VERSION ""

NS_ :

BS_:

BU_: BMS_Controller NF_Controller NF_Controllers

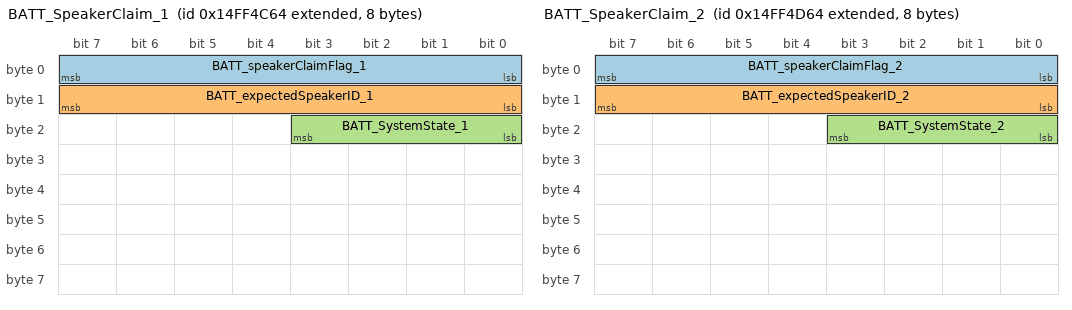
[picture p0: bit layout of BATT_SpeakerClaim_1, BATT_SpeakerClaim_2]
BO_ 2499759204 BATT_SpeakerClaim_1: 8 BMS_Controller
 SG_ BATT_speakerClaimFlag_1 : 0|8@1+ (1,0) [0|255] ""  BMS_Controller
 SG_ BATT_expectedSpeakerID_1 : 8|8@1+ (1,0) [0|255] ""  BMS_Controller
 SG_ BATT_SystemState_1 : 16|4@1+ (1,0) [0|15] ""  BMS_Controller

BO_ 2499759460 BATT_SpeakerClaim_2: 8 BMS_Controller
 SG_ BATT_speakerClaimFlag_2 : 0|8@1+ (1,0) [0|255] ""  BMS_Controller
 SG_ BATT_expectedSpeakerID_2 : 8|8@1+ (1,0) [0|255] ""  BMS_Controller
 SG_ BATT_SystemState_2 : 16|4@1+ (1,0) [0|15] ""  BMS_Controller

BO_ 2499756361 APP_PackId_Arbitration: 8 NF_Controller
 SG_ APP_PackId_Arbitration_Req : 0|8@1+ (1,0) [0|255] ""  BMS_Controller

BO_ 2499758692 BATT_Version: 8 BMS_Controller
 SG_ BATT_SwVerSubMinorApp m0 : 24|8@1+ (1,0) [0|255] ""  NF_Controller
 SG_ BATT_SwVerMinorApp m0 : 16|8@1+ (1,0) [0|255] ""  NF_Controller
 SG_ BATT_SwVerMajorApp m0 : 8|8@1+ (1,0) [0|255] ""  NF_Controller
 SG_ BATT_HwVerApp m0 : 32|8@1+ (1,0) [0|255] ""  NF_Controller
 SG_ BATT_SwVerAbsCusApp m0 : 40|8@1+ (1,0) [0|255] ""  NF_Controller
 SG_ BATT_SwVerAbsIntApp m0 : 48|8@1+ (1,0) [0|255] ""  NF_Controller
 SG_ BATT_SwVerSubMinorBl m1 : 24|8@1+ (1,0) [0|255] ""  NF_Controller
 SG_ BATT_SwVerMinorBl m1 : 16|8@1+ (1,0) [0|255] ""  NF_Controller
 SG_ BATT_SwVerMajorBl m1 : 8|8@1+ (1,0) [0|255] ""  NF_Controller
 SG_ BATT_HwVerBl m1 : 32|8@1+ (1,0) [0|255] ""  NF_Controller
 SG_ BATT_SwVerAbsCusBl m1 : 40|8@1+ (1,0) [0|255] ""  NF_Controller
 SG_ BATT_SwVerAbsIntBl m1 : 48|8@1+ (1,0) [0|255] ""  NF_Controller
 SG_ BATT_SwVerSubMinorCal m2 : 24|8@1+ (1,0) [0|255] ""  NF_Controller
 SG_ BATT_SwVerMinorCal m2 : 16|8@1+ (1,0) [0|255] ""  NF_Controller
 SG_ BATT_SwVerMajorCal m2 : 8|8@1+ (1,0) [0|255] ""  NF_Controller
 SG_ BATT_HwVerCal m2 : 32|8@1+ (1,0) [0|255] ""  NF_Controller
 SG_ BATT_SwVerAbsCusCal m2 : 40|8@1+ (1,0) [0|255] ""  NF_Controller
 SG_ BATT_SwVerAbsIntCal m2 : 48|8@1+ (1,0) [0|255] ""  NF_Controller
 SG_ multiplexorvr M : 0|2@1+ (1,0) [0|2] ""  NF_Controllers

BO_ 2499763812 BATT_Pack_Inhibition: 8 BMS_Controller
 SG_ BATT_01_inhibitionPyroFuse m0 : 11|1@1+ (1,0) [0|1] ""  NF_Controller
 SG_ BATT_01_inhibitionRegen m0 : 10|1@1+ (1,0) [0|1] ""  NF_Controller
 SG_ BATT_01_inhibitionFullPower m0 : 9|1@1+ (1,0) [0|1] ""  NF_Controller
 SG_ BATT_01_inhibitionRampDown m0 : 8|1@1+ (1,0) [0|1] ""  NF_Controller
 SG_ BATT_01_inhibitionDriveEntry m0 : 3|1@1+ (1,0) [0|1] ""  NF_Controller
 SG_ BATT_01_inhibitionDrive m0 : 2|1@1+ (1,0) [0|1] ""  NF_Controller
 SG_ BATT_01_inhibitionCharge m0 : 1|1@1+ (1,0) [0|1] ""  NF_Controller
 SG_ BATT_01_inhibitionChargeEntry m0 : 0|1@1+ (1,0) [0|1] ""  NF_Controller
 SG_ BATT_02_inhibitionPyroFuse m1 : 11|1@1+ (1,0) [0|1] ""  NF_Controller
 SG_ BATT_02_inhibitionRegen m1 : 10|1@1+ (1,0) [0|1] ""  NF_Controller
 SG_ BATT_02_inhibitionFullPower m1 : 9|1@1+ (1,0) [0|1] ""  NF_Controller
 SG_ BATT_02_inhibitionRampDown m1 : 8|1@1+ (1,0) [0|1] ""  NF_Controller
 SG_ BATT_02_inhibitionDriveEntry m1 : 3|1@1+ (1,0) [0|1] ""  NF_Controller
 SG_ BATT_02_inhibitionDrive m1 : 2|1@1+ (1,0) [0|1] ""  NF_Controller
 SG_ BATT_02_inhibitionCharge m1 : 1|1@1+ (1,0) [0|1] ""  NF_Controller
 SG_ BATT_02_inhibitionChargeEntry m1 : 0|1@1+ (1,0) [0|1] ""  NF_Controller
 SG_ BATT_03_inhibitionPyroFuse m2 : 11|1@1+ (1,0) [0|1] ""  NF_Controller
 SG_ BATT_03_inhibitionRegen m2 : 10|1@1+ (1,0) [0|1] ""  NF_Controller
 SG_ BATT_03_inhibitionFullPower m2 : 9|1@1+ (1,0) [0|1] ""  NF_Controller
 SG_ BATT_03_inhibitionRampDown m2 : 8|1@1+ (1,0) [0|1] ""  NF_Controller
 SG_ BATT_03_inhibitionDriveEntry m2 : 3|1@1+ (1,0) [0|1] ""  NF_Controller
 SG_ BATT_03_inhibitionDrive m2 : 2|1@1+ (1,0) [0|1] ""  NF_Controller
 SG_ BATT_03_inhibitionCharge m2 : 1|1@1+ (1,0) [0|1] ""  NF_Controller
 SG_ BATT_03_inhibitionChargeEntry m2 : 0|1@1+ (1,0) [0|1] ""  NF_Controller
 SG_ BATT_04_inhibitionPyroFuse m3 : 11|1@1+ (1,0) [0|1] ""  NF_Controller
 SG_ BATT_04_inhibitionRegen m3 : 10|1@1+ (1,0) [0|1] ""  NF_Controller
 SG_ BATT_04_inhibitionFullPower m3 : 9|1@1+ (1,0) [0|1] ""  NF_Controller
 SG_ BATT_04_inhibitionRampDown m3 : 8|1@1+ (1,0) [0|1] ""  NF_Controller
 SG_ BATT_04_inhibitionDriveEntry m3 : 3|1@1+ (1,0) [0|1] ""  NF_Controller
 SG_ BATT_04_inhibitionDrive m3 : 2|1@1+ (1,0) [0|1] ""  NF_Controller
 SG_ BATT_04_inhibitionCharge m3 : 1|1@1+ (1,0) [0|1] ""  NF_Controller
 SG_ BATT_04_inhibitionChargeEntry m3 : 0|1@1+ (1,0) [0|1] ""  NF_Controller
 SG_ BATT_05_inhibitionPyroFuse m4 : 11|1@1+ (1,0) [0|1] ""  NF_Controller
 SG_ BATT_05_inhibitionRegen m4 : 10|1@1+ (1,0) [0|1] ""  NF_Controller
 SG_ BATT_05_inhibitionFullPower m4 : 9|1@1+ (1,0) [0|1] ""  NF_Controller
 SG_ BATT_05_inhibitionRampDown m4 : 8|1@1+ (1,0) [0|1] ""  NF_Controller
 SG_ BATT_05_inhibitionDriveEntry m4 : 3|1@1+ (1,0) [0|1] ""  NF_Controller
 SG_ BATT_05_inhibitionDrive m4 : 2|1@1+ (1,0) [0|1] ""  NF_Controller
 SG_ BATT_05_inhibitionCharge m4 : 1|1@1+ (1,0) [0|1] ""  NF_Controller
 SG_ BATT_05_inhibitionChargeEntry m4 : 0|1@1+ (1,0) [0|1] ""  NF_Controller
 SG_ BATT_06_inhibitionPyroFuse m5 : 11|1@1+ (1,0) [0|1] ""  NF_Controller
 SG_ BATT_06_inhibitionRegen m5 : 10|1@1+ (1,0) [0|1] ""  NF_Controller
 SG_ BATT_06_inhibitionFullPower m5 : 9|1@1+ (1,0) [0|1] ""  NF_Controller
 SG_ BATT_06_inhibitionRampDown m5 : 8|1@1+ (1,0) [0|1] ""  NF_Controller
 SG_ BATT_06_inhibitionDriveEntry m5 : 3|1@1+ (1,0) [0|1] ""  NF_Controller
 SG_ BATT_06_inhibitionDrive m5 : 2|1@1+ (1,0) [0|1] ""  NF_Controller
 SG_ BATT_06_inhibitionCharge m5 : 1|1@1+ (1,0) [0|1] ""  NF_Controller
 SG_ BATT_06_inhibitionChargeEntry m5 : 0|1@1+ (1,0) [0|1] ""  NF_Controller
 SG_ BATT_07_inhibitionPyroFuse m6 : 11|1@1+ (1,0) [0|1] ""  NF_Controller
 SG_ BATT_07_inhibitionRegen m6 : 10|1@1+ (1,0) [0|1] ""  NF_Controller
 SG_ BATT_07_inhibitionFullPower m6 : 9|1@1+ (1,0) [0|1] ""  NF_Controller
 SG_ BATT_07_inhibitionRampDown m6 : 8|1@1+ (1,0) [0|1] ""  NF_Controller
 SG_ BATT_07_inhibitionDriveEntry m6 : 3|1@1+ (1,0) [0|1] ""  NF_Controller
 SG_ BATT_07_inhibitionDrive m6 : 2|1@1+ (1,0) [0|1] ""  NF_Controller
 SG_ BATT_07_inhibitionCharge m6 : 1|1@1+ (1,0) [0|1] ""  NF_Controller
 SG_ BATT_07_inhibitionChargeEntry m6 : 0|1@1+ (1,0) [0|1] ""  NF_Controller
 SG_ BATT_08_inhibitionPyroFuse m7 : 11|1@1+ (1,0) [0|1] ""  NF_Controller
 SG_ BATT_08_inhibitionRegen m7 : 10|1@1+ (1,0) [0|1] ""  NF_Controller
 SG_ BATT_08_inhibitionFullPower m7 : 9|1@1+ (1,0) [0|1] ""  NF_Controller
 SG_ BATT_08_inhibitionRampDown m7 : 8|1@1+ (1,0) [0|1] ""  NF_Controller
 SG_ BATT_08_inhibitionDriveEntry m7 : 3|1@1+ (1,0) [0|1] ""  NF_Controller
 SG_ BATT_08_inhibitionDrive m7 : 2|1@1+ (1,0) [0|1] ""  NF_Controller
 SG_ BATT_08_inhibitionCharge m7 : 1|1@1+ (1,0) [0|1] ""  NF_Controller
 SG_ BATT_08_inhibitionChargeEntry m7 : 0|1@1+ (1,0) [0|1] ""  NF_Controller
 SG_ BATT_09_inhibitionPyroFuse m8 : 11|1@1+ (1,0) [0|1] ""  NF_Controller
 SG_ BATT_09_inhibitionRegen m8 : 10|1@1+ (1,0) [0|1] ""  NF_Controller
 SG_ BATT_09_inhibitionFullPower m8 : 9|1@1+ (1,0) [0|1] ""  NF_Controller
 SG_ BATT_09_inhibitionRampDown m8 : 8|1@1+ (1,0) [0|1] ""  NF_Controller
 SG_ BATT_09_inhibitionDriveEntry m8 : 3|1@1+ (1,0) [0|1] ""  NF_Controller
 SG_ BATT_09_inhibitionDrive m8 : 2|1@1+ (1,0) [0|1] ""  NF_Controller
 SG_ BATT_09_inhibitionCharge m8 : 1|1@1+ (1,0) [0|1] ""  NF_Controller
 SG_ BATT_09_inhibitionChargeEntry m8 : 0|1@1+ (1,0) [0|1] ""  NF_Controller
 SG_ BATT_10_inhibitionPyroFuse m9 : 11|1@1+ (1,0) [0|1] ""  NF_Controller
 SG_ BATT_10_inhibitionRegen m9 : 10|1@1+ (1,0) [0|1] ""  NF_Controller
 SG_ BATT_10_inhibitionFullPower m9 : 9|1@1+ (1,0) [0|1] ""  NF_Controller
 SG_ BATT_10_inhibitionRampDown m9 : 8|1@1+ (1,0) [0|1] ""  NF_Controller
 SG_ BATT_10_inhibitionDriveEntry m9 : 3|1@1+ (1,0) [0|1] ""  NF_Controller
 SG_ BATT_10_inhibitionDrive m9 : 2|1@1+ (1,0) [0|1] ""  NF_Controller
 SG_ BATT_10_inhibitionCharge m9 : 1|1@1+ (1,0) [0|1] ""  NF_Controller
 SG_ BATT_10_inhibitionChargeEntry m9 : 0|1@1+ (1,0) [0|1] ""  NF_Controller
 SG_ BATT_packInhMux M : 4|4@1+ (1,0) [0|15] ""  NF_Controller

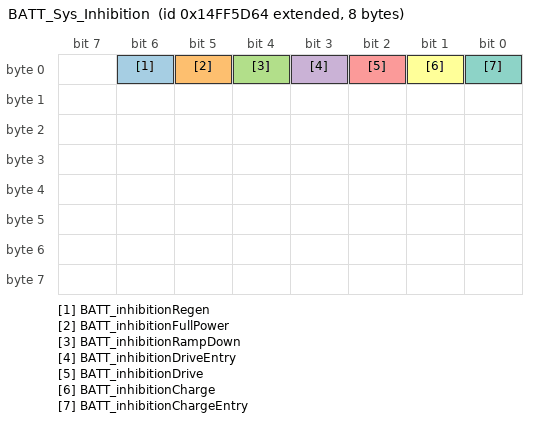
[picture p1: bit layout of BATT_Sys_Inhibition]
BO_ 2499763556 BATT_Sys_Inhibition: 8 BMS_Controller
 SG_ BATT_inhibitionRegen : 6|1@1+ (1,0) [0|1] ""  NF_Controller
 SG_ BATT_inhibitionFullPower : 5|1@1+ (1,0) [0|1] ""  NF_Controller
 SG_ BATT_inhibitionRampDown : 4|1@1+ (1,0) [0|1] ""  NF_Controller
 SG_ BATT_inhibitionDriveEntry : 3|1@1+ (1,0) [0|1] ""  NF_Controller
 SG_ BATT_inhibitionDrive : 2|1@1+ (1,0) [0|1] ""  NF_Controller
 SG_ BATT_inhibitionCharge : 1|1@1+ (1,0) [0|1] ""  NF_Controller
 SG_ BATT_inhibitionChargeEntry : 0|1@1+ (1,0) [0|1] ""  NF_Controller

BO_ 2499763300 BATT_Diagnostic_Pack_D: 8 BMS_Controller
 SG_ BATT_01_BusJoinFailed m0 : 10|2@1+ (1,0) [0|3] ""  NF_Controller
 SG_ BATT_01_ModuleThermFaultSevere m0 : 8|2@1+ (1,0) [0|3] ""  NF_Controller
 SG_ BATT_01_Placeholder11 m0 : 22|2@1+ (1,0) [0|3] ""  NF_Controller
 SG_ BATT_01_HardwareUvloError m0 : 20|2@1+ (1,0) [0|3] ""  NF_Controller
 SG_ BATT_01_iOverchargemod m0 : 46|2@1+ (1,0) [0|3] ""  NF_Controller
 SG_ BATT_01_afe_pwr_wire_open m0 : 44|2@1+ (1,0) [0|3] ""  NF_Controller
 SG_ BATT_01_HardwareOVError m0 : 18|2@1+ (1,0) [0|3] ""  NF_Controller
 SG_ BATT_01_DoubleDcContWeld m0 : 16|2@1+ (1,0) [0|3] ""  NF_Controller
 SG_ BATT_01_CurrentMismatch m0 : 30|2@1+ (1,0) [0|3] ""  NF_Controller
 SG_ BATT_01_vBrickImbalanceWar m0 : 28|2@1+ (1,0) [0|3] ""  NF_Controller
 SG_ BATT_01_vBrickImbalanceMod m0 : 26|2@1+ (1,0) [0|3] ""  NF_Controller
 SG_ BATT_01_vBrickImbalanceSev m0 : 24|2@1+ (1,0) [0|3] ""  NF_Controller
 SG_ BATT_01_Placeholder06 m0 : 38|2@1+ (1,0) [0|3] ""  NF_Controller
 SG_ BATT_01_iOverdischargewar m0 : 36|2@1+ (1,0) [0|3] ""  NF_Controller
 SG_ BATT_01_SpeakerMia m0 : 2|2@1+ (1,0) [0|3] ""  NF_Controller
 SG_ BATT_01_IsoSpiBreak m0 : 0|2@1+ (1,0) [0|3] ""  NF_Controller
 SG_ BATT_01_VersionMismatch m0 : 14|2@1+ (1,0) [0|3] ""  NF_Controller
 SG_ BATT_01_SystemPrechargeFail m0 : 12|2@1+ (1,0) [0|3] ""  NF_Controller
 SG_ BATT_01_iOverdischargemod m0 : 34|2@1+ (1,0) [0|3] ""  NF_Controller
 SG_ BATT_01_iOverchargeswar m0 : 32|2@1+ (1,0) [0|3] ""  NF_Controller
 SG_ BATT_02_BusJoinFailed m1 : 10|2@1+ (1,0) [0|3] ""  NF_Controller
 SG_ BATT_02_ModuleThermFaultSevere m1 : 8|2@1+ (1,0) [0|3] ""  NF_Controller
 SG_ BATT_02_Placeholder11 m1 : 22|2@1+ (1,0) [0|3] ""  NF_Controller
 SG_ BATT_02_HardwareUvloError m1 : 20|2@1+ (1,0) [0|3] ""  NF_Controller
 SG_ BATT_02_iOverchargemod m1 : 46|2@1+ (1,0) [0|3] ""  NF_Controller
 SG_ BATT_02_afe_pwr_wire_open m1 : 44|2@1+ (1,0) [0|3] ""  NF_Controller
 SG_ BATT_02_HardwareOVError m1 : 18|2@1+ (1,0) [0|3] ""  NF_Controller
 SG_ BATT_02_DoubleDcContWeld m1 : 16|2@1+ (1,0) [0|3] ""  NF_Controller
 SG_ BATT_02_CurrentMismatch m1 : 30|2@1+ (1,0) [0|3] ""  NF_Controller
 SG_ BATT_02_vBrickImbalanceWar m1 : 28|2@1+ (1,0) [0|3] ""  NF_Controller
 SG_ BATT_02_vBrickImbalanceMod m1 : 26|2@1+ (1,0) [0|3] ""  NF_Controller
 SG_ BATT_02_vBrickImbalanceSev m1 : 24|2@1+ (1,0) [0|3] ""  NF_Controller
 SG_ BATT_02_Placeholder06 m1 : 38|2@1+ (1,0) [0|3] ""  NF_Controller
 SG_ BATT_02_iOverdischargewar m1 : 36|2@1+ (1,0) [0|3] ""  NF_Controller
 SG_ BATT_02_SpeakerMia m1 : 2|2@1+ (1,0) [0|3] ""  NF_Controller
 SG_ BATT_02_IsoSpiBreak m1 : 0|2@1+ (1,0) [0|3] ""  NF_Controller
 SG_ BATT_02_VersionMismatch m1 : 14|2@1+ (1,0) [0|3] ""  NF_Controller
 SG_ BATT_02_SystemPrechargeFail m1 : 12|2@1+ (1,0) [0|3] ""  NF_Controller
 SG_ BATT_02_iOverdischargemod m1 : 34|2@1+ (1,0) [0|3] ""  NF_Controller
 SG_ BATT_02_iOverchargeswar m1 : 32|2@1+ (1,0) [0|3] ""  NF_Controller
 SG_ BATT_03_BusJoinFailed m2 : 10|2@1+ (1,0) [0|3] ""  NF_Controller
 SG_ BATT_03_ModuleThermFaultSevere m2 : 8|2@1+ (1,0) [0|3] ""  NF_Controller
 SG_ BATT_03_Placeholder11 m2 : 22|2@1+ (1,0) [0|3] ""  NF_Controller
 SG_ BATT_03_HardwareUvloError m2 : 20|2@1+ (1,0) [0|3] ""  NF_Controller
 SG_ BATT_03_iOverchargemod m2 : 46|2@1+ (1,0) [0|3] ""  NF_Controller
 SG_ BATT_03_afe_pwr_wire_open m2 : 44|2@1+ (1,0) [0|3] ""  NF_Controller
 SG_ BATT_03_HardwareOVError m2 : 18|2@1+ (1,0) [0|3] ""  NF_Controller
 SG_ BATT_03_DoubleDcContWeld m2 : 16|2@1+ (1,0) [0|3] ""  NF_Controller
 SG_ BATT_03_CurrentMismatch m2 : 30|2@1+ (1,0) [0|3] ""  NF_Controller
 SG_ BATT_03_vBrickImbalanceWar m2 : 28|2@1+ (1,0) [0|3] ""  NF_Controller
 SG_ BATT_03_vBrickImbalanceMod m2 : 26|2@1+ (1,0) [0|3] ""  NF_Controller
 SG_ BATT_03_vBrickImbalanceSev m2 : 24|2@1+ (1,0) [0|3] ""  NF_Controller
 SG_ BATT_03_Placeholder06 m2 : 38|2@1+ (1,0) [0|3] ""  NF_Controller
 SG_ BATT_03_iOverdischargewar m2 : 36|2@1+ (1,0) [0|3] ""  NF_Controller
 SG_ BATT_03_SpeakerMia m2 : 2|2@1+ (1,0) [0|3] ""  NF_Controller
 SG_ BATT_03_IsoSpiBreak m2 : 0|2@1+ (1,0) [0|3] ""  NF_Controller
 SG_ BATT_03_VersionMismatch m2 : 14|2@1+ (1,0) [0|3] ""  NF_Controller
 SG_ BATT_03_SystemPrechargeFail m2 : 12|2@1+ (1,0) [0|3] ""  NF_Controller
 SG_ BATT_03_iOverdischargemod m2 : 34|2@1+ (1,0) [0|3] ""  NF_Controller
 SG_ BATT_03_iOverchargeswar m2 : 32|2@1+ (1,0) [0|3] ""  NF_Controller
 SG_ BATT_04_BusJoinFailed m3 : 10|2@1+ (1,0) [0|3] ""  NF_Controller
 SG_ BATT_04_ModuleThermFaultSevere m3 : 8|2@1+ (1,0) [0|3] ""  NF_Controller
 SG_ BATT_04_Placeholder11 m3 : 22|2@1+ (1,0) [0|3] ""  NF_Controller
 SG_ BATT_04_HardwareUvloError m3 : 20|2@1+ (1,0) [0|3] ""  NF_Controller
 SG_ BATT_04_iOverchargemod m3 : 46|2@1+ (1,0) [0|3] ""  NF_Controller
 SG_ BATT_04_afe_pwr_wire_open m3 : 44|2@1+ (1,0) [0|3] ""  NF_Controller
 SG_ BATT_04_HardwareOVError m3 : 18|2@1+ (1,0) [0|3] ""  NF_Controller
 SG_ BATT_04_DoubleDcContWeld m3 : 16|2@1+ (1,0) [0|3] ""  NF_Controller
 SG_ BATT_04_CurrentMismatch m3 : 30|2@1+ (1,0) [0|3] ""  NF_Controller
 SG_ BATT_04_vBrickImbalanceWar m3 : 28|2@1+ (1,0) [0|3] ""  NF_Controller
 SG_ BATT_04_vBrickImbalanceMod m3 : 26|2@1+ (1,0) [0|3] ""  NF_Controller
 SG_ BATT_04_vBrickImbalanceSev m3 : 24|2@1+ (1,0) [0|3] ""  NF_Controller
 SG_ BATT_04_Placeholder06 m3 : 38|2@1+ (1,0) [0|3] ""  NF_Controller
 SG_ BATT_04_iOverdischargewar m3 : 36|2@1+ (1,0) [0|3] ""  NF_Controller
 SG_ BATT_04_SpeakerMia m3 : 2|2@1+ (1,0) [0|3] ""  NF_Controller
 SG_ BATT_04_IsoSpiBreak m3 : 0|2@1+ (1,0) [0|3] ""  NF_Controller
 SG_ BATT_04_VersionMismatch m3 : 14|2@1+ (1,0) [0|3] ""  NF_Controller
 SG_ BATT_04_SystemPrechargeFail m3 : 12|2@1+ (1,0) [0|3] ""  NF_Controller
 SG_ BATT_04_iOverdischargemod m3 : 34|2@1+ (1,0) [0|3] ""  NF_Controller
 SG_ BATT_04_iOverchargeswar m3 : 32|2@1+ (1,0) [0|3] ""  NF_Controller
 SG_ BATT_05_BusJoinFailed m4 : 10|2@1+ (1,0) [0|3] ""  NF_Controller
 SG_ BATT_05_ModuleThermFaultSevere m4 : 8|2@1+ (1,0) [0|3] ""  NF_Controller
 SG_ BATT_05_Placeholder11 m4 : 22|2@1+ (1,0) [0|3] ""  NF_Controller
 SG_ BATT_05_HardwareUvloError m4 : 20|2@1+ (1,0) [0|3] ""  NF_Controller
 SG_ BATT_05_iOverchargemod m4 : 46|2@1+ (1,0) [0|3] ""  NF_Controller
 SG_ BATT_05_afe_pwr_wire_open m4 : 44|2@1+ (1,0) [0|3] ""  NF_Controller
 SG_ BATT_05_HardwareOVError m4 : 18|2@1+ (1,0) [0|3] ""  NF_Controller
 SG_ BATT_05_DoubleDcContWeld m4 : 16|2@1+ (1,0) [0|3] ""  NF_Controller
 SG_ BATT_05_CurrentMismatch m4 : 30|2@1+ (1,0) [0|3] ""  NF_Controller
 SG_ BATT_05_vBrickImbalanceWar m4 : 28|2@1+ (1,0) [0|3] ""  NF_Controller
 SG_ BATT_05_vBrickImbalanceMod m4 : 26|2@1+ (1,0) [0|3] ""  NF_Controller
 SG_ BATT_05_vBrickImbalanceSev m4 : 24|2@1+ (1,0) [0|3] ""  NF_Controller
 SG_ BATT_05_Placeholder06 m4 : 38|2@1+ (1,0) [0|3] ""  NF_Controller
 SG_ BATT_05_iOverdischargewar m4 : 36|2@1+ (1,0) [0|3] ""  NF_Controller
 SG_ BATT_05_SpeakerMia m4 : 2|2@1+ (1,0) [0|3] ""  NF_Controller
 SG_ BATT_05_IsoSpiBreak m4 : 0|2@1+ (1,0) [0|3] ""  NF_Controller
 SG_ BATT_05_VersionMismatch m4 : 14|2@1+ (1,0) [0|3] ""  NF_Controller
 SG_ BATT_05_SystemPrechargeFail m4 : 12|2@1+ (1,0) [0|3] ""  NF_Controller
 SG_ BATT_05_iOverdischargemod m4 : 34|2@1+ (1,0) [0|3] ""  NF_Controller
 SG_ BATT_05_iOverchargeswar m4 : 32|2@1+ (1,0) [0|3] ""  NF_Controller
 SG_ BATT_06_BusJoinFailed m5 : 10|2@1+ (1,0) [0|3] ""  NF_Controller
 SG_ BATT_06_ModuleThermFaultSevere m5 : 8|2@1+ (1,0) [0|3] ""  NF_Controller
 SG_ BATT_06_Placeholder11 m5 : 22|2@1+ (1,0) [0|3] ""  NF_Controller
 SG_ BATT_06_HardwareUvloError m5 : 20|2@1+ (1,0) [0|3] ""  NF_Controller
 SG_ BATT_06_iOverchargemod m5 : 46|2@1+ (1,0) [0|3] ""  NF_Controller
 SG_ BATT_06_afe_pwr_wire_open m5 : 44|2@1+ (1,0) [0|3] ""  NF_Controller
 SG_ BATT_06_HardwareOVError m5 : 18|2@1+ (1,0) [0|3] ""  NF_Controller
 SG_ BATT_06_DoubleDcContWeld m5 : 16|2@1+ (1,0) [0|3] ""  NF_Controller
 SG_ BATT_06_CurrentMismatch m5 : 30|2@1+ (1,0) [0|3] ""  NF_Controller
 SG_ BATT_06_vBrickImbalanceWar m5 : 28|2@1+ (1,0) [0|3] ""  NF_Controller
 SG_ BATT_06_vBrickImbalanceMod m5 : 26|2@1+ (1,0) [0|3] ""  NF_Controller
 SG_ BATT_06_vBrickImbalanceSev m5 : 24|2@1+ (1,0) [0|3] ""  NF_Controller
 SG_ BATT_06_Placeholder06 m5 : 38|2@1+ (1,0) [0|3] ""  NF_Controller
 SG_ BATT_06_iOverdischargewar m5 : 36|2@1+ (1,0) [0|3] ""  NF_Controller
 SG_ BATT_06_SpeakerMia m5 : 2|2@1+ (1,0) [0|3] ""  NF_Controller
 SG_ BATT_06_IsoSpiBreak m5 : 0|2@1+ (1,0) [0|3] ""  NF_Controller
 SG_ BATT_06_VersionMismatch m5 : 14|2@1+ (1,0) [0|3] ""  NF_Controller
 SG_ BATT_06_SystemPrechargeFail m5 : 12|2@1+ (1,0) [0|3] ""  NF_Controller
 SG_ BATT_06_iOverdischargemod m5 : 34|2@1+ (1,0) [0|3] ""  NF_Controller
 SG_ BATT_06_iOverchargeswar m5 : 32|2@1+ (1,0) [0|3] ""  NF_Controller
 SG_ BATT_07_BusJoinFailed m6 : 10|2@1+ (1,0) [0|3] ""  NF_Controller
 SG_ BATT_07_ModuleThermFaultSevere m6 : 8|2@1+ (1,0) [0|3] ""  NF_Controller
 SG_ BATT_07_Placeholder11 m6 : 22|2@1+ (1,0) [0|3] ""  NF_Controller
 SG_ BATT_07_HardwareUvloError m6 : 20|2@1+ (1,0) [0|3] ""  NF_Controller
 SG_ BATT_07_iOverchargemod m6 : 46|2@1+ (1,0) [0|3] ""  NF_Controller
 SG_ BATT_07_afe_pwr_wire_open m6 : 44|2@1+ (1,0) [0|3] ""  NF_Controller
 SG_ BATT_07_HardwareOVError m6 : 18|2@1+ (1,0) [0|3] ""  NF_Controller
 SG_ BATT_07_DoubleDcContWeld m6 : 16|2@1+ (1,0) [0|3] ""  NF_Controller
 SG_ BATT_07_CurrentMismatch m6 : 30|2@1+ (1,0) [0|3] ""  NF_Controller
 SG_ BATT_07_vBrickImbalanceWar m6 : 28|2@1+ (1,0) [0|3] ""  NF_Controller
 SG_ BATT_07_vBrickImbalanceMod m6 : 26|2@1+ (1,0) [0|3] ""  NF_Controller
 SG_ BATT_07_vBrickImbalanceSev m6 : 24|2@1+ (1,0) [0|3] ""  NF_Controller
 SG_ BATT_07_Placeholder06 m6 : 38|2@1+ (1,0) [0|3] ""  NF_Controller
 SG_ BATT_07_iOverdischargewar m6 : 36|2@1+ (1,0) [0|3] ""  NF_Controller
 SG_ BATT_07_SpeakerMia m6 : 2|2@1+ (1,0) [0|3] ""  NF_Controller
 SG_ BATT_07_IsoSpiBreak m6 : 0|2@1+ (1,0) [0|3] ""  NF_Controller
 SG_ BATT_07_VersionMismatch m6 : 14|2@1+ (1,0) [0|3] ""  NF_Controller
 SG_ BATT_07_SystemPrechargeFail m6 : 12|2@1+ (1,0) [0|3] ""  NF_Controller
 SG_ BATT_07_iOverdischargemod m6 : 34|2@1+ (1,0) [0|3] ""  NF_Controller
 SG_ BATT_07_iOverchargeswar m6 : 32|2@1+ (1,0) [0|3] ""  NF_Controller
 SG_ BATT_08_BusJoinFailed m7 : 10|2@1+ (1,0) [0|3] ""  NF_Controller
 SG_ BATT_08_ModuleThermFaultSevere m7 : 8|2@1+ (1,0) [0|3] ""  NF_Controller
 SG_ BATT_08_Placeholder11 m7 : 22|2@1+ (1,0) [0|3] ""  NF_Controller
 SG_ BATT_08_HardwareUvloError m7 : 20|2@1+ (1,0) [0|3] ""  NF_Controller
 SG_ BATT_08_iOverchargemod m7 : 46|2@1+ (1,0) [0|3] ""  NF_Controller
 SG_ BATT_08_afe_pwr_wire_open m7 : 44|2@1+ (1,0) [0|3] ""  NF_Controller
 SG_ BATT_08_HardwareOVError m7 : 18|2@1+ (1,0) [0|3] ""  NF_Controller
 SG_ BATT_08_DoubleDcContWeld m7 : 16|2@1+ (1,0) [0|3] ""  NF_Controller
 SG_ BATT_08_CurrentMismatch m7 : 30|2@1+ (1,0) [0|3] ""  NF_Controller
 SG_ BATT_08_vBrickImbalanceWar m7 : 28|2@1+ (1,0) [0|3] ""  NF_Controller
 SG_ BATT_08_vBrickImbalanceMod m7 : 26|2@1+ (1,0) [0|3] ""  NF_Controller
 SG_ BATT_08_vBrickImbalanceSev m7 : 24|2@1+ (1,0) [0|3] ""  NF_Controller
 SG_ BATT_08_Placeholder06 m7 : 38|2@1+ (1,0) [0|3] ""  NF_Controller
 SG_ BATT_08_iOverdischargewar m7 : 36|2@1+ (1,0) [0|3] ""  NF_Controller
 SG_ BATT_08_SpeakerMia m7 : 2|2@1+ (1,0) [0|3] ""  NF_Controller
 SG_ BATT_08_IsoSpiBreak m7 : 0|2@1+ (1,0) [0|3] ""  NF_Controller
 SG_ BATT_08_VersionMismatch m7 : 14|2@1+ (1,0) [0|3] ""  NF_Controller
 SG_ BATT_08_SystemPrechargeFail m7 : 12|2@1+ (1,0) [0|3] ""  NF_Controller
 SG_ BATT_08_iOverdischargemod m7 : 34|2@1+ (1,0) [0|3] ""  NF_Controller
 SG_ BATT_08_iOverchargeswar m7 : 32|2@1+ (1,0) [0|3] ""  NF_Controller
 SG_ BATT_09_BusJoinFailed m8 : 10|2@1+ (1,0) [0|3] ""  NF_Controller
 SG_ BATT_09_ModuleThermFaultSevere m8 : 8|2@1+ (1,0) [0|3] ""  NF_Controller
 SG_ BATT_09_Placeholder11 m8 : 22|2@1+ (1,0) [0|3] ""  NF_Controller
 SG_ BATT_09_HardwareUvloError m8 : 20|2@1+ (1,0) [0|3] ""  NF_Controller
 SG_ BATT_09_iOverchargemod m8 : 46|2@1+ (1,0) [0|3] ""  NF_Controller
 SG_ BATT_09_afe_pwr_wire_open m8 : 44|2@1+ (1,0) [0|3] ""  NF_Controller
 SG_ BATT_09_HardwareOVError m8 : 18|2@1+ (1,0) [0|3] ""  NF_Controller
 SG_ BATT_09_DoubleDcContWeld m8 : 16|2@1+ (1,0) [0|3] ""  NF_Controller
 SG_ BATT_09_CurrentMismatch m8 : 30|2@1+ (1,0) [0|3] ""  NF_Controller
 SG_ BATT_09_vBrickImbalanceWar m8 : 28|2@1+ (1,0) [0|3] ""  NF_Controller
 SG_ BATT_09_vBrickImbalanceMod m8 : 26|2@1+ (1,0) [0|3] ""  NF_Controller
 SG_ BATT_09_vBrickImbalanceSev m8 : 24|2@1+ (1,0) [0|3] ""  NF_Controller
 SG_ BATT_09_Placeholder06 m8 : 38|2@1+ (1,0) [0|3] ""  NF_Controller
 SG_ BATT_09_iOverdischargewar m8 : 36|2@1+ (1,0) [0|3] ""  NF_Controller
 SG_ BATT_09_SpeakerMia m8 : 2|2@1+ (1,0) [0|3] ""  NF_Controller
 SG_ BATT_09_IsoSpiBreak m8 : 0|2@1+ (1,0) [0|3] ""  NF_Controller
 SG_ BATT_09_VersionMismatch m8 : 14|2@1+ (1,0) [0|3] ""  NF_Controller
 SG_ BATT_09_SystemPrechargeFail m8 : 12|2@1+ (1,0) [0|3] ""  NF_Controller
 SG_ BATT_09_iOverdischargemod m8 : 34|2@1+ (1,0) [0|3] ""  NF_Controller
 SG_ BATT_09_iOverchargeswar m8 : 32|2@1+ (1,0) [0|3] ""  NF_Controller
 SG_ BATT_10_BusJoinFailed m9 : 10|2@1+ (1,0) [0|3] ""  NF_Controller
 SG_ BATT_10_ModuleThermFaultSevere m9 : 8|2@1+ (1,0) [0|3] ""  NF_Controller
 SG_ BATT_10_Placeholder11 m9 : 22|2@1+ (1,0) [0|3] ""  NF_Controller
 SG_ BATT_10_HardwareUvloError m9 : 20|2@1+ (1,0) [0|3] ""  NF_Controller
 SG_ BATT_10_iOverchargemod m9 : 46|2@1+ (1,0) [0|3] ""  NF_Controller
 SG_ BATT_10_afe_pwr_wire_open m9 : 44|2@1+ (1,0) [0|3] ""  NF_Controller
 SG_ BATT_10_HardwareOVError m9 : 18|2@1+ (1,0) [0|3] ""  NF_Controller
 SG_ BATT_10_DoubleDcContWeld m9 : 16|2@1+ (1,0) [0|3] ""  NF_Controller
 SG_ BATT_10_CurrentMismatch m9 : 30|2@1+ (1,0) [0|3] ""  NF_Controller
 SG_ BATT_10_vBrickImbalanceWar m9 : 28|2@1+ (1,0) [0|3] ""  NF_Controller
 SG_ BATT_10_vBrickImbalanceMod m9 : 26|2@1+ (1,0) [0|3] ""  NF_Controller
 SG_ BATT_10_vBrickImbalanceSev m9 : 24|2@1+ (1,0) [0|3] ""  NF_Controller
 SG_ BATT_10_Placeholder06 m9 : 38|2@1+ (1,0) [0|3] ""  NF_Controller
 SG_ BATT_10_iOverdischargewar m9 : 36|2@1+ (1,0) [0|3] ""  NF_Controller
 SG_ BATT_10_SpeakerMia m9 : 2|2@1+ (1,0) [0|3] ""  NF_Controller
 SG_ BATT_10_IsoSpiBreak m9 : 0|2@1+ (1,0) [0|3] ""  NF_Controller
 SG_ BATT_10_VersionMismatch m9 : 14|2@1+ (1,0) [0|3] ""  NF_Controller
 SG_ BATT_10_SystemPrechargeFail m9 : 12|2@1+ (1,0) [0|3] ""  NF_Controller
 SG_ BATT_10_iOverdischargemod m9 : 34|2@1+ (1,0) [0|3] ""  NF_Controller
 SG_ BATT_10_iOverchargeswar m9 : 32|2@1+ (1,0) [0|3] ""  NF_Controller
 SG_ BATT_11_BusJoinFailed m10 : 10|2@1+ (1,0) [0|3] ""  NF_Controller
 SG_ BATT_11_ModuleThermFaultSevere m10 : 8|2@1+ (1,0) [0|3] ""  NF_Controller
 SG_ BATT_11_Placeholder11 m10 : 22|2@1+ (1,0) [0|3] ""  NF_Controller
 SG_ BATT_11_HardwareUvloError m10 : 20|2@1+ (1,0) [0|3] ""  NF_Controller
 SG_ BATT_11_iOverchargemod m10 : 46|2@1+ (1,0) [0|3] ""  NF_Controller
 SG_ BATT_11_afe_pwr_wire_open m10 : 44|2@1+ (1,0) [0|3] ""  NF_Controller
 SG_ BATT_11_HardwareOVError m10 : 18|2@1+ (1,0) [0|3] ""  NF_Controller
 SG_ BATT_11_DoubleDcContWeld m10 : 16|2@1+ (1,0) [0|3] ""  NF_Controller
 SG_ BATT_11_CurrentMismatch m10 : 30|2@1+ (1,0) [0|3] ""  NF_Controller
 SG_ BATT_11_vBrickImbalanceWar m10 : 28|2@1+ (1,0) [0|3] ""  NF_Controller
 SG_ BATT_11_vBrickImbalanceMod m10 : 26|2@1+ (1,0) [0|3] ""  NF_Controller
 SG_ BATT_11_vBrickImbalanceSev m10 : 24|2@1+ (1,0) [0|3] ""  NF_Controller
 SG_ BATT_11_Placeholder06 m10 : 38|2@1+ (1,0) [0|3] ""  NF_Controller
 SG_ BATT_11_iOverdischargewar m10 : 36|2@1+ (1,0) [0|3] ""  NF_Controller
 SG_ BATT_11_SpeakerMia m10 : 2|2@1+ (1,0) [0|3] ""  NF_Controller
 SG_ BATT_11_IsoSpiBreak m10 : 0|2@1+ (1,0) [0|3] ""  NF_Controller
 SG_ BATT_11_VersionMismatch m10 : 14|2@1+ (1,0) [0|3] ""  NF_Controller
 SG_ BATT_11_SystemPrechargeFail m10 : 12|2@1+ (1,0) [0|3] ""  NF_Controller
 SG_ BATT_11_iOverdischargemod m10 : 34|2@1+ (1,0) [0|3] ""  NF_Controller
 SG_ BATT_11_iOverchargeswar m10 : 32|2@1+ (1,0) [0|3] ""  NF_Controller
 SG_ BATT_12_BusJoinFailed m11 : 10|2@1+ (1,0) [0|3] ""  NF_Controller
 SG_ BATT_12_ModuleThermFaultSevere m11 : 8|2@1+ (1,0) [0|3] ""  NF_Controller
 SG_ BATT_12_Placeholder11 m11 : 22|2@1+ (1,0) [0|3] ""  NF_Controller
 SG_ BATT_12_HardwareUvloError m11 : 20|2@1+ (1,0) [0|3] ""  NF_Controller
 SG_ BATT_12_iOverchargemod m11 : 46|2@1+ (1,0) [0|3] ""  NF_Controller
 SG_ BATT_12_afe_pwr_wire_open m11 : 44|2@1+ (1,0) [0|3] ""  NF_Controller
 SG_ BATT_12_HardwareOVError m11 : 18|2@1+ (1,0) [0|3] ""  NF_Controller
 SG_ BATT_12_DoubleDcContWeld m11 : 16|2@1+ (1,0) [0|3] ""  NF_Controller
 SG_ BATT_12_CurrentMismatch m11 : 30|2@1+ (1,0) [0|3] ""  NF_Controller
 SG_ BATT_12_vBrickImbalanceWar m11 : 28|2@1+ (1,0) [0|3] ""  NF_Controller
 SG_ BATT_12_vBrickImbalanceMod m11 : 26|2@1+ (1,0) [0|3] ""  NF_Controller
 SG_ BATT_12_vBrickImbalanceSev m11 : 24|2@1+ (1,0) [0|3] ""  NF_Controller
 SG_ BATT_12_Placeholder06 m11 : 38|2@1+ (1,0) [0|3] ""  NF_Controller
 SG_ BATT_12_iOverdischargewar m11 : 36|2@1+ (1,0) [0|3] ""  NF_Controller
 SG_ BATT_12_SpeakerMia m11 : 2|2@1+ (1,0) [0|3] ""  NF_Controller
 SG_ BATT_12_IsoSpiBreak m11 : 0|2@1+ (1,0) [0|3] ""  NF_Controller
 SG_ BATT_12_VersionMismatch m11 : 14|2@1+ (1,0) [0|3] ""  NF_Controller
 SG_ BATT_12_SystemPrechargeFail m11 : 12|2@1+ (1,0) [0|3] ""  NF_Controller
 SG_ BATT_12_iOverdischargemod m11 : 34|2@1+ (1,0) [0|3] ""  NF_Controller
 SG_ BATT_12_iOverchargeswar m11 : 32|2@1+ (1,0) [0|3] ""  NF_Controller
 SG_ BATT_13_BusJoinFailed m12 : 10|2@1+ (1,0) [0|3] ""  NF_Controller
 SG_ BATT_13_ModuleThermFaultSevere m12 : 8|2@1+ (1,0) [0|3] ""  NF_Controller
 SG_ BATT_13_Placeholder11 m12 : 22|2@1+ (1,0) [0|3] ""  NF_Controller
 SG_ BATT_13_HardwareUvloError m12 : 20|2@1+ (1,0) [0|3] ""  NF_Controller
 SG_ BATT_13_iOverchargemod m12 : 46|2@1+ (1,0) [0|3] ""  NF_Controller
 SG_ BATT_13_afe_pwr_wire_open m12 : 44|2@1+ (1,0) [0|3] ""  NF_Controller
 SG_ BATT_13_HardwareOVError m12 : 18|2@1+ (1,0) [0|3] ""  NF_Controller
 SG_ BATT_13_DoubleDcContWeld m12 : 16|2@1+ (1,0) [0|3] ""  NF_Controller
 SG_ BATT_13_CurrentMismatch m12 : 30|2@1+ (1,0) [0|3] ""  NF_Controller
 SG_ BATT_13_vBrickImbalanceWar m12 : 28|2@1+ (1,0) [0|3] ""  NF_Controller
 SG_ BATT_13_vBrickImbalanceMod m12 : 26|2@1+ (1,0) [0|3] ""  NF_Controller
 SG_ BATT_13_vBrickImbalanceSev m12 : 24|2@1+ (1,0) [0|3] ""  NF_Controller
 SG_ BATT_13_Placeholder06 m12 : 38|2@1+ (1,0) [0|3] ""  NF_Controller
 SG_ BATT_13_iOverdischargewar m12 : 36|2@1+ (1,0) [0|3] ""  NF_Controller
 SG_ BATT_13_SpeakerMia m12 : 2|2@1+ (1,0) [0|3] ""  NF_Controller
 SG_ BATT_13_IsoSpiBreak m12 : 0|2@1+ (1,0) [0|3] ""  NF_Controller
 SG_ BATT_13_VersionMismatch m12 : 14|2@1+ (1,0) [0|3] ""  NF_Controller
 SG_ BATT_13_SystemPrechargeFail m12 : 12|2@1+ (1,0) [0|3] ""  NF_Controller
 SG_ BATT_13_iOverdischargemod m12 : 34|2@1+ (1,0) [0|3] ""  NF_Controller
 SG_ BATT_13_iOverchargeswar m12 : 32|2@1+ (1,0) [0|3] ""  NF_Controller
 SG_ BATT_14_BusJoinFailed m13 : 10|2@1+ (1,0) [0|3] ""  NF_Controller
 SG_ BATT_14_ModuleThermFaultSevere m13 : 8|2@1+ (1,0) [0|3] ""  NF_Controller
 SG_ BATT_14_Placeholder11 m13 : 22|2@1+ (1,0) [0|3] ""  NF_Controller
 SG_ BATT_14_HardwareUvloError m13 : 20|2@1+ (1,0) [0|3] ""  NF_Controller
 SG_ BATT_14_iOverchargemod m13 : 46|2@1+ (1,0) [0|3] ""  NF_Controller
 SG_ BATT_14_afe_pwr_wire_open m13 : 44|2@1+ (1,0) [0|3] ""  NF_Controller
 SG_ BATT_14_HardwareOVError m13 : 18|2@1+ (1,0) [0|3] ""  NF_Controller
 SG_ BATT_14_DoubleDcContWeld m13 : 16|2@1+ (1,0) [0|3] ""  NF_Controller
 SG_ BATT_14_CurrentMismatch m13 : 30|2@1+ (1,0) [0|3] ""  NF_Controller
 SG_ BATT_14_vBrickImbalanceWar m13 : 28|2@1+ (1,0) [0|3] ""  NF_Controller
 SG_ BATT_14_vBrickImbalanceMod m13 : 26|2@1+ (1,0) [0|3] ""  NF_Controller
 SG_ BATT_14_vBrickImbalanceSev m13 : 24|2@1+ (1,0) [0|3] ""  NF_Controller
 SG_ BATT_14_Placeholder06 m13 : 38|2@1+ (1,0) [0|3] ""  NF_Controller
 SG_ BATT_14_iOverdischargewar m13 : 36|2@1+ (1,0) [0|3] ""  NF_Controller
 SG_ BATT_14_SpeakerMia m13 : 2|2@1+ (1,0) [0|3] ""  NF_Controller
 SG_ BATT_14_IsoSpiBreak m13 : 0|2@1+ (1,0) [0|3] ""  NF_Controller
 SG_ BATT_14_VersionMismatch m13 : 14|2@1+ (1,0) [0|3] ""  NF_Controller
 SG_ BATT_14_SystemPrechargeFail m13 : 12|2@1+ (1,0) [0|3] ""  NF_Controller
 SG_ BATT_14_iOverdischargemod m13 : 34|2@1+ (1,0) [0|3] ""  NF_Controller
 SG_ BATT_14_iOverchargeswar m13 : 32|2@1+ (1,0) [0|3] ""  NF_Controller
 SG_ BATT_15_BusJoinFailed m14 : 10|2@1+ (1,0) [0|3] ""  NF_Controller
 SG_ BATT_15_ModuleThermFaultSevere m14 : 8|2@1+ (1,0) [0|3] ""  NF_Controller
 SG_ BATT_15_Placeholder11 m14 : 22|2@1+ (1,0) [0|3] ""  NF_Controller
 SG_ BATT_15_HardwareUvloError m14 : 20|2@1+ (1,0) [0|3] ""  NF_Controller
 SG_ BATT_15_iOverchargemod m14 : 46|2@1+ (1,0) [0|3] ""  NF_Controller
 SG_ BATT_15_afe_pwr_wire_open m14 : 44|2@1+ (1,0) [0|3] ""  NF_Controller
 SG_ BATT_15_HardwareOVError m14 : 18|2@1+ (1,0) [0|3] ""  NF_Controller
 SG_ BATT_15_DoubleDcContWeld m14 : 16|2@1+ (1,0) [0|3] ""  NF_Controller
 SG_ BATT_15_CurrentMismatch m14 : 30|2@1+ (1,0) [0|3] ""  NF_Controller
 SG_ BATT_15_vBrickImbalanceWar m14 : 28|2@1+ (1,0) [0|3] ""  NF_Controller
 SG_ BATT_15_vBrickImbalanceMod m14 : 26|2@1+ (1,0) [0|3] ""  NF_Controller
 SG_ BATT_15_vBrickImbalanceSev m14 : 24|2@1+ (1,0) [0|3] ""  NF_Controller
 SG_ BATT_15_Placeholder06 m14 : 38|2@1+ (1,0) [0|3] ""  NF_Controller
 SG_ BATT_15_iOverdischargewar m14 : 36|2@1+ (1,0) [0|3] ""  NF_Controller
 SG_ BATT_15_SpeakerMia m14 : 2|2@1+ (1,0) [0|3] ""  NF_Controller
 SG_ BATT_15_IsoSpiBreak m14 : 0|2@1+ (1,0) [0|3] ""  NF_Controller
 SG_ BATT_15_VersionMismatch m14 : 14|2@1+ (1,0) [0|3] ""  NF_Controller
 SG_ BATT_15_SystemPrechargeFail m14 : 12|2@1+ (1,0) [0|3] ""  NF_Controller
 SG_ BATT_15_iOverdischargemod m14 : 34|2@1+ (1,0) [0|3] ""  NF_Controller
 SG_ BATT_15_iOverchargeswar m14 : 32|2@1+ (1,0) [0|3] ""  NF_Controller
 SG_ multiplexor_batt_diag_D M : 4|4@1+ (1,0) [0|15] ""  NF_Controller

BO_ 2499763044 BATT_Diagnostic_Pack_C: 8 BMS_Controller
 SG_ BATT_01_PackVoltageImbalance m0 : 58|2@1+ (1,0) [0|3] ""  NF_Controller
 SG_ BATT_01_PrechargeOvercurrentPri m0 : 56|2@1+ (1,0) [0|3] ""  NF_Controller
 SG_ BATT_01_HVILvoltageError m0 : 2|2@1+ (1,0) [0|3] ""  NF_Controller
 SG_ BATT_01_HVILcurrentReturnError m0 : 0|2@1+ (1,0) [0|3] ""  NF_Controller
 SG_ BATT_01_PosDcContWeldedSec m0 : 14|2@1+ (1,0) [0|3] ""  NF_Controller
 SG_ BATT_01_PosDcContStuckOpenSec m0 : 12|2@1+ (1,0) [0|3] ""  NF_Controller
 SG_ BATT_01_NegDcContWeldedSec m0 : 10|2@1+ (1,0) [0|3] ""  NF_Controller
 SG_ BATT_01_NegDcContStuckOpenSec m0 : 8|2@1+ (1,0) [0|3] ""  NF_Controller
 SG_ BATT_01_IsolationIntFault m0 : 20|2@1+ (1,0) [0|3] ""  NF_Controller
 SG_ BATT_01_IsolationExtFault m0 : 18|2@1+ (1,0) [0|3] ""  NF_Controller
 SG_ BATT_01_event_12v_filter_error m0 : 16|2@1+ (1,0) [0|3] ""  NF_Controller
 SG_ BATT_01_event_hall_eff_hi_rang_e m0 : 30|2@1+ (1,0) [0|3] ""  NF_Controller
 SG_ BATT_01_event_brick_volt_sns_ope m0 : 28|2@1+ (1,0) [0|3] ""  NF_Controller
 SG_ BATT_01_event_5v_error m0 : 26|2@1+ (1,0) [0|3] ""  NF_Controller
 SG_ BATT_01_event_3_3_hot_error m0 : 24|2@1+ (1,0) [0|3] ""  NF_Controller
 SG_ BATT_01_event_12v_input_error m0 : 38|2@1+ (1,0) [0|3] ""  NF_Controller
 SG_ BATT_01_event_1_25v_error m0 : 36|2@1+ (1,0) [0|3] ""  NF_Controller
 SG_ BATT_01_event_shunt_MIA m0 : 34|2@1+ (1,0) [0|3] ""  NF_Controller
 SG_ BATT_01_event_SBC_int_reg_error m0 : 32|2@1+ (1,0) [0|3] ""  NF_Controller
 SG_ BATT_01_event_pos_3_3v_analog_er m0 : 46|2@1+ (1,0) [0|3] ""  NF_Controller
 SG_ BATT_01_event_outlt_clnt_thrm_op m0 : 44|2@1+ (1,0) [0|3] ""  NF_Controller
 SG_ BATT_01_event_neg_3_3_analog_err m0 : 42|2@1+ (1,0) [0|3] ""  NF_Controller
 SG_ BATT_01_event_inlet_clnt_thrm_op m0 : 40|2@1+ (1,0) [0|3] ""  NF_Controller
 SG_ BATT_01_event_hall_eff_lo_rang_e m0 : 54|2@1+ (1,0) [0|3] ""  NF_Controller
 SG_ BATT_01_event_outlt_clnt_thrm_sh m0 : 52|2@1+ (1,0) [0|3] ""  NF_Controller
 SG_ BATT_01_event_inlet_clnt_thrm_sh m0 : 50|2@1+ (1,0) [0|3] ""  NF_Controller
 SG_ BATT_01_event_3_3v_error m0 : 48|2@1+ (1,0) [0|3] ""  NF_Controller
 SG_ BATT_02_PackVoltageImbalance m1 : 58|2@1+ (1,0) [0|3] ""  NF_Controller
 SG_ BATT_02_PrechargeOvercurrentPri m1 : 56|2@1+ (1,0) [0|3] ""  NF_Controller
 SG_ BATT_02_HVILvoltageError m1 : 2|2@1+ (1,0) [0|3] ""  NF_Controller
 SG_ BATT_02_HVILcurrentReturnError m1 : 0|2@1+ (1,0) [0|3] ""  NF_Controller
 SG_ BATT_02_PosDcContWeldedSec m1 : 14|2@1+ (1,0) [0|3] ""  NF_Controller
 SG_ BATT_02_PosDcContStuckOpenSec m1 : 12|2@1+ (1,0) [0|3] ""  NF_Controller
 SG_ BATT_02_NegDcContWeldedSec m1 : 10|2@1+ (1,0) [0|3] ""  NF_Controller
 SG_ BATT_02_NegDcContStuckOpenSec m1 : 8|2@1+ (1,0) [0|3] ""  NF_Controller
 SG_ BATT_02_IsolationIntFault m1 : 20|2@1+ (1,0) [0|3] ""  NF_Controller
 SG_ BATT_02_IsolationExtFault m1 : 18|2@1+ (1,0) [0|3] ""  NF_Controller
 SG_ BATT_02_event_12v_filter_error m1 : 16|2@1+ (1,0) [0|3] ""  NF_Controller
 SG_ BATT_02_event_hall_eff_hi_rang_e m1 : 30|2@1+ (1,0) [0|3] ""  NF_Controller
 SG_ BATT_02_event_brick_volt_sns_ope m1 : 28|2@1+ (1,0) [0|3] ""  NF_Controller
 SG_ BATT_02_event_5v_error m1 : 26|2@1+ (1,0) [0|3] ""  NF_Controller
 SG_ BATT_02_event_3_3_hot_error m1 : 24|2@1+ (1,0) [0|3] ""  NF_Controller
 SG_ BATT_02_event_12v_input_error m1 : 38|2@1+ (1,0) [0|3] ""  NF_Controller
 SG_ BATT_02_event_1_25v_error m1 : 36|2@1+ (1,0) [0|3] ""  NF_Controller
 SG_ BATT_02_event_shunt_MIA m1 : 34|2@1+ (1,0) [0|3] ""  NF_Controller
 SG_ BATT_02_event_SBC_int_reg_error m1 : 32|2@1+ (1,0) [0|3] ""  NF_Controller
 SG_ BATT_02_event_pos_3_3v_analog_er m1 : 46|2@1+ (1,0) [0|3] ""  NF_Controller
 SG_ BATT_02_event_outlt_clnt_thrm_op m1 : 44|2@1+ (1,0) [0|3] ""  NF_Controller
 SG_ BATT_02_event_neg_3_3_analog_err m1 : 42|2@1+ (1,0) [0|3] ""  NF_Controller
 SG_ BATT_02_event_inlet_clnt_thrm_op m1 : 40|2@1+ (1,0) [0|3] ""  NF_Controller
 SG_ BATT_02_event_hall_eff_lo_rang_e m1 : 54|2@1+ (1,0) [0|3] ""  NF_Controller
 SG_ BATT_02_event_outlt_clnt_thrm_sh m1 : 52|2@1+ (1,0) [0|3] ""  NF_Controller
 SG_ BATT_02_event_inlet_clnt_thrm_sh m1 : 50|2@1+ (1,0) [0|3] ""  NF_Controller
 SG_ BATT_02_event_3_3v_error m1 : 48|2@1+ (1,0) [0|3] ""  NF_Controller
 SG_ BATT_03_PackVoltageImbalance m2 : 58|2@1+ (1,0) [0|3] ""  NF_Controller
 SG_ BATT_03_PrechargeOvercurrentPri m2 : 56|2@1+ (1,0) [0|3] ""  NF_Controller
 SG_ BATT_03_HVILvoltageError m2 : 2|2@1+ (1,0) [0|3] ""  NF_Controller
 SG_ BATT_03_HVILcurrentReturnError m2 : 0|2@1+ (1,0) [0|3] ""  NF_Controller
 SG_ BATT_03_PosDcContWeldedSec m2 : 14|2@1+ (1,0) [0|3] ""  NF_Controller
 SG_ BATT_03_PosDcContStuckOpenSec m2 : 12|2@1+ (1,0) [0|3] ""  NF_Controller
 SG_ BATT_03_NegDcContWeldedSec m2 : 10|2@1+ (1,0) [0|3] ""  NF_Controller
 SG_ BATT_03_NegDcContStuckOpenSec m2 : 8|2@1+ (1,0) [0|3] ""  NF_Controller
 SG_ BATT_03_IsolationIntFault m2 : 20|2@1+ (1,0) [0|3] ""  NF_Controller
 SG_ BATT_03_IsolationExtFault m2 : 18|2@1+ (1,0) [0|3] ""  NF_Controller
 SG_ BATT_03_event_12v_filter_error m2 : 16|2@1+ (1,0) [0|3] ""  NF_Controller
 SG_ BATT_03_event_hall_eff_hi_rang_e m2 : 30|2@1+ (1,0) [0|3] ""  NF_Controller
 SG_ BATT_03_event_brick_volt_sns_ope m2 : 28|2@1+ (1,0) [0|3] ""  NF_Controller
 SG_ BATT_03_event_5v_error m2 : 26|2@1+ (1,0) [0|3] ""  NF_Controller
 SG_ BATT_03_event_3_3_hot_error m2 : 24|2@1+ (1,0) [0|3] ""  NF_Controller
 SG_ BATT_03_event_12v_input_error m2 : 38|2@1+ (1,0) [0|3] ""  NF_Controller
 SG_ BATT_03_event_1_25v_error m2 : 36|2@1+ (1,0) [0|3] ""  NF_Controller
 SG_ BATT_03_event_shunt_MIA m2 : 34|2@1+ (1,0) [0|3] ""  NF_Controller
 SG_ BATT_03_event_SBC_int_reg_error m2 : 32|2@1+ (1,0) [0|3] ""  NF_Controller
 SG_ BATT_03_event_pos_3_3v_analog_er m2 : 46|2@1+ (1,0) [0|3] ""  NF_Controller
 SG_ BATT_03_event_outlt_clnt_thrm_op m2 : 44|2@1+ (1,0) [0|3] ""  NF_Controller
 SG_ BATT_03_event_neg_3_3_analog_err m2 : 42|2@1+ (1,0) [0|3] ""  NF_Controller
 SG_ BATT_03_event_inlet_clnt_thrm_op m2 : 40|2@1+ (1,0) [0|3] ""  NF_Controller
 SG_ BATT_03_event_hall_eff_lo_rang_e m2 : 54|2@1+ (1,0) [0|3] ""  NF_Controller
 SG_ BATT_03_event_outlt_clnt_thrm_sh m2 : 52|2@1+ (1,0) [0|3] ""  NF_Controller
 SG_ BATT_03_event_inlet_clnt_thrm_sh m2 : 50|2@1+ (1,0) [0|3] ""  NF_Controller
 SG_ BATT_03_event_3_3v_error m2 : 48|2@1+ (1,0) [0|3] ""  NF_Controller
 SG_ BATT_04_PackVoltageImbalance m3 : 58|2@1+ (1,0) [0|3] ""  NF_Controller
 SG_ BATT_04_PrechargeOvercurrentPri m3 : 56|2@1+ (1,0) [0|3] ""  NF_Controller
 SG_ BATT_04_HVILvoltageError m3 : 2|2@1+ (1,0) [0|3] ""  NF_Controller
 SG_ BATT_04_HVILcurrentReturnError m3 : 0|2@1+ (1,0) [0|3] ""  NF_Controller
 SG_ BATT_04_PosDcContWeldedSec m3 : 14|2@1+ (1,0) [0|3] ""  NF_Controller
 SG_ BATT_04_PosDcContStuckOpenSec m3 : 12|2@1+ (1,0) [0|3] ""  NF_Controller
 SG_ BATT_04_NegDcContWeldedSec m3 : 10|2@1+ (1,0) [0|3] ""  NF_Controller
 SG_ BATT_04_NegDcContStuckOpenSec m3 : 8|2@1+ (1,0) [0|3] ""  NF_Controller
 SG_ BATT_04_IsolationIntFault m3 : 20|2@1+ (1,0) [0|3] ""  NF_Controller
 SG_ BATT_04_IsolationExtFault m3 : 18|2@1+ (1,0) [0|3] ""  NF_Controller
 SG_ BATT_04_event_12v_filter_error m3 : 16|2@1+ (1,0) [0|3] ""  NF_Controller
 SG_ BATT_04_event_hall_eff_hi_rang_e m3 : 30|2@1+ (1,0) [0|3] ""  NF_Controller
 SG_ BATT_04_event_brick_volt_sns_ope m3 : 28|2@1+ (1,0) [0|3] ""  NF_Controller
 SG_ BATT_04_event_5v_error m3 : 26|2@1+ (1,0) [0|3] ""  NF_Controller
 SG_ BATT_04_event_3_3_hot_error m3 : 24|2@1+ (1,0) [0|3] ""  NF_Controller
 SG_ BATT_04_event_12v_input_error m3 : 38|2@1+ (1,0) [0|3] ""  NF_Controller
 SG_ BATT_04_event_1_25v_error m3 : 36|2@1+ (1,0) [0|3] ""  NF_Controller
 SG_ BATT_04_event_shunt_MIA m3 : 34|2@1+ (1,0) [0|3] ""  NF_Controller
 SG_ BATT_04_event_SBC_int_reg_error m3 : 32|2@1+ (1,0) [0|3] ""  NF_Controller
 SG_ BATT_04_event_pos_3_3v_analog_er m3 : 46|2@1+ (1,0) [0|3] ""  NF_Controller
 SG_ BATT_04_event_outlt_clnt_thrm_op m3 : 44|2@1+ (1,0) [0|3] ""  NF_Controller
 SG_ BATT_04_event_neg_3_3_analog_err m3 : 42|2@1+ (1,0) [0|3] ""  NF_Controller
 SG_ BATT_04_event_inlet_clnt_thrm_op m3 : 40|2@1+ (1,0) [0|3] ""  NF_Controller
 SG_ BATT_04_event_hall_eff_lo_rang_e m3 : 54|2@1+ (1,0) [0|3] ""  NF_Controller
 SG_ BATT_04_event_outlt_clnt_thrm_sh m3 : 52|2@1+ (1,0) [0|3] ""  NF_Controller
 SG_ BATT_04_event_inlet_clnt_thrm_sh m3 : 50|2@1+ (1,0) [0|3] ""  NF_Controller
 SG_ BATT_04_event_3_3v_error m3 : 48|2@1+ (1,0) [0|3] ""  NF_Controller
 SG_ BATT_05_PackVoltageImbalance m4 : 58|2@1+ (1,0) [0|3] ""  NF_Controller
 SG_ BATT_05_PrechargeOvercurrentPri m4 : 56|2@1+ (1,0) [0|3] ""  NF_Controller
 SG_ BATT_05_HVILvoltageError m4 : 2|2@1+ (1,0) [0|3] ""  NF_Controller
 SG_ BATT_05_HVILcurrentReturnError m4 : 0|2@1+ (1,0) [0|3] ""  NF_Controller
 SG_ BATT_05_PosDcContWeldedSec m4 : 14|2@1+ (1,0) [0|3] ""  NF_Controller
 SG_ BATT_05_PosDcContStuckOpenSec m4 : 12|2@1+ (1,0) [0|3] ""  NF_Controller
 SG_ BATT_05_NegDcContWeldedSec m4 : 10|2@1+ (1,0) [0|3] ""  NF_Controller
 SG_ BATT_05_NegDcContStuckOpenSec m4 : 8|2@1+ (1,0) [0|3] ""  NF_Controller
 SG_ BATT_05_IsolationIntFault m4 : 20|2@1+ (1,0) [0|3] ""  NF_Controller
 SG_ BATT_05_IsolationExtFault m4 : 18|2@1+ (1,0) [0|3] ""  NF_Controller
 SG_ BATT_05_event_12v_filter_error m4 : 16|2@1+ (1,0) [0|3] ""  NF_Controller
 SG_ BATT_05_event_hall_eff_hi_rang_e m4 : 30|2@1+ (1,0) [0|3] ""  NF_Controller
 SG_ BATT_05_event_brick_volt_sns_ope m4 : 28|2@1+ (1,0) [0|3] ""  NF_Controller
 SG_ BATT_05_event_5v_error m4 : 26|2@1+ (1,0) [0|3] ""  NF_Controller
 SG_ BATT_05_event_3_3_hot_error m4 : 24|2@1+ (1,0) [0|3] ""  NF_Controller
 SG_ BATT_05_event_12v_input_error m4 : 38|2@1+ (1,0) [0|3] ""  NF_Controller
 SG_ BATT_05_event_1_25v_error m4 : 36|2@1+ (1,0) [0|3] ""  NF_Controller
 SG_ BATT_05_event_shunt_MIA m4 : 34|2@1+ (1,0) [0|3] ""  NF_Controller
 SG_ BATT_05_event_SBC_int_reg_error m4 : 32|2@1+ (1,0) [0|3] ""  NF_Controller
 SG_ BATT_05_event_pos_3_3v_analog_er m4 : 46|2@1+ (1,0) [0|3] ""  NF_Controller
 SG_ BATT_05_event_outlt_clnt_thrm_op m4 : 44|2@1+ (1,0) [0|3] ""  NF_Controller
 SG_ BATT_05_event_neg_3_3_analog_err m4 : 42|2@1+ (1,0) [0|3] ""  NF_Controller
 SG_ BATT_05_event_inlet_clnt_thrm_op m4 : 40|2@1+ (1,0) [0|3] ""  NF_Controller
 SG_ BATT_05_event_hall_eff_lo_rang_e m4 : 54|2@1+ (1,0) [0|3] ""  NF_Controller
 SG_ BATT_05_event_outlt_clnt_thrm_sh m4 : 52|2@1+ (1,0) [0|3] ""  NF_Controller
 SG_ BATT_05_event_inlet_clnt_thrm_sh m4 : 50|2@1+ (1,0) [0|3] ""  NF_Controller
 SG_ BATT_05_event_3_3v_error m4 : 48|2@1+ (1,0) [0|3] ""  NF_Controller
 SG_ BATT_06_PackVoltageImbalance m5 : 58|2@1+ (1,0) [0|3] ""  NF_Controller
 SG_ BATT_06_PrechargeOvercurrentPri m5 : 56|2@1+ (1,0) [0|3] ""  NF_Controller
 SG_ BATT_06_HVILvoltageError m5 : 2|2@1+ (1,0) [0|3] ""  NF_Controller
 SG_ BATT_06_HVILcurrentReturnError m5 : 0|2@1+ (1,0) [0|3] ""  NF_Controller
 SG_ BATT_06_PosDcContWeldedSec m5 : 14|2@1+ (1,0) [0|3] ""  NF_Controller
 SG_ BATT_06_PosDcContStuckOpenSec m5 : 12|2@1+ (1,0) [0|3] ""  NF_Controller
 SG_ BATT_06_NegDcContWeldedSec m5 : 10|2@1+ (1,0) [0|3] ""  NF_Controller
 SG_ BATT_06_NegDcContStuckOpenSec m5 : 8|2@1+ (1,0) [0|3] ""  NF_Controller
 SG_ BATT_06_IsolationIntFault m5 : 20|2@1+ (1,0) [0|3] ""  NF_Controller
 SG_ BATT_06_IsolationExtFault m5 : 18|2@1+ (1,0) [0|3] ""  NF_Controller
 SG_ BATT_06_event_12v_filter_error m5 : 16|2@1+ (1,0) [0|3] ""  NF_Controller
 SG_ BATT_06_event_hall_eff_hi_rang_e m5 : 30|2@1+ (1,0) [0|3] ""  NF_Controller
 SG_ BATT_06_event_brick_volt_sns_ope m5 : 28|2@1+ (1,0) [0|3] ""  NF_Controller
 SG_ BATT_06_event_5v_error m5 : 26|2@1+ (1,0) [0|3] ""  NF_Controller
 SG_ BATT_06_event_3_3_hot_error m5 : 24|2@1+ (1,0) [0|3] ""  NF_Controller
 SG_ BATT_06_event_12v_input_error m5 : 38|2@1+ (1,0) [0|3] ""  NF_Controller
 SG_ BATT_06_event_1_25v_error m5 : 36|2@1+ (1,0) [0|3] ""  NF_Controller
 SG_ BATT_06_event_shunt_MIA m5 : 34|2@1+ (1,0) [0|3] ""  NF_Controller
 SG_ BATT_06_event_SBC_int_reg_error m5 : 32|2@1+ (1,0) [0|3] ""  NF_Controller
 SG_ BATT_06_event_pos_3_3v_analog_er m5 : 46|2@1+ (1,0) [0|3] ""  NF_Controller
 SG_ BATT_06_event_outlt_clnt_thrm_op m5 : 44|2@1+ (1,0) [0|3] ""  NF_Controller
 SG_ BATT_06_event_neg_3_3_analog_err m5 : 42|2@1+ (1,0) [0|3] ""  NF_Controller
 SG_ BATT_06_event_inlet_clnt_thrm_op m5 : 40|2@1+ (1,0) [0|3] ""  NF_Controller
 SG_ BATT_06_event_hall_eff_lo_rang_e m5 : 54|2@1+ (1,0) [0|3] ""  NF_Controller
 SG_ BATT_06_event_outlt_clnt_thrm_sh m5 : 52|2@1+ (1,0) [0|3] ""  NF_Controller
 SG_ BATT_06_event_inlet_clnt_thrm_sh m5 : 50|2@1+ (1,0) [0|3] ""  NF_Controller
 SG_ BATT_06_event_3_3v_error m5 : 48|2@1+ (1,0) [0|3] ""  NF_Controller
 SG_ BATT_07_PackVoltageImbalance m6 : 58|2@1+ (1,0) [0|3] ""  NF_Controller
 SG_ BATT_07_PrechargeOvercurrentPri m6 : 56|2@1+ (1,0) [0|3] ""  NF_Controller
 SG_ BATT_07_HVILvoltageError m6 : 2|2@1+ (1,0) [0|3] ""  NF_Controller
 SG_ BATT_07_HVILcurrentReturnError m6 : 0|2@1+ (1,0) [0|3] ""  NF_Controller
 SG_ BATT_07_PosDcContWeldedSec m6 : 14|2@1+ (1,0) [0|3] ""  NF_Controller
 SG_ BATT_07_PosDcContStuckOpenSec m6 : 12|2@1+ (1,0) [0|3] ""  NF_Controller
 SG_ BATT_07_NegDcContWeldedSec m6 : 10|2@1+ (1,0) [0|3] ""  NF_Controller
 SG_ BATT_07_NegDcContStuckOpenSec m6 : 8|2@1+ (1,0) [0|3] ""  NF_Controller
 SG_ BATT_07_IsolationIntFault m6 : 20|2@1+ (1,0) [0|3] ""  NF_Controller
 SG_ BATT_07_IsolationExtFault m6 : 18|2@1+ (1,0) [0|3] ""  NF_Controller
 SG_ BATT_07_event_12v_filter_error m6 : 16|2@1+ (1,0) [0|3] ""  NF_Controller
 SG_ BATT_07_event_hall_eff_hi_rang_e m6 : 30|2@1+ (1,0) [0|3] ""  NF_Controller
 SG_ BATT_07_event_brick_volt_sns_ope m6 : 28|2@1+ (1,0) [0|3] ""  NF_Controller
 SG_ BATT_07_event_5v_error m6 : 26|2@1+ (1,0) [0|3] ""  NF_Controller
 SG_ BATT_07_event_3_3_hot_error m6 : 24|2@1+ (1,0) [0|3] ""  NF_Controller
 SG_ BATT_07_event_12v_input_error m6 : 38|2@1+ (1,0) [0|3] ""  NF_Controller
 SG_ BATT_07_event_1_25v_error m6 : 36|2@1+ (1,0) [0|3] ""  NF_Controller
 SG_ BATT_07_event_shunt_MIA m6 : 34|2@1+ (1,0) [0|3] ""  NF_Controller
 SG_ BATT_07_event_SBC_int_reg_error m6 : 32|2@1+ (1,0) [0|3] ""  NF_Controller
 SG_ BATT_07_event_pos_3_3v_analog_er m6 : 46|2@1+ (1,0) [0|3] ""  NF_Controller
 SG_ BATT_07_event_outlt_clnt_thrm_op m6 : 44|2@1+ (1,0) [0|3] ""  NF_Controller
 SG_ BATT_07_event_neg_3_3_analog_err m6 : 42|2@1+ (1,0) [0|3] ""  NF_Controller
 SG_ BATT_07_event_inlet_clnt_thrm_op m6 : 40|2@1+ (1,0) [0|3] ""  NF_Controller
 SG_ BATT_07_event_hall_eff_lo_rang_e m6 : 54|2@1+ (1,0) [0|3] ""  NF_Controller
 SG_ BATT_07_event_outlt_clnt_thrm_sh m6 : 52|2@1+ (1,0) [0|3] ""  NF_Controller
 SG_ BATT_07_event_inlet_clnt_thrm_sh m6 : 50|2@1+ (1,0) [0|3] ""  NF_Controller
 SG_ BATT_07_event_3_3v_error m6 : 48|2@1+ (1,0) [0|3] ""  NF_Controller
 SG_ BATT_08_PackVoltageImbalance m7 : 58|2@1+ (1,0) [0|3] ""  NF_Controller
 SG_ BATT_08_PrechargeOvercurrentPri m7 : 56|2@1+ (1,0) [0|3] ""  NF_Controller
 SG_ BATT_08_HVILvoltageError m7 : 2|2@1+ (1,0) [0|3] ""  NF_Controller
 SG_ BATT_08_HVILcurrentReturnError m7 : 0|2@1+ (1,0) [0|3] ""  NF_Controller
 SG_ BATT_08_PosDcContWeldedSec m7 : 14|2@1+ (1,0) [0|3] ""  NF_Controller
 SG_ BATT_08_PosDcContStuckOpenSec m7 : 12|2@1+ (1,0) [0|3] ""  NF_Controller
 SG_ BATT_08_NegDcContWeldedSec m7 : 10|2@1+ (1,0) [0|3] ""  NF_Controller
 SG_ BATT_08_NegDcContStuckOpenSec m7 : 8|2@1+ (1,0) [0|3] ""  NF_Controller
 SG_ BATT_08_IsolationIntFault m7 : 20|2@1+ (1,0) [0|3] ""  NF_Controller
 SG_ BATT_08_IsolationExtFault m7 : 18|2@1+ (1,0) [0|3] ""  NF_Controller
 SG_ BATT_08_event_12v_filter_error m7 : 16|2@1+ (1,0) [0|3] ""  NF_Controller
 SG_ BATT_08_event_hall_eff_hi_rang_e m7 : 30|2@1+ (1,0) [0|3] ""  NF_Controller
 SG_ BATT_08_event_brick_volt_sns_ope m7 : 28|2@1+ (1,0) [0|3] ""  NF_Controller
 SG_ BATT_08_event_5v_error m7 : 26|2@1+ (1,0) [0|3] ""  NF_Controller
 SG_ BATT_08_event_3_3_hot_error m7 : 24|2@1+ (1,0) [0|3] ""  NF_Controller
 SG_ BATT_08_event_12v_input_error m7 : 38|2@1+ (1,0) [0|3] ""  NF_Controller
 SG_ BATT_08_event_1_25v_error m7 : 36|2@1+ (1,0) [0|3] ""  NF_Controller
 SG_ BATT_08_event_shunt_MIA m7 : 34|2@1+ (1,0) [0|3] ""  NF_Controller
 SG_ BATT_08_event_SBC_int_reg_error m7 : 32|2@1+ (1,0) [0|3] ""  NF_Controller
 SG_ BATT_08_event_pos_3_3v_analog_er m7 : 46|2@1+ (1,0) [0|3] ""  NF_Controller
 SG_ BATT_08_event_outlt_clnt_thrm_op m7 : 44|2@1+ (1,0) [0|3] ""  NF_Controller
 SG_ BATT_08_event_neg_3_3_analog_err m7 : 42|2@1+ (1,0) [0|3] ""  NF_Controller
 SG_ BATT_08_event_inlet_clnt_thrm_op m7 : 40|2@1+ (1,0) [0|3] ""  NF_Controller
 SG_ BATT_08_event_hall_eff_lo_rang_e m7 : 54|2@1+ (1,0) [0|3] ""  NF_Controller
 SG_ BATT_08_event_outlt_clnt_thrm_sh m7 : 52|2@1+ (1,0) [0|3] ""  NF_Controller
 SG_ BATT_08_event_inlet_clnt_thrm_sh m7 : 50|2@1+ (1,0) [0|3] ""  NF_Controller
 SG_ BATT_08_event_3_3v_error m7 : 48|2@1+ (1,0) [0|3] ""  NF_Controller
 SG_ BATT_09_PackVoltageImbalance m8 : 58|2@1+ (1,0) [0|3] ""  NF_Controller
 SG_ BATT_09_PrechargeOvercurrentPri m8 : 56|2@1+ (1,0) [0|3] ""  NF_Controller
 SG_ BATT_09_HVILvoltageError m8 : 2|2@1+ (1,0) [0|3] ""  NF_Controller
 SG_ BATT_09_HVILcurrentReturnError m8 : 0|2@1+ (1,0) [0|3] ""  NF_Controller
 SG_ BATT_09_PosDcContWeldedSec m8 : 14|2@1+ (1,0) [0|3] ""  NF_Controller
 SG_ BATT_09_NegDcContWeldedSec m8 : 10|2@1+ (1,0) [0|3] ""  NF_Controller
 SG_ BATT_09_NegDcContStuckOpenSec m8 : 8|2@1+ (1,0) [0|3] ""  NF_Controller
 SG_ BATT_09_PosDcContStuckOpenSec m8 : 12|2@1+ (1,0) [0|3] ""  NF_Controller
 SG_ BATT_09_IsolationIntFault m8 : 20|2@1+ (1,0) [0|3] ""  NF_Controller
 SG_ BATT_09_IsolationExtFault m8 : 18|2@1+ (1,0) [0|3] ""  NF_Controller
 SG_ BATT_09_event_12v_filter_error m8 : 16|2@1+ (1,0) [0|3] ""  NF_Controller
 SG_ BATT_09_event_hall_eff_hi_rang_e m8 : 30|2@1+ (1,0) [0|3] ""  NF_Controller
 SG_ BATT_09_event_brick_volt_sns_ope m8 : 28|2@1+ (1,0) [0|3] ""  NF_Controller
 SG_ BATT_09_event_5v_error m8 : 26|2@1+ (1,0) [0|3] ""  NF_Controller
 SG_ BATT_09_event_3_3_hot_error m8 : 24|2@1+ (1,0) [0|3] ""  NF_Controller
 SG_ BATT_09_event_12v_input_error m8 : 38|2@1+ (1,0) [0|3] ""  NF_Controller
 SG_ BATT_09_event_1_25v_error m8 : 36|2@1+ (1,0) [0|3] ""  NF_Controller
 SG_ BATT_09_event_shunt_MIA m8 : 34|2@1+ (1,0) [0|3] ""  NF_Controller
 SG_ BATT_09_event_SBC_int_reg_error m8 : 32|2@1+ (1,0) [0|3] ""  NF_Controller
 SG_ BATT_09_event_pos_3_3v_analog_er m8 : 46|2@1+ (1,0) [0|3] ""  NF_Controller
 SG_ BATT_09_event_outlt_clnt_thrm_op m8 : 44|2@1+ (1,0) [0|3] ""  NF_Controller
 SG_ BATT_09_event_neg_3_3_analog_err m8 : 42|2@1+ (1,0) [0|3] ""  NF_Controller
 SG_ BATT_09_event_inlet_clnt_thrm_op m8 : 40|2@1+ (1,0) [0|3] ""  NF_Controller
 SG_ BATT_09_event_hall_eff_lo_rang_e m8 : 54|2@1+ (1,0) [0|3] ""  NF_Controller
 SG_ BATT_09_event_outlt_clnt_thrm_sh m8 : 52|2@1+ (1,0) [0|3] ""  NF_Controller
 SG_ BATT_09_event_inlet_clnt_thrm_sh m8 : 50|2@1+ (1,0) [0|3] ""  NF_Controller
 SG_ BATT_09_event_3_3v_error m8 : 48|2@1+ (1,0) [0|3] ""  NF_Controller
 SG_ BATT_10_PackVoltageImbalance m9 : 58|2@1+ (1,0) [0|3] ""  NF_Controller
 SG_ BATT_10_PrechargeOvercurrentPri m9 : 56|2@1+ (1,0) [0|3] ""  NF_Controller
 SG_ BATT_10_HVILvoltageError m9 : 2|2@1+ (1,0) [0|3] ""  NF_Controller
 SG_ BATT_10_HVILcurrentReturnError m9 : 0|2@1+ (1,0) [0|3] ""  NF_Controller
 SG_ BATT_10_PosDcContWeldedSec m9 : 14|2@1+ (1,0) [0|3] ""  NF_Controller
 SG_ BATT_10_PosDcContStuckOpenSec m9 : 12|2@1+ (1,0) [0|3] ""  NF_Controller
 SG_ BATT_10_NegDcContWeldedSec m9 : 10|2@1+ (1,0) [0|3] ""  NF_Controller
 SG_ BATT_10_NegDcContStuckOpenSec m9 : 8|2@1+ (1,0) [0|3] ""  NF_Controller
 SG_ BATT_10_IsolationIntFault m9 : 20|2@1+ (1,0) [0|3] ""  NF_Controller
 SG_ BATT_10_IsolationExtFault m9 : 18|2@1+ (1,0) [0|3] ""  NF_Controller
 SG_ BATT_10_event_12v_filter_error m9 : 16|2@1+ (1,0) [0|3] ""  NF_Controller
 SG_ BATT_10_event_hall_eff_hi_rang_e m9 : 30|2@1+ (1,0) [0|3] ""  NF_Controller
 SG_ BATT_10_event_brick_volt_sns_ope m9 : 28|2@1+ (1,0) [0|3] ""  NF_Controller
 SG_ BATT_10_event_5v_error m9 : 26|2@1+ (1,0) [0|3] ""  NF_Controller
 SG_ BATT_10_event_3_3_hot_error m9 : 24|2@1+ (1,0) [0|3] ""  NF_Controller
 SG_ BATT_10_event_12v_input_error m9 : 38|2@1+ (1,0) [0|3] ""  NF_Controller
 SG_ BATT_10_event_1_25v_error m9 : 36|2@1+ (1,0) [0|3] ""  NF_Controller
 SG_ BATT_10_event_shunt_MIA m9 : 34|2@1+ (1,0) [0|3] ""  NF_Controller
 SG_ BATT_10_event_SBC_int_reg_error m9 : 32|2@1+ (1,0) [0|3] ""  NF_Controller
 SG_ BATT_10_event_pos_3_3v_analog_er m9 : 46|2@1+ (1,0) [0|3] ""  NF_Controller
 SG_ BATT_10_event_outlt_clnt_thrm_op m9 : 44|2@1+ (1,0) [0|3] ""  NF_Controller
 SG_ BATT_10_event_neg_3_3_analog_err m9 : 42|2@1+ (1,0) [0|3] ""  NF_Controller
 SG_ BATT_10_event_inlet_clnt_thrm_op m9 : 40|2@1+ (1,0) [0|3] ""  NF_Controller
 SG_ BATT_10_event_hall_eff_lo_rang_e m9 : 54|2@1+ (1,0) [0|3] ""  NF_Controller
 SG_ BATT_10_event_outlt_clnt_thrm_sh m9 : 52|2@1+ (1,0) [0|3] ""  NF_Controller
 SG_ BATT_10_event_inlet_clnt_thrm_sh m9 : 50|2@1+ (1,0) [0|3] ""  NF_Controller
 SG_ BATT_10_event_3_3v_error m9 : 48|2@1+ (1,0) [0|3] ""  NF_Controller
 SG_ BATT_11_PackVoltageImbalance m10 : 58|2@1+ (1,0) [0|3] ""  NF_Controller
 SG_ BATT_11_PrechargeOvercurrentPri m10 : 56|2@1+ (1,0) [0|3] ""  NF_Controller
 SG_ BATT_11_HVILvoltageError m10 : 2|2@1+ (1,0) [0|3] ""  NF_Controller
 SG_ BATT_11_HVILcurrentReturnError m10 : 0|2@1+ (1,0) [0|3] ""  NF_Controller
 SG_ BATT_11_PosDcContWeldedSec m10 : 14|2@1+ (1,0) [0|3] ""  NF_Controller
 SG_ BATT_11_PosDcContStuckOpenSec m10 : 12|2@1+ (1,0) [0|3] ""  NF_Controller
 SG_ BATT_11_NegDcContWeldedSec m10 : 10|2@1+ (1,0) [0|3] ""  NF_Controller
 SG_ BATT_11_NegDcContStuckOpenSec m10 : 8|2@1+ (1,0) [0|3] ""  NF_Controller
 SG_ BATT_11_IsolationIntFault m10 : 20|2@1+ (1,0) [0|3] ""  NF_Controller
 SG_ BATT_11_IsolationExtFault m10 : 18|2@1+ (1,0) [0|3] ""  NF_Controller
 SG_ BATT_11_event_12v_filter_error m10 : 16|2@1+ (1,0) [0|3] ""  NF_Controller
 SG_ BATT_11_event_hall_eff_hi_rang_e m10 : 30|2@1+ (1,0) [0|3] ""  NF_Controller
 SG_ BATT_11_event_brick_volt_sns_ope m10 : 28|2@1+ (1,0) [0|3] ""  NF_Controller
 SG_ BATT_11_event_5v_error m10 : 26|2@1+ (1,0) [0|3] ""  NF_Controller
 SG_ BATT_11_event_3_3_hot_error m10 : 24|2@1+ (1,0) [0|3] ""  NF_Controller
 SG_ BATT_11_event_12v_input_error m10 : 38|2@1+ (1,0) [0|3] ""  NF_Controller
 SG_ BATT_11_event_1_25v_error m10 : 36|2@1+ (1,0) [0|3] ""  NF_Controller
 SG_ BATT_11_event_shunt_MIA m10 : 34|2@1+ (1,0) [0|3] ""  NF_Controller
 SG_ BATT_11_event_SBC_int_reg_error m10 : 32|2@1+ (1,0) [0|3] ""  NF_Controller
 SG_ BATT_11_event_pos_3_3v_analog_er m10 : 46|2@1+ (1,0) [0|3] ""  NF_Controller
 SG_ BATT_11_event_outlt_clnt_thrm_op m10 : 44|2@1+ (1,0) [0|3] ""  NF_Controller
 SG_ BATT_11_event_neg_3_3_analog_err m10 : 42|2@1+ (1,0) [0|3] ""  NF_Controller
 SG_ BATT_11_event_inlet_clnt_thrm_op m10 : 40|2@1+ (1,0) [0|3] ""  NF_Controller
 SG_ BATT_11_event_hall_eff_lo_rang_e m10 : 54|2@1+ (1,0) [0|3] ""  NF_Controller
 SG_ BATT_11_event_outlt_clnt_thrm_sh m10 : 52|2@1+ (1,0) [0|3] ""  NF_Controller
 SG_ BATT_11_event_inlet_clnt_thrm_sh m10 : 50|2@1+ (1,0) [0|3] ""  NF_Controller
 SG_ BATT_11_event_3_3v_error m10 : 48|2@1+ (1,0) [0|3] ""  NF_Controller
 SG_ BATT_12_PackVoltageImbalance m11 : 58|2@1+ (1,0) [0|3] ""  NF_Controller
 SG_ BATT_12_PrechargeOvercurrentPri m11 : 56|2@1+ (1,0) [0|3] ""  NF_Controller
 SG_ BATT_12_HVILvoltageError m11 : 2|2@1+ (1,0) [0|3] ""  NF_Controller
 SG_ BATT_12_HVILcurrentReturnError m11 : 0|2@1+ (1,0) [0|3] ""  NF_Controller
 SG_ BATT_12_PosDcContWeldedSec m11 : 14|2@1+ (1,0) [0|3] ""  NF_Controller
 SG_ BATT_12_PosDcContStuckOpenSec m11 : 12|2@1+ (1,0) [0|3] ""  NF_Controller
 SG_ BATT_12_NegDcContWeldedSec m11 : 10|2@1+ (1,0) [0|3] ""  NF_Controller
 SG_ BATT_12_NegDcContStuckOpenSec m11 : 8|2@1+ (1,0) [0|3] ""  NF_Controller
 SG_ BATT_12_IsolationIntFault m11 : 20|2@1+ (1,0) [0|3] ""  NF_Controller
 SG_ BATT_12_IsolationExtFault m11 : 18|2@1+ (1,0) [0|3] ""  NF_Controller
 SG_ BATT_12_event_12v_filter_error m11 : 16|2@1+ (1,0) [0|3] ""  NF_Controller
 SG_ BATT_12_event_hall_eff_hi_rang_e m11 : 30|2@1+ (1,0) [0|3] ""  NF_Controller
 SG_ BATT_12_event_brick_volt_sns_ope m11 : 28|2@1+ (1,0) [0|3] ""  NF_Controller
 SG_ BATT_12_event_5v_error m11 : 26|2@1+ (1,0) [0|3] ""  NF_Controller
 SG_ BATT_12_event_3_3_hot_error m11 : 24|2@1+ (1,0) [0|3] ""  NF_Controller
 SG_ BATT_12_event_12v_input_error m11 : 38|2@1+ (1,0) [0|3] ""  NF_Controller
 SG_ BATT_12_event_1_25v_error m11 : 36|2@1+ (1,0) [0|3] ""  NF_Controller
 SG_ BATT_12_event_shunt_MIA m11 : 34|2@1+ (1,0) [0|3] ""  NF_Controller
 SG_ BATT_12_event_SBC_int_reg_error m11 : 32|2@1+ (1,0) [0|3] ""  NF_Controller
 SG_ BATT_12_event_pos_3_3v_analog_er m11 : 46|2@1+ (1,0) [0|3] ""  NF_Controller
 SG_ BATT_12_event_outlt_clnt_thrm_op m11 : 44|2@1+ (1,0) [0|3] ""  NF_Controller
 SG_ BATT_12_event_neg_3_3_analog_err m11 : 42|2@1+ (1,0) [0|3] ""  NF_Controller
 SG_ BATT_12_event_inlet_clnt_thrm_op m11 : 40|2@1+ (1,0) [0|3] ""  NF_Controller
 SG_ BATT_12_event_hall_eff_lo_rang_e m11 : 54|2@1+ (1,0) [0|3] ""  NF_Controller
 SG_ BATT_12_event_outlt_clnt_thrm_sh m11 : 52|2@1+ (1,0) [0|3] ""  NF_Controller
 SG_ BATT_12_event_inlet_clnt_thrm_sh m11 : 50|2@1+ (1,0) [0|3] ""  NF_Controller
 SG_ BATT_12_event_3_3v_error m11 : 48|2@1+ (1,0) [0|3] ""  NF_Controller
 SG_ BATT_13_PackVoltageImbalance m12 : 58|2@1+ (1,0) [0|3] ""  NF_Controller
 SG_ BATT_13_PrechargeOvercurrentPri m12 : 56|2@1+ (1,0) [0|3] ""  NF_Controller
 SG_ BATT_13_HVILvoltageError m12 : 2|2@1+ (1,0) [0|3] ""  NF_Controller
 SG_ BATT_13_HVILcurrentReturnError m12 : 0|2@1+ (1,0) [0|3] ""  NF_Controller
 SG_ BATT_13_PosDcContWeldedSec m12 : 14|2@1+ (1,0) [0|3] ""  NF_Controller
 SG_ BATT_13_PosDcContStuckOpenSec m12 : 12|2@1+ (1,0) [0|3] ""  NF_Controller
 SG_ BATT_13_NegDcContWeldedSec m12 : 10|2@1+ (1,0) [0|3] ""  NF_Controller
 SG_ BATT_13_NegDcContStuckOpenSec m12 : 8|2@1+ (1,0) [0|3] ""  NF_Controller
 SG_ BATT_13_IsolationIntFault m12 : 20|2@1+ (1,0) [0|3] ""  NF_Controller
 SG_ BATT_13_IsolationExtFault m12 : 18|2@1+ (1,0) [0|3] ""  NF_Controller
 SG_ BATT_13_event_12v_filter_error m12 : 16|2@1+ (1,0) [0|3] ""  NF_Controller
 SG_ BATT_13_event_hall_eff_hi_rang_e m12 : 30|2@1+ (1,0) [0|3] ""  NF_Controller
 SG_ BATT_13_event_brick_volt_sns_ope m12 : 28|2@1+ (1,0) [0|3] ""  NF_Controller
 SG_ BATT_13_event_5v_error m12 : 26|2@1+ (1,0) [0|3] ""  NF_Controller
 SG_ BATT_13_event_3_3_hot_error m12 : 24|2@1+ (1,0) [0|3] ""  NF_Controller
 SG_ BATT_13_event_12v_input_error m12 : 38|2@1+ (1,0) [0|3] ""  NF_Controller
 SG_ BATT_13_event_1_25v_error m12 : 36|2@1+ (1,0) [0|3] ""  NF_Controller
 SG_ BATT_13_event_shunt_MIA m12 : 34|2@1+ (1,0) [0|3] ""  NF_Controller
 SG_ BATT_13_event_SBC_int_reg_error m12 : 32|2@1+ (1,0) [0|3] ""  NF_Controller
 SG_ BATT_13_event_pos_3_3v_analog_er m12 : 46|2@1+ (1,0) [0|3] ""  NF_Controller
 SG_ BATT_13_event_outlt_clnt_thrm_op m12 : 44|2@1+ (1,0) [0|3] ""  NF_Controller
 SG_ BATT_13_event_neg_3_3_analog_err m12 : 42|2@1+ (1,0) [0|3] ""  NF_Controller
 SG_ BATT_13_event_inlet_clnt_thrm_op m12 : 40|2@1+ (1,0) [0|3] ""  NF_Controller
 SG_ BATT_13_event_hall_eff_lo_rang_e m12 : 54|2@1+ (1,0) [0|3] ""  NF_Controller
 SG_ BATT_13_event_outlt_clnt_thrm_sh m12 : 52|2@1+ (1,0) [0|3] ""  NF_Controller
 SG_ BATT_13_event_inlet_clnt_thrm_sh m12 : 50|2@1+ (1,0) [0|3] ""  NF_Controller
 SG_ BATT_13_event_3_3v_error m12 : 48|2@1+ (1,0) [0|3] ""  NF_Controller
 SG_ BATT_14_PackVoltageImbalance m13 : 58|2@1+ (1,0) [0|3] ""  NF_Controller
 SG_ BATT_14_PrechargeOvercurrentPri m13 : 56|2@1+ (1,0) [0|3] ""  NF_Controller
 SG_ BATT_14_HVILvoltageError m13 : 2|2@1+ (1,0) [0|3] ""  NF_Controller
 SG_ BATT_14_HVILcurrentReturnError m13 : 0|2@1+ (1,0) [0|3] ""  NF_Controller
 SG_ BATT_14_PosDcContWeldedSec m13 : 14|2@1+ (1,0) [0|3] ""  NF_Controller
 SG_ BATT_14_PosDcContStuckOpenSec m13 : 12|2@1+ (1,0) [0|3] ""  NF_Controller
 SG_ BATT_14_NegDcContWeldedSec m13 : 10|2@1+ (1,0) [0|3] ""  NF_Controller
 SG_ BATT_14_NegDcContStuckOpenSec m13 : 8|2@1+ (1,0) [0|3] ""  NF_Controller
 SG_ BATT_14_IsolationIntFault m13 : 20|2@1+ (1,0) [0|3] ""  NF_Controller
 SG_ BATT_14_IsolationExtFault m13 : 18|2@1+ (1,0) [0|3] ""  NF_Controller
 SG_ BATT_14_event_12v_filter_error m13 : 16|2@1+ (1,0) [0|3] ""  NF_Controller
 SG_ BATT_14_event_hall_eff_hi_rang_e m13 : 30|2@1+ (1,0) [0|3] ""  NF_Controller
 SG_ BATT_14_event_brick_volt_sns_ope m13 : 28|2@1+ (1,0) [0|3] ""  NF_Controller
 SG_ BATT_14_event_5v_error m13 : 26|2@1+ (1,0) [0|3] ""  NF_Controller
 SG_ BATT_14_event_3_3_hot_error m13 : 24|2@1+ (1,0) [0|3] ""  NF_Controller
 SG_ BATT_14_event_12v_input_error m13 : 38|2@1+ (1,0) [0|3] ""  NF_Controller
 SG_ BATT_14_event_1_25v_error m13 : 36|2@1+ (1,0) [0|3] ""  NF_Controller
 SG_ BATT_14_event_shunt_MIA m13 : 34|2@1+ (1,0) [0|3] ""  NF_Controller
 SG_ BATT_14_event_SBC_int_reg_error m13 : 32|2@1+ (1,0) [0|3] ""  NF_Controller
 SG_ BATT_14_event_pos_3_3v_analog_er m13 : 46|2@1+ (1,0) [0|3] ""  NF_Controller
 SG_ BATT_14_event_outlt_clnt_thrm_op m13 : 44|2@1+ (1,0) [0|3] ""  NF_Controller
 SG_ BATT_14_event_neg_3_3_analog_err m13 : 42|2@1+ (1,0) [0|3] ""  NF_Controller
 SG_ BATT_14_event_inlet_clnt_thrm_op m13 : 40|2@1+ (1,0) [0|3] ""  NF_Controller
 SG_ BATT_14_event_hall_eff_lo_rang_e m13 : 54|2@1+ (1,0) [0|3] ""  NF_Controller
 SG_ BATT_14_event_outlt_clnt_thrm_sh m13 : 52|2@1+ (1,0) [0|3] ""  NF_Controller
 SG_ BATT_14_event_inlet_clnt_thrm_sh m13 : 50|2@1+ (1,0) [0|3] ""  NF_Controller
 SG_ BATT_14_event_3_3v_error m13 : 48|2@1+ (1,0) [0|3] ""  NF_Controller
 SG_ BATT_15_PackVoltageImbalance m14 : 58|2@1+ (1,0) [0|3] ""  NF_Controller
 SG_ BATT_15_PrechargeOvercurrentPri m14 : 56|2@1+ (1,0) [0|3] ""  NF_Controller
 SG_ BATT_15_HVILvoltageError m14 : 2|2@1+ (1,0) [0|3] ""  NF_Controller
 SG_ BATT_15_HVILcurrentReturnError m14 : 0|2@1+ (1,0) [0|3] ""  NF_Controller
 SG_ BATT_15_PosDcContWeldedSec m14 : 14|2@1+ (1,0) [0|3] ""  NF_Controller
 SG_ BATT_15_PosDcContStuckOpenSec m14 : 12|2@1+ (1,0) [0|3] ""  NF_Controller
 SG_ BATT_15_NegDcContWeldedSec m14 : 10|2@1+ (1,0) [0|3] ""  NF_Controller
 SG_ BATT_15_NegDcContStuckOpenSec m14 : 8|2@1+ (1,0) [0|3] ""  NF_Controller
 SG_ BATT_15_IsolationIntFault m14 : 20|2@1+ (1,0) [0|3] ""  NF_Controller
 SG_ BATT_15_IsolationExtFault m14 : 18|2@1+ (1,0) [0|3] ""  NF_Controller
 SG_ BATT_15_event_12v_filter_error m14 : 16|2@1+ (1,0) [0|3] ""  NF_Controller
 SG_ BATT_15_event_hall_eff_hi_rang_e m14 : 30|2@1+ (1,0) [0|3] ""  NF_Controller
 SG_ BATT_15_event_brick_volt_sns_ope m14 : 28|2@1+ (1,0) [0|3] ""  NF_Controller
 SG_ BATT_15_event_5v_error m14 : 26|2@1+ (1,0) [0|3] ""  NF_Controller
 SG_ BATT_15_event_3_3_hot_error m14 : 24|2@1+ (1,0) [0|3] ""  NF_Controller
 SG_ BATT_15_event_12v_input_error m14 : 38|2@1+ (1,0) [0|3] ""  NF_Controller
 SG_ BATT_15_event_1_25v_error m14 : 36|2@1+ (1,0) [0|3] ""  NF_Controller
 SG_ BATT_15_event_shunt_MIA m14 : 34|2@1+ (1,0) [0|3] ""  NF_Controller
 SG_ BATT_15_event_SBC_int_reg_error m14 : 32|2@1+ (1,0) [0|3] ""  NF_Controller
 SG_ BATT_15_event_pos_3_3v_analog_er m14 : 46|2@1+ (1,0) [0|3] ""  NF_Controller
 SG_ BATT_15_event_outlt_clnt_thrm_op m14 : 44|2@1+ (1,0) [0|3] ""  NF_Controller
 SG_ BATT_15_event_neg_3_3_analog_err m14 : 42|2@1+ (1,0) [0|3] ""  NF_Controller
 SG_ BATT_15_event_inlet_clnt_thrm_op m14 : 40|2@1+ (1,0) [0|3] ""  NF_Controller
 SG_ BATT_15_event_hall_eff_lo_rang_e m14 : 54|2@1+ (1,0) [0|3] ""  NF_Controller
 SG_ BATT_15_event_outlt_clnt_thrm_sh m14 : 52|2@1+ (1,0) [0|3] ""  NF_Controller
 SG_ BATT_15_event_inlet_clnt_thrm_sh m14 : 50|2@1+ (1,0) [0|3] ""  NF_Controller
 SG_ BATT_15_event_3_3v_error m14 : 48|2@1+ (1,0) [0|3] ""  NF_Controller
 SG_ multiplexor_batt_diag_C M : 4|4@1+ (1,0) [0|15] ""  NF_Controller

CM_ "V_1.0";
CM_ BO_ 2499759204 "Back up speaker handshake signal from pack 1 to pack 2";
CM_ SG_ 2499759204 BATT_speakerClaimFlag_1 "Default speaker pack will set this bit to 1.
Default speaker pack shall set this signal to 0 in case of BATT_expectedSpeakerID_2 becomes 2.";
CM_ SG_ 2499759204 BATT_expectedSpeakerID_1 "Default Speaker pack shall set this signal to 1.
Default pack shall set this signal to 2 in case of BATT_expectedSpeakerID_2 becomes 2.
";
CM_ SG_ 2499759460 BATT_speakerClaimFlag_2 "Backup speaker pack shall set this signal to 0.
Backup speaker pack shall set this signal to 1 if BATT_speakerClaimFlag_1 set to 0.
";
CM_ SG_ 2499759460 BATT_expectedSpeakerID_2 "Backup speaker pack shall set this signal to 1.
Backup speaker shall set this signal to 2 in case of default speaker disconnect detected.
";
CM_ BO_ 2499756361 "pack ID arbitration trigger command from the VCU";
BA_DEF_ BO_  "GenMsgDiag" ENUM  "No","Yes";
BA_DEF_  "NetworkSpeed" ENUM  "250kBit/s","500kBit/s","1000kBit/s";
BA_DEF_ SG_  "SigType" ENUM  "Default","Range","RangeSigned","ASCII","Discrete","Control","ReferencePGN","DTC","StringDelimiter","StringLength","StringLengthControl","MessageCounter","MessageChecksum";
BA_DEF_ SG_  "GenSigEVName" STRING ;
BA_DEF_ SG_  "GenSigILSupport" ENUM  "No","Yes";
BA_DEF_ SG_  "GenSigSendType" ENUM  "Cyclic","OnWrite","OnWriteWithRepetition","OnChange","OnChangeWithRepetition","IfActive","IfActiveWithRepetition","NoSigSendType";
BA_DEF_ BO_  "GenMsgFastOnStart" INT 0 100000;
BA_DEF_ SG_  "GenSigStartValue" INT 0 10000;
BA_DEF_ BO_  "GenMsgILSupport" ENUM  "No","Yes";
BA_DEF_ BU_  "NmStationAddress" INT 0 255;
BA_DEF_ BO_  "GenMsgSendType" ENUM  "cyclic","NotUsed","IfActive","NotUsed","NotUsed","NotUsed","NotUsed","NotUsed","noMsgSendType";
BA_DEF_ BO_  "GenMsgRequestable" INT 0 1;
BA_DEF_ BO_  "GenMsgCycleTime" INT 0 3600000;
BA_DEF_ SG_  "SPN" INT 0 524287;
BA_DEF_  "DBName" STRING ;
BA_DEF_  "BusType" STRING ;
BA_DEF_  "ProtocolType" STRING ;
BA_DEF_ BO_  "VFrameFormat" ENUM  "StandardCAN","ExtendedCAN","reserved","J1939PG";
BA_DEF_ SG_  "SystemSignalLongSymbol" STRING ;
BA_DEF_DEF_  "GenMsgDiag" "No";
BA_DEF_DEF_  "NetworkSpeed" "250kBit/s";
BA_DEF_DEF_  "SigType" "Default";
BA_DEF_DEF_  "GenSigEVName" "Env@Nodename_@Signame";
BA_DEF_DEF_  "GenSigILSupport" "Yes";
BA_DEF_DEF_  "GenSigSendType" "NoSigSendType";
BA_DEF_DEF_  "GenMsgFastOnStart" 0;
BA_DEF_DEF_  "GenSigStartValue" 0;
BA_DEF_DEF_  "GenMsgILSupport" "Yes";
BA_DEF_DEF_  "NmStationAddress" 254;
BA_DEF_DEF_  "GenMsgSendType" "noMsgSendType";
BA_DEF_DEF_  "GenMsgRequestable" 1;
BA_DEF_DEF_  "GenMsgCycleTime" 0;
BA_DEF_DEF_  "SPN" 0;
BA_DEF_DEF_  "DBName" "";
BA_DEF_DEF_  "BusType" "CAN";
BA_DEF_DEF_  "ProtocolType" "J1939";
BA_DEF_DEF_  "VFrameFormat" "J1939PG";
BA_DEF_DEF_  "SystemSignalLongSymbol" "";
BA_ "ProtocolType" "CAN";
BA_ "DBName" "NF_BMS_Application";
BA_ "NmStationAddress" BU_ BMS_Controller 100;
BA_ "NmStationAddress" BU_ NF_Controller 73;
BA_ "VFrameFormat" BO_ 2499756361 1;
BA_ "VFrameFormat" BO_ 2499758692 1;
BA_ "GenMsgSendType" BO_ 2499763812 0;
BA_ "VFrameFormat" BO_ 2499763812 1;
BA_ "VFrameFormat" BO_ 2499763556 1;
BA_ "GenMsgSendType" BO_ 2499763556 0;
BA_ "GenMsgCycleTime" BO_ 2499763556 100;
BA_ "GenMsgSendType" BO_ 2499763300 0;
BA_ "VFrameFormat" BO_ 2499763300 1;
BA_ "GenMsgSendType" BO_ 2499763044 0;
BA_ "VFrameFormat" BO_ 2499763044 1;
BA_ "GenSigStartValue" SG_ 2499763044 BATT_01_HVILvoltageError 2;
BA_ "GenSigStartValue" SG_ 2499763044 BATT_01_HVILcurrentReturnError 2;
BA_ "GenSigStartValue" SG_ 2499763044 BATT_01_PosDcContWeldedSec 2;
BA_ "GenSigStartValue" SG_ 2499763044 BATT_01_PosDcContStuckOpenSec 2;
BA_ "GenSigStartValue" SG_ 2499763044 BATT_01_NegDcContWeldedSec 2;
BA_ "GenSigStartValue" SG_ 2499763044 BATT_01_NegDcContStuckOpenSec 2;
BA_ "GenSigStartValue" SG_ 2499763044 BATT_01_IsolationIntFault 2;
BA_ "GenSigStartValue" SG_ 2499763044 BATT_01_IsolationExtFault 2;
BA_ "GenSigStartValue" SG_ 2499763044 BATT_01_event_12v_filter_error 2;
BA_ "GenSigStartValue" SG_ 2499763044 BATT_01_event_hall_eff_hi_rang_e 2;
BA_ "SystemSignalLongSymbol" SG_ 2499763044 BATT_01_event_hall_eff_hi_rang_e "BATT_01_event_hall_eff_hi_rang_err";
BA_ "GenSigStartValue" SG_ 2499763044 BATT_01_event_brick_volt_sns_ope 2;
BA_ "SystemSignalLongSymbol" SG_ 2499763044 BATT_01_event_brick_volt_sns_ope "BATT_01_event_brick_volt_sns_open";
BA_ "GenSigStartValue" SG_ 2499763044 BATT_01_event_5v_error 2;
BA_ "GenSigStartValue" SG_ 2499763044 BATT_01_event_3_3_hot_error 2;
BA_ "GenSigStartValue" SG_ 2499763044 BATT_01_event_12v_input_error 2;
BA_ "GenSigStartValue" SG_ 2499763044 BATT_01_event_1_25v_error 2;
BA_ "GenSigStartValue" SG_ 2499763044 BATT_01_event_shunt_MIA 2;
BA_ "GenSigStartValue" SG_ 2499763044 BATT_01_event_SBC_int_reg_error 2;
BA_ "GenSigStartValue" SG_ 2499763044 BATT_01_event_pos_3_3v_analog_er 2;
BA_ "SystemSignalLongSymbol" SG_ 2499763044 BATT_01_event_pos_3_3v_analog_er "BATT_01_event_pos_3_3v_analog_error";
BA_ "GenSigStartValue" SG_ 2499763044 BATT_01_event_outlt_clnt_thrm_op 2;
BA_ "SystemSignalLongSymbol" SG_ 2499763044 BATT_01_event_outlt_clnt_thrm_op "BATT_01_event_outlt_clnt_thrm_open";
BA_ "GenSigStartValue" SG_ 2499763044 BATT_01_event_neg_3_3_analog_err 2;
BA_ "SystemSignalLongSymbol" SG_ 2499763044 BATT_01_event_neg_3_3_analog_err "BATT_01_event_neg_3_3_analog_error";
BA_ "GenSigStartValue" SG_ 2499763044 BATT_01_event_inlet_clnt_thrm_op 2;
BA_ "SystemSignalLongSymbol" SG_ 2499763044 BATT_01_event_inlet_clnt_thrm_op "BATT_01_event_inlet_clnt_thrm_open";
BA_ "GenSigStartValue" SG_ 2499763044 BATT_01_event_hall_eff_lo_rang_e 2;
BA_ "SystemSignalLongSymbol" SG_ 2499763044 BATT_01_event_hall_eff_lo_rang_e "BATT_01_event_hall_eff_lo_rang_err";
BA_ "GenSigStartValue" SG_ 2499763044 BATT_01_event_outlt_clnt_thrm_sh 2;
BA_ "SystemSignalLongSymbol" SG_ 2499763044 BATT_01_event_outlt_clnt_thrm_sh "BATT_01_event_outlt_clnt_thrm_short";
BA_ "GenSigStartValue" SG_ 2499763044 BATT_01_event_inlet_clnt_thrm_sh 2;
BA_ "SystemSignalLongSymbol" SG_ 2499763044 BATT_01_event_inlet_clnt_thrm_sh "BATT_01_event_inlet_clnt_thrm_short";
BA_ "GenSigStartValue" SG_ 2499763044 BATT_01_event_3_3v_error 2;
BA_ "GenSigStartValue" SG_ 2499763044 BATT_02_HVILvoltageError 2;
BA_ "GenSigStartValue" SG_ 2499763044 BATT_02_HVILcurrentReturnError 2;
BA_ "GenSigStartValue" SG_ 2499763044 BATT_02_PosDcContWeldedSec 2;
BA_ "GenSigStartValue" SG_ 2499763044 BATT_02_PosDcContStuckOpenSec 2;
BA_ "GenSigStartValue" SG_ 2499763044 BATT_02_NegDcContWeldedSec 2;
BA_ "GenSigStartValue" SG_ 2499763044 BATT_02_NegDcContStuckOpenSec 2;
BA_ "GenSigStartValue" SG_ 2499763044 BATT_02_IsolationIntFault 2;
BA_ "GenSigStartValue" SG_ 2499763044 BATT_02_IsolationExtFault 2;
BA_ "GenSigStartValue" SG_ 2499763044 BATT_02_event_12v_filter_error 2;
BA_ "GenSigStartValue" SG_ 2499763044 BATT_02_event_hall_eff_hi_rang_e 2;
BA_ "SystemSignalLongSymbol" SG_ 2499763044 BATT_02_event_hall_eff_hi_rang_e "BATT_02_event_hall_eff_hi_rang_err";
BA_ "GenSigStartValue" SG_ 2499763044 BATT_02_event_brick_volt_sns_ope 2;
BA_ "SystemSignalLongSymbol" SG_ 2499763044 BATT_02_event_brick_volt_sns_ope "BATT_02_event_brick_volt_sns_open";
BA_ "GenSigStartValue" SG_ 2499763044 BATT_02_event_5v_error 2;
BA_ "GenSigStartValue" SG_ 2499763044 BATT_02_event_3_3_hot_error 2;
BA_ "GenSigStartValue" SG_ 2499763044 BATT_02_event_12v_input_error 2;
BA_ "GenSigStartValue" SG_ 2499763044 BATT_02_event_1_25v_error 2;
BA_ "GenSigStartValue" SG_ 2499763044 BATT_02_event_shunt_MIA 2;
BA_ "GenSigStartValue" SG_ 2499763044 BATT_02_event_SBC_int_reg_error 2;
BA_ "GenSigStartValue" SG_ 2499763044 BATT_02_event_pos_3_3v_analog_er 2;
BA_ "SystemSignalLongSymbol" SG_ 2499763044 BATT_02_event_pos_3_3v_analog_er "BATT_02_event_pos_3_3v_analog_error";
BA_ "GenSigStartValue" SG_ 2499763044 BATT_02_event_outlt_clnt_thrm_op 2;
BA_ "SystemSignalLongSymbol" SG_ 2499763044 BATT_02_event_outlt_clnt_thrm_op "BATT_02_event_outlt_clnt_thrm_open";
BA_ "GenSigStartValue" SG_ 2499763044 BATT_02_event_neg_3_3_analog_err 2;
BA_ "SystemSignalLongSymbol" SG_ 2499763044 BATT_02_event_neg_3_3_analog_err "BATT_02_event_neg_3_3_analog_error";
BA_ "GenSigStartValue" SG_ 2499763044 BATT_02_event_inlet_clnt_thrm_op 2;
BA_ "SystemSignalLongSymbol" SG_ 2499763044 BATT_02_event_inlet_clnt_thrm_op "BATT_02_event_inlet_clnt_thrm_open";
BA_ "GenSigStartValue" SG_ 2499763044 BATT_02_event_hall_eff_lo_rang_e 2;
BA_ "SystemSignalLongSymbol" SG_ 2499763044 BATT_02_event_hall_eff_lo_rang_e "BATT_02_event_hall_eff_lo_rang_err";
BA_ "GenSigStartValue" SG_ 2499763044 BATT_02_event_outlt_clnt_thrm_sh 2;
BA_ "SystemSignalLongSymbol" SG_ 2499763044 BATT_02_event_outlt_clnt_thrm_sh "BATT_02_event_outlt_clnt_thrm_short";
BA_ "GenSigStartValue" SG_ 2499763044 BATT_02_event_inlet_clnt_thrm_sh 2;
BA_ "SystemSignalLongSymbol" SG_ 2499763044 BATT_02_event_inlet_clnt_thrm_sh "BATT_02_event_inlet_clnt_thrm_short";
BA_ "GenSigStartValue" SG_ 2499763044 BATT_02_event_3_3v_error 2;
BA_ "GenSigStartValue" SG_ 2499763044 BATT_03_HVILvoltageError 2;
BA_ "GenSigStartValue" SG_ 2499763044 BATT_03_HVILcurrentReturnError 2;
BA_ "GenSigStartValue" SG_ 2499763044 BATT_03_PosDcContWeldedSec 2;
BA_ "GenSigStartValue" SG_ 2499763044 BATT_03_PosDcContStuckOpenSec 2;
BA_ "GenSigStartValue" SG_ 2499763044 BATT_03_NegDcContWeldedSec 2;
BA_ "GenSigStartValue" SG_ 2499763044 BATT_03_NegDcContStuckOpenSec 2;
BA_ "GenSigStartValue" SG_ 2499763044 BATT_03_IsolationIntFault 2;
BA_ "GenSigStartValue" SG_ 2499763044 BATT_03_IsolationExtFault 2;
BA_ "GenSigStartValue" SG_ 2499763044 BATT_03_event_12v_filter_error 2;
BA_ "GenSigStartValue" SG_ 2499763044 BATT_03_event_hall_eff_hi_rang_e 2;
BA_ "SystemSignalLongSymbol" SG_ 2499763044 BATT_03_event_hall_eff_hi_rang_e "BATT_03_event_hall_eff_hi_rang_err";
BA_ "GenSigStartValue" SG_ 2499763044 BATT_03_event_brick_volt_sns_ope 2;
BA_ "SystemSignalLongSymbol" SG_ 2499763044 BATT_03_event_brick_volt_sns_ope "BATT_03_event_brick_volt_sns_open";
BA_ "GenSigStartValue" SG_ 2499763044 BATT_03_event_5v_error 2;
BA_ "GenSigStartValue" SG_ 2499763044 BATT_03_event_3_3_hot_error 2;
BA_ "GenSigStartValue" SG_ 2499763044 BATT_03_event_12v_input_error 2;
BA_ "GenSigStartValue" SG_ 2499763044 BATT_03_event_1_25v_error 2;
BA_ "GenSigStartValue" SG_ 2499763044 BATT_03_event_shunt_MIA 2;
BA_ "GenSigStartValue" SG_ 2499763044 BATT_03_event_SBC_int_reg_error 2;
BA_ "GenSigStartValue" SG_ 2499763044 BATT_03_event_pos_3_3v_analog_er 2;
BA_ "SystemSignalLongSymbol" SG_ 2499763044 BATT_03_event_pos_3_3v_analog_er "BATT_03_event_pos_3_3v_analog_error";
BA_ "GenSigStartValue" SG_ 2499763044 BATT_03_event_outlt_clnt_thrm_op 2;
BA_ "SystemSignalLongSymbol" SG_ 2499763044 BATT_03_event_outlt_clnt_thrm_op "BATT_03_event_outlt_clnt_thrm_open";
BA_ "GenSigStartValue" SG_ 2499763044 BATT_03_event_neg_3_3_analog_err 2;
BA_ "SystemSignalLongSymbol" SG_ 2499763044 BATT_03_event_neg_3_3_analog_err "BATT_03_event_neg_3_3_analog_error";
BA_ "GenSigStartValue" SG_ 2499763044 BATT_03_event_inlet_clnt_thrm_op 2;
BA_ "SystemSignalLongSymbol" SG_ 2499763044 BATT_03_event_inlet_clnt_thrm_op "BATT_03_event_inlet_clnt_thrm_open";
BA_ "GenSigStartValue" SG_ 2499763044 BATT_03_event_hall_eff_lo_rang_e 2;
BA_ "SystemSignalLongSymbol" SG_ 2499763044 BATT_03_event_hall_eff_lo_rang_e "BATT_03_event_hall_eff_lo_rang_err";
BA_ "GenSigStartValue" SG_ 2499763044 BATT_03_event_outlt_clnt_thrm_sh 2;
BA_ "SystemSignalLongSymbol" SG_ 2499763044 BATT_03_event_outlt_clnt_thrm_sh "BATT_03_event_outlt_clnt_thrm_short";
BA_ "GenSigStartValue" SG_ 2499763044 BATT_03_event_inlet_clnt_thrm_sh 2;
BA_ "SystemSignalLongSymbol" SG_ 2499763044 BATT_03_event_inlet_clnt_thrm_sh "BATT_03_event_inlet_clnt_thrm_short";
BA_ "GenSigStartValue" SG_ 2499763044 BATT_03_event_3_3v_error 2;
BA_ "GenSigStartValue" SG_ 2499763044 BATT_04_HVILvoltageError 2;
BA_ "GenSigStartValue" SG_ 2499763044 BATT_04_HVILcurrentReturnError 2;
BA_ "GenSigStartValue" SG_ 2499763044 BATT_04_PosDcContWeldedSec 2;
BA_ "GenSigStartValue" SG_ 2499763044 BATT_04_PosDcContStuckOpenSec 2;
BA_ "GenSigStartValue" SG_ 2499763044 BATT_04_NegDcContWeldedSec 2;
BA_ "GenSigStartValue" SG_ 2499763044 BATT_04_NegDcContStuckOpenSec 2;
BA_ "GenSigStartValue" SG_ 2499763044 BATT_04_IsolationIntFault 2;
BA_ "GenSigStartValue" SG_ 2499763044 BATT_04_IsolationExtFault 2;
BA_ "GenSigStartValue" SG_ 2499763044 BATT_04_event_12v_filter_error 2;
BA_ "GenSigStartValue" SG_ 2499763044 BATT_04_event_hall_eff_hi_rang_e 2;
BA_ "SystemSignalLongSymbol" SG_ 2499763044 BATT_04_event_hall_eff_hi_rang_e "BATT_04_event_hall_eff_hi_rang_err";
BA_ "GenSigStartValue" SG_ 2499763044 BATT_04_event_brick_volt_sns_ope 2;
BA_ "SystemSignalLongSymbol" SG_ 2499763044 BATT_04_event_brick_volt_sns_ope "BATT_04_event_brick_volt_sns_open";
BA_ "GenSigStartValue" SG_ 2499763044 BATT_04_event_5v_error 2;
BA_ "GenSigStartValue" SG_ 2499763044 BATT_04_event_3_3_hot_error 2;
BA_ "GenSigStartValue" SG_ 2499763044 BATT_04_event_12v_input_error 2;
BA_ "GenSigStartValue" SG_ 2499763044 BATT_04_event_1_25v_error 2;
BA_ "GenSigStartValue" SG_ 2499763044 BATT_04_event_shunt_MIA 2;
BA_ "GenSigStartValue" SG_ 2499763044 BATT_04_event_SBC_int_reg_error 2;
BA_ "GenSigStartValue" SG_ 2499763044 BATT_04_event_pos_3_3v_analog_er 2;
BA_ "SystemSignalLongSymbol" SG_ 2499763044 BATT_04_event_pos_3_3v_analog_er "BATT_04_event_pos_3_3v_analog_error";
BA_ "GenSigStartValue" SG_ 2499763044 BATT_04_event_outlt_clnt_thrm_op 2;
BA_ "SystemSignalLongSymbol" SG_ 2499763044 BATT_04_event_outlt_clnt_thrm_op "BATT_04_event_outlt_clnt_thrm_open";
BA_ "GenSigStartValue" SG_ 2499763044 BATT_04_event_neg_3_3_analog_err 2;
BA_ "SystemSignalLongSymbol" SG_ 2499763044 BATT_04_event_neg_3_3_analog_err "BATT_04_event_neg_3_3_analog_error";
BA_ "GenSigStartValue" SG_ 2499763044 BATT_04_event_inlet_clnt_thrm_op 2;
BA_ "SystemSignalLongSymbol" SG_ 2499763044 BATT_04_event_inlet_clnt_thrm_op "BATT_04_event_inlet_clnt_thrm_open";
BA_ "GenSigStartValue" SG_ 2499763044 BATT_04_event_hall_eff_lo_rang_e 2;
BA_ "SystemSignalLongSymbol" SG_ 2499763044 BATT_04_event_hall_eff_lo_rang_e "BATT_04_event_hall_eff_lo_rang_err";
BA_ "GenSigStartValue" SG_ 2499763044 BATT_04_event_outlt_clnt_thrm_sh 2;
BA_ "SystemSignalLongSymbol" SG_ 2499763044 BATT_04_event_outlt_clnt_thrm_sh "BATT_04_event_outlt_clnt_thrm_short";
BA_ "GenSigStartValue" SG_ 2499763044 BATT_04_event_inlet_clnt_thrm_sh 2;
BA_ "SystemSignalLongSymbol" SG_ 2499763044 BATT_04_event_inlet_clnt_thrm_sh "BATT_04_event_inlet_clnt_thrm_short";
BA_ "GenSigStartValue" SG_ 2499763044 BATT_04_event_3_3v_error 2;
BA_ "GenSigStartValue" SG_ 2499763044 BATT_05_HVILvoltageError 2;
BA_ "GenSigStartValue" SG_ 2499763044 BATT_05_HVILcurrentReturnError 2;
BA_ "GenSigStartValue" SG_ 2499763044 BATT_05_PosDcContWeldedSec 2;
BA_ "GenSigStartValue" SG_ 2499763044 BATT_05_PosDcContStuckOpenSec 2;
BA_ "GenSigStartValue" SG_ 2499763044 BATT_05_NegDcContWeldedSec 2;
BA_ "GenSigStartValue" SG_ 2499763044 BATT_05_NegDcContStuckOpenSec 2;
BA_ "GenSigStartValue" SG_ 2499763044 BATT_05_IsolationIntFault 2;
BA_ "GenSigStartValue" SG_ 2499763044 BATT_05_IsolationExtFault 2;
BA_ "GenSigStartValue" SG_ 2499763044 BATT_05_event_12v_filter_error 2;
BA_ "GenSigStartValue" SG_ 2499763044 BATT_05_event_hall_eff_hi_rang_e 2;
BA_ "SystemSignalLongSymbol" SG_ 2499763044 BATT_05_event_hall_eff_hi_rang_e "BATT_05_event_hall_eff_hi_rang_err";
BA_ "GenSigStartValue" SG_ 2499763044 BATT_05_event_brick_volt_sns_ope 2;
BA_ "SystemSignalLongSymbol" SG_ 2499763044 BATT_05_event_brick_volt_sns_ope "BATT_05_event_brick_volt_sns_open";
BA_ "GenSigStartValue" SG_ 2499763044 BATT_05_event_5v_error 2;
BA_ "GenSigStartValue" SG_ 2499763044 BATT_05_event_3_3_hot_error 2;
BA_ "GenSigStartValue" SG_ 2499763044 BATT_05_event_12v_input_error 2;
BA_ "GenSigStartValue" SG_ 2499763044 BATT_05_event_1_25v_error 2;
BA_ "GenSigStartValue" SG_ 2499763044 BATT_05_event_shunt_MIA 2;
BA_ "GenSigStartValue" SG_ 2499763044 BATT_05_event_SBC_int_reg_error 2;
BA_ "GenSigStartValue" SG_ 2499763044 BATT_05_event_pos_3_3v_analog_er 2;
BA_ "SystemSignalLongSymbol" SG_ 2499763044 BATT_05_event_pos_3_3v_analog_er "BATT_05_event_pos_3_3v_analog_error";
BA_ "GenSigStartValue" SG_ 2499763044 BATT_05_event_outlt_clnt_thrm_op 2;
BA_ "SystemSignalLongSymbol" SG_ 2499763044 BATT_05_event_outlt_clnt_thrm_op "BATT_05_event_outlt_clnt_thrm_open";
BA_ "GenSigStartValue" SG_ 2499763044 BATT_05_event_neg_3_3_analog_err 2;
BA_ "SystemSignalLongSymbol" SG_ 2499763044 BATT_05_event_neg_3_3_analog_err "BATT_05_event_neg_3_3_analog_error";
BA_ "GenSigStartValue" SG_ 2499763044 BATT_05_event_inlet_clnt_thrm_op 2;
BA_ "SystemSignalLongSymbol" SG_ 2499763044 BATT_05_event_inlet_clnt_thrm_op "BATT_05_event_inlet_clnt_thrm_open";
BA_ "GenSigStartValue" SG_ 2499763044 BATT_05_event_hall_eff_lo_rang_e 2;
BA_ "SystemSignalLongSymbol" SG_ 2499763044 BATT_05_event_hall_eff_lo_rang_e "BATT_05_event_hall_eff_lo_rang_err";
BA_ "GenSigStartValue" SG_ 2499763044 BATT_05_event_outlt_clnt_thrm_sh 2;
BA_ "SystemSignalLongSymbol" SG_ 2499763044 BATT_05_event_outlt_clnt_thrm_sh "BATT_05_event_outlt_clnt_thrm_short";
BA_ "GenSigStartValue" SG_ 2499763044 BATT_05_event_inlet_clnt_thrm_sh 2;
BA_ "SystemSignalLongSymbol" SG_ 2499763044 BATT_05_event_inlet_clnt_thrm_sh "BATT_05_event_inlet_clnt_thrm_short";
BA_ "GenSigStartValue" SG_ 2499763044 BATT_05_event_3_3v_error 2;
BA_ "GenSigStartValue" SG_ 2499763044 BATT_06_HVILvoltageError 2;
BA_ "GenSigStartValue" SG_ 2499763044 BATT_06_HVILcurrentReturnError 2;
BA_ "GenSigStartValue" SG_ 2499763044 BATT_06_PosDcContWeldedSec 2;
BA_ "GenSigStartValue" SG_ 2499763044 BATT_06_PosDcContStuckOpenSec 2;
BA_ "GenSigStartValue" SG_ 2499763044 BATT_06_NegDcContWeldedSec 2;
BA_ "GenSigStartValue" SG_ 2499763044 BATT_06_NegDcContStuckOpenSec 2;
BA_ "GenSigStartValue" SG_ 2499763044 BATT_06_IsolationIntFault 2;
BA_ "GenSigStartValue" SG_ 2499763044 BATT_06_IsolationExtFault 2;
BA_ "GenSigStartValue" SG_ 2499763044 BATT_06_event_12v_filter_error 2;
BA_ "GenSigStartValue" SG_ 2499763044 BATT_06_event_hall_eff_hi_rang_e 2;
BA_ "SystemSignalLongSymbol" SG_ 2499763044 BATT_06_event_hall_eff_hi_rang_e "BATT_06_event_hall_eff_hi_rang_err";
BA_ "GenSigStartValue" SG_ 2499763044 BATT_06_event_brick_volt_sns_ope 2;
BA_ "SystemSignalLongSymbol" SG_ 2499763044 BATT_06_event_brick_volt_sns_ope "BATT_06_event_brick_volt_sns_open";
BA_ "GenSigStartValue" SG_ 2499763044 BATT_06_event_5v_error 2;
BA_ "GenSigStartValue" SG_ 2499763044 BATT_06_event_3_3_hot_error 2;
BA_ "GenSigStartValue" SG_ 2499763044 BATT_06_event_12v_input_error 2;
BA_ "GenSigStartValue" SG_ 2499763044 BATT_06_event_1_25v_error 2;
BA_ "GenSigStartValue" SG_ 2499763044 BATT_06_event_shunt_MIA 2;
BA_ "GenSigStartValue" SG_ 2499763044 BATT_06_event_SBC_int_reg_error 2;
BA_ "GenSigStartValue" SG_ 2499763044 BATT_06_event_pos_3_3v_analog_er 2;
BA_ "SystemSignalLongSymbol" SG_ 2499763044 BATT_06_event_pos_3_3v_analog_er "BATT_06_event_pos_3_3v_analog_error";
BA_ "GenSigStartValue" SG_ 2499763044 BATT_06_event_outlt_clnt_thrm_op 2;
BA_ "SystemSignalLongSymbol" SG_ 2499763044 BATT_06_event_outlt_clnt_thrm_op "BATT_06_event_outlt_clnt_thrm_open";
BA_ "GenSigStartValue" SG_ 2499763044 BATT_06_event_neg_3_3_analog_err 2;
BA_ "SystemSignalLongSymbol" SG_ 2499763044 BATT_06_event_neg_3_3_analog_err "BATT_06_event_neg_3_3_analog_error";
BA_ "GenSigStartValue" SG_ 2499763044 BATT_06_event_inlet_clnt_thrm_op 2;
BA_ "SystemSignalLongSymbol" SG_ 2499763044 BATT_06_event_inlet_clnt_thrm_op "BATT_06_event_inlet_clnt_thrm_open";
BA_ "GenSigStartValue" SG_ 2499763044 BATT_06_event_hall_eff_lo_rang_e 2;
BA_ "SystemSignalLongSymbol" SG_ 2499763044 BATT_06_event_hall_eff_lo_rang_e "BATT_06_event_hall_eff_lo_rang_err";
BA_ "GenSigStartValue" SG_ 2499763044 BATT_06_event_outlt_clnt_thrm_sh 2;
BA_ "SystemSignalLongSymbol" SG_ 2499763044 BATT_06_event_outlt_clnt_thrm_sh "BATT_06_event_outlt_clnt_thrm_short";
BA_ "GenSigStartValue" SG_ 2499763044 BATT_06_event_inlet_clnt_thrm_sh 2;
BA_ "SystemSignalLongSymbol" SG_ 2499763044 BATT_06_event_inlet_clnt_thrm_sh "BATT_06_event_inlet_clnt_thrm_short";
BA_ "GenSigStartValue" SG_ 2499763044 BATT_06_event_3_3v_error 2;
BA_ "GenSigStartValue" SG_ 2499763044 BATT_07_HVILvoltageError 2;
BA_ "GenSigStartValue" SG_ 2499763044 BATT_07_HVILcurrentReturnError 2;
BA_ "GenSigStartValue" SG_ 2499763044 BATT_07_PosDcContWeldedSec 2;
BA_ "GenSigStartValue" SG_ 2499763044 BATT_07_PosDcContStuckOpenSec 2;
BA_ "GenSigStartValue" SG_ 2499763044 BATT_07_NegDcContWeldedSec 2;
BA_ "GenSigStartValue" SG_ 2499763044 BATT_07_NegDcContStuckOpenSec 2;
BA_ "GenSigStartValue" SG_ 2499763044 BATT_07_IsolationIntFault 2;
BA_ "GenSigStartValue" SG_ 2499763044 BATT_07_IsolationExtFault 2;
BA_ "GenSigStartValue" SG_ 2499763044 BATT_07_event_12v_filter_error 2;
BA_ "GenSigStartValue" SG_ 2499763044 BATT_07_event_hall_eff_hi_rang_e 2;
BA_ "SystemSignalLongSymbol" SG_ 2499763044 BATT_07_event_hall_eff_hi_rang_e "BATT_07_event_hall_eff_hi_rang_err";
BA_ "GenSigStartValue" SG_ 2499763044 BATT_07_event_brick_volt_sns_ope 2;
BA_ "SystemSignalLongSymbol" SG_ 2499763044 BATT_07_event_brick_volt_sns_ope "BATT_07_event_brick_volt_sns_open";
BA_ "GenSigStartValue" SG_ 2499763044 BATT_07_event_5v_error 2;
BA_ "GenSigStartValue" SG_ 2499763044 BATT_07_event_3_3_hot_error 2;
BA_ "GenSigStartValue" SG_ 2499763044 BATT_07_event_12v_input_error 2;
BA_ "GenSigStartValue" SG_ 2499763044 BATT_07_event_1_25v_error 2;
BA_ "GenSigStartValue" SG_ 2499763044 BATT_07_event_shunt_MIA 2;
BA_ "GenSigStartValue" SG_ 2499763044 BATT_07_event_SBC_int_reg_error 2;
BA_ "GenSigStartValue" SG_ 2499763044 BATT_07_event_pos_3_3v_analog_er 2;
BA_ "SystemSignalLongSymbol" SG_ 2499763044 BATT_07_event_pos_3_3v_analog_er "BATT_07_event_pos_3_3v_analog_error";
BA_ "GenSigStartValue" SG_ 2499763044 BATT_07_event_outlt_clnt_thrm_op 2;
BA_ "SystemSignalLongSymbol" SG_ 2499763044 BATT_07_event_outlt_clnt_thrm_op "BATT_07_event_outlt_clnt_thrm_open";
BA_ "GenSigStartValue" SG_ 2499763044 BATT_07_event_neg_3_3_analog_err 2;
BA_ "SystemSignalLongSymbol" SG_ 2499763044 BATT_07_event_neg_3_3_analog_err "BATT_07_event_neg_3_3_analog_error";
BA_ "GenSigStartValue" SG_ 2499763044 BATT_07_event_inlet_clnt_thrm_op 2;
BA_ "SystemSignalLongSymbol" SG_ 2499763044 BATT_07_event_inlet_clnt_thrm_op "BATT_07_event_inlet_clnt_thrm_open";
BA_ "GenSigStartValue" SG_ 2499763044 BATT_07_event_hall_eff_lo_rang_e 2;
BA_ "SystemSignalLongSymbol" SG_ 2499763044 BATT_07_event_hall_eff_lo_rang_e "BATT_07_event_hall_eff_lo_rang_err";
BA_ "GenSigStartValue" SG_ 2499763044 BATT_07_event_outlt_clnt_thrm_sh 2;
BA_ "SystemSignalLongSymbol" SG_ 2499763044 BATT_07_event_outlt_clnt_thrm_sh "BATT_07_event_outlt_clnt_thrm_short";
BA_ "GenSigStartValue" SG_ 2499763044 BATT_07_event_inlet_clnt_thrm_sh 2;
BA_ "SystemSignalLongSymbol" SG_ 2499763044 BATT_07_event_inlet_clnt_thrm_sh "BATT_07_event_inlet_clnt_thrm_short";
BA_ "GenSigStartValue" SG_ 2499763044 BATT_07_event_3_3v_error 2;
BA_ "GenSigStartValue" SG_ 2499763044 BATT_08_HVILvoltageError 2;
BA_ "GenSigStartValue" SG_ 2499763044 BATT_08_HVILcurrentReturnError 2;
BA_ "GenSigStartValue" SG_ 2499763044 BATT_08_PosDcContWeldedSec 2;
BA_ "GenSigStartValue" SG_ 2499763044 BATT_08_PosDcContStuckOpenSec 2;
BA_ "GenSigStartValue" SG_ 2499763044 BATT_08_NegDcContWeldedSec 2;
BA_ "GenSigStartValue" SG_ 2499763044 BATT_08_NegDcContStuckOpenSec 2;
BA_ "GenSigStartValue" SG_ 2499763044 BATT_08_IsolationIntFault 2;
BA_ "GenSigStartValue" SG_ 2499763044 BATT_08_IsolationExtFault 2;
BA_ "GenSigStartValue" SG_ 2499763044 BATT_08_event_12v_filter_error 2;
BA_ "GenSigStartValue" SG_ 2499763044 BATT_08_event_hall_eff_hi_rang_e 2;
BA_ "SystemSignalLongSymbol" SG_ 2499763044 BATT_08_event_hall_eff_hi_rang_e "BATT_08_event_hall_eff_hi_rang_err";
BA_ "GenSigStartValue" SG_ 2499763044 BATT_08_event_brick_volt_sns_ope 2;
BA_ "SystemSignalLongSymbol" SG_ 2499763044 BATT_08_event_brick_volt_sns_ope "BATT_08_event_brick_volt_sns_open";
BA_ "GenSigStartValue" SG_ 2499763044 BATT_08_event_5v_error 2;
BA_ "GenSigStartValue" SG_ 2499763044 BATT_08_event_3_3_hot_error 2;
BA_ "GenSigStartValue" SG_ 2499763044 BATT_08_event_12v_input_error 2;
BA_ "GenSigStartValue" SG_ 2499763044 BATT_08_event_1_25v_error 2;
BA_ "GenSigStartValue" SG_ 2499763044 BATT_08_event_shunt_MIA 2;
BA_ "GenSigStartValue" SG_ 2499763044 BATT_08_event_SBC_int_reg_error 2;
BA_ "GenSigStartValue" SG_ 2499763044 BATT_08_event_pos_3_3v_analog_er 2;
BA_ "SystemSignalLongSymbol" SG_ 2499763044 BATT_08_event_pos_3_3v_analog_er "BATT_08_event_pos_3_3v_analog_error";
BA_ "GenSigStartValue" SG_ 2499763044 BATT_08_event_outlt_clnt_thrm_op 2;
BA_ "SystemSignalLongSymbol" SG_ 2499763044 BATT_08_event_outlt_clnt_thrm_op "BATT_08_event_outlt_clnt_thrm_open";
BA_ "GenSigStartValue" SG_ 2499763044 BATT_08_event_neg_3_3_analog_err 2;
BA_ "SystemSignalLongSymbol" SG_ 2499763044 BATT_08_event_neg_3_3_analog_err "BATT_08_event_neg_3_3_analog_error";
BA_ "GenSigStartValue" SG_ 2499763044 BATT_08_event_inlet_clnt_thrm_op 2;
BA_ "SystemSignalLongSymbol" SG_ 2499763044 BATT_08_event_inlet_clnt_thrm_op "BATT_08_event_inlet_clnt_thrm_open";
BA_ "GenSigStartValue" SG_ 2499763044 BATT_08_event_hall_eff_lo_rang_e 2;
BA_ "SystemSignalLongSymbol" SG_ 2499763044 BATT_08_event_hall_eff_lo_rang_e "BATT_08_event_hall_eff_lo_rang_err";
BA_ "GenSigStartValue" SG_ 2499763044 BATT_08_event_outlt_clnt_thrm_sh 2;
BA_ "SystemSignalLongSymbol" SG_ 2499763044 BATT_08_event_outlt_clnt_thrm_sh "BATT_08_event_outlt_clnt_thrm_short";
BA_ "GenSigStartValue" SG_ 2499763044 BATT_08_event_inlet_clnt_thrm_sh 2;
BA_ "SystemSignalLongSymbol" SG_ 2499763044 BATT_08_event_inlet_clnt_thrm_sh "BATT_08_event_inlet_clnt_thrm_short";
BA_ "GenSigStartValue" SG_ 2499763044 BATT_08_event_3_3v_error 2;
BA_ "GenSigStartValue" SG_ 2499763044 BATT_09_HVILvoltageError 2;
BA_ "GenSigStartValue" SG_ 2499763044 BATT_09_HVILcurrentReturnError 2;
BA_ "GenSigStartValue" SG_ 2499763044 BATT_09_PosDcContWeldedSec 2;
BA_ "GenSigStartValue" SG_ 2499763044 BATT_09_NegDcContWeldedSec 2;
BA_ "GenSigStartValue" SG_ 2499763044 BATT_09_NegDcContStuckOpenSec 2;
BA_ "GenSigStartValue" SG_ 2499763044 BATT_09_PosDcContStuckOpenSec 2;
BA_ "GenSigStartValue" SG_ 2499763044 BATT_09_IsolationIntFault 2;
BA_ "GenSigStartValue" SG_ 2499763044 BATT_09_IsolationExtFault 2;
BA_ "GenSigStartValue" SG_ 2499763044 BATT_09_event_12v_filter_error 2;
BA_ "GenSigStartValue" SG_ 2499763044 BATT_09_event_hall_eff_hi_rang_e 2;
BA_ "SystemSignalLongSymbol" SG_ 2499763044 BATT_09_event_hall_eff_hi_rang_e "BATT_09_event_hall_eff_hi_rang_err";
BA_ "GenSigStartValue" SG_ 2499763044 BATT_09_event_brick_volt_sns_ope 2;
BA_ "SystemSignalLongSymbol" SG_ 2499763044 BATT_09_event_brick_volt_sns_ope "BATT_09_event_brick_volt_sns_open";
BA_ "GenSigStartValue" SG_ 2499763044 BATT_09_event_5v_error 2;
BA_ "GenSigStartValue" SG_ 2499763044 BATT_09_event_3_3_hot_error 2;
BA_ "GenSigStartValue" SG_ 2499763044 BATT_09_event_12v_input_error 2;
BA_ "GenSigStartValue" SG_ 2499763044 BATT_09_event_1_25v_error 2;
BA_ "GenSigStartValue" SG_ 2499763044 BATT_09_event_shunt_MIA 2;
BA_ "GenSigStartValue" SG_ 2499763044 BATT_09_event_SBC_int_reg_error 2;
BA_ "GenSigStartValue" SG_ 2499763044 BATT_09_event_pos_3_3v_analog_er 2;
BA_ "SystemSignalLongSymbol" SG_ 2499763044 BATT_09_event_pos_3_3v_analog_er "BATT_09_event_pos_3_3v_analog_error";
BA_ "GenSigStartValue" SG_ 2499763044 BATT_09_event_outlt_clnt_thrm_op 2;
BA_ "SystemSignalLongSymbol" SG_ 2499763044 BATT_09_event_outlt_clnt_thrm_op "BATT_09_event_outlt_clnt_thrm_open";
BA_ "GenSigStartValue" SG_ 2499763044 BATT_09_event_neg_3_3_analog_err 2;
BA_ "SystemSignalLongSymbol" SG_ 2499763044 BATT_09_event_neg_3_3_analog_err "BATT_09_event_neg_3_3_analog_error";
BA_ "GenSigStartValue" SG_ 2499763044 BATT_09_event_inlet_clnt_thrm_op 2;
BA_ "SystemSignalLongSymbol" SG_ 2499763044 BATT_09_event_inlet_clnt_thrm_op "BATT_09_event_inlet_clnt_thrm_open";
BA_ "GenSigStartValue" SG_ 2499763044 BATT_09_event_hall_eff_lo_rang_e 2;
BA_ "SystemSignalLongSymbol" SG_ 2499763044 BATT_09_event_hall_eff_lo_rang_e "BATT_09_event_hall_eff_lo_rang_err";
BA_ "GenSigStartValue" SG_ 2499763044 BATT_09_event_outlt_clnt_thrm_sh 2;
BA_ "SystemSignalLongSymbol" SG_ 2499763044 BATT_09_event_outlt_clnt_thrm_sh "BATT_09_event_outlt_clnt_thrm_short";
BA_ "GenSigStartValue" SG_ 2499763044 BATT_09_event_inlet_clnt_thrm_sh 2;
BA_ "SystemSignalLongSymbol" SG_ 2499763044 BATT_09_event_inlet_clnt_thrm_sh "BATT_09_event_inlet_clnt_thrm_short";
BA_ "GenSigStartValue" SG_ 2499763044 BATT_09_event_3_3v_error 2;
BA_ "GenSigStartValue" SG_ 2499763044 BATT_10_HVILvoltageError 2;
BA_ "GenSigStartValue" SG_ 2499763044 BATT_10_HVILcurrentReturnError 2;
BA_ "GenSigStartValue" SG_ 2499763044 BATT_10_PosDcContWeldedSec 2;
BA_ "GenSigStartValue" SG_ 2499763044 BATT_10_PosDcContStuckOpenSec 2;
BA_ "GenSigStartValue" SG_ 2499763044 BATT_10_NegDcContWeldedSec 2;
BA_ "GenSigStartValue" SG_ 2499763044 BATT_10_NegDcContStuckOpenSec 2;
BA_ "GenSigStartValue" SG_ 2499763044 BATT_10_IsolationIntFault 2;
BA_ "GenSigStartValue" SG_ 2499763044 BATT_10_IsolationExtFault 2;
BA_ "GenSigStartValue" SG_ 2499763044 BATT_10_event_12v_filter_error 2;
BA_ "GenSigStartValue" SG_ 2499763044 BATT_10_event_hall_eff_hi_rang_e 2;
BA_ "SystemSignalLongSymbol" SG_ 2499763044 BATT_10_event_hall_eff_hi_rang_e "BATT_10_event_hall_eff_hi_rang_err";
BA_ "GenSigStartValue" SG_ 2499763044 BATT_10_event_brick_volt_sns_ope 2;
BA_ "SystemSignalLongSymbol" SG_ 2499763044 BATT_10_event_brick_volt_sns_ope "BATT_10_event_brick_volt_sns_open";
BA_ "GenSigStartValue" SG_ 2499763044 BATT_10_event_5v_error 2;
BA_ "GenSigStartValue" SG_ 2499763044 BATT_10_event_3_3_hot_error 2;
BA_ "GenSigStartValue" SG_ 2499763044 BATT_10_event_12v_input_error 2;
BA_ "GenSigStartValue" SG_ 2499763044 BATT_10_event_1_25v_error 2;
BA_ "GenSigStartValue" SG_ 2499763044 BATT_10_event_shunt_MIA 2;
BA_ "GenSigStartValue" SG_ 2499763044 BATT_10_event_SBC_int_reg_error 2;
BA_ "GenSigStartValue" SG_ 2499763044 BATT_10_event_pos_3_3v_analog_er 2;
BA_ "SystemSignalLongSymbol" SG_ 2499763044 BATT_10_event_pos_3_3v_analog_er "BATT_10_event_pos_3_3v_analog_error";
BA_ "GenSigStartValue" SG_ 2499763044 BATT_10_event_outlt_clnt_thrm_op 2;
BA_ "SystemSignalLongSymbol" SG_ 2499763044 BATT_10_event_outlt_clnt_thrm_op "BATT_10_event_outlt_clnt_thrm_open";
BA_ "GenSigStartValue" SG_ 2499763044 BATT_10_event_neg_3_3_analog_err 2;
BA_ "SystemSignalLongSymbol" SG_ 2499763044 BATT_10_event_neg_3_3_analog_err "BATT_10_event_neg_3_3_analog_error";
BA_ "GenSigStartValue" SG_ 2499763044 BATT_10_event_inlet_clnt_thrm_op 2;
BA_ "SystemSignalLongSymbol" SG_ 2499763044 BATT_10_event_inlet_clnt_thrm_op "BATT_10_event_inlet_clnt_thrm_open";
BA_ "GenSigStartValue" SG_ 2499763044 BATT_10_event_hall_eff_lo_rang_e 2;
BA_ "SystemSignalLongSymbol" SG_ 2499763044 BATT_10_event_hall_eff_lo_rang_e "BATT_10_event_hall_eff_lo_rang_err";
BA_ "GenSigStartValue" SG_ 2499763044 BATT_10_event_outlt_clnt_thrm_sh 2;
BA_ "SystemSignalLongSymbol" SG_ 2499763044 BATT_10_event_outlt_clnt_thrm_sh "BATT_10_event_outlt_clnt_thrm_short";
BA_ "GenSigStartValue" SG_ 2499763044 BATT_10_event_inlet_clnt_thrm_sh 2;
BA_ "SystemSignalLongSymbol" SG_ 2499763044 BATT_10_event_inlet_clnt_thrm_sh "BATT_10_event_inlet_clnt_thrm_short";
BA_ "GenSigStartValue" SG_ 2499763044 BATT_10_event_3_3v_error 2;
BA_ "GenSigStartValue" SG_ 2499763044 BATT_11_HVILvoltageError 2;
BA_ "GenSigStartValue" SG_ 2499763044 BATT_11_HVILcurrentReturnError 2;
BA_ "GenSigStartValue" SG_ 2499763044 BATT_11_PosDcContWeldedSec 2;
BA_ "GenSigStartValue" SG_ 2499763044 BATT_11_PosDcContStuckOpenSec 2;
BA_ "GenSigStartValue" SG_ 2499763044 BATT_11_NegDcContWeldedSec 2;
BA_ "GenSigStartValue" SG_ 2499763044 BATT_11_NegDcContStuckOpenSec 2;
BA_ "GenSigStartValue" SG_ 2499763044 BATT_11_IsolationIntFault 2;
BA_ "GenSigStartValue" SG_ 2499763044 BATT_11_IsolationExtFault 2;
BA_ "GenSigStartValue" SG_ 2499763044 BATT_11_event_12v_filter_error 2;
BA_ "GenSigStartValue" SG_ 2499763044 BATT_11_event_hall_eff_hi_rang_e 2;
BA_ "SystemSignalLongSymbol" SG_ 2499763044 BATT_11_event_hall_eff_hi_rang_e "BATT_11_event_hall_eff_hi_rang_err";
BA_ "GenSigStartValue" SG_ 2499763044 BATT_11_event_brick_volt_sns_ope 2;
BA_ "SystemSignalLongSymbol" SG_ 2499763044 BATT_11_event_brick_volt_sns_ope "BATT_11_event_brick_volt_sns_open";
BA_ "GenSigStartValue" SG_ 2499763044 BATT_11_event_5v_error 2;
BA_ "GenSigStartValue" SG_ 2499763044 BATT_11_event_3_3_hot_error 2;
BA_ "GenSigStartValue" SG_ 2499763044 BATT_11_event_12v_input_error 2;
BA_ "GenSigStartValue" SG_ 2499763044 BATT_11_event_1_25v_error 2;
BA_ "GenSigStartValue" SG_ 2499763044 BATT_11_event_shunt_MIA 2;
BA_ "GenSigStartValue" SG_ 2499763044 BATT_11_event_SBC_int_reg_error 2;
BA_ "GenSigStartValue" SG_ 2499763044 BATT_11_event_pos_3_3v_analog_er 2;
BA_ "SystemSignalLongSymbol" SG_ 2499763044 BATT_11_event_pos_3_3v_analog_er "BATT_11_event_pos_3_3v_analog_error";
BA_ "GenSigStartValue" SG_ 2499763044 BATT_11_event_outlt_clnt_thrm_op 2;
BA_ "SystemSignalLongSymbol" SG_ 2499763044 BATT_11_event_outlt_clnt_thrm_op "BATT_11_event_outlt_clnt_thrm_open";
BA_ "GenSigStartValue" SG_ 2499763044 BATT_11_event_neg_3_3_analog_err 2;
BA_ "SystemSignalLongSymbol" SG_ 2499763044 BATT_11_event_neg_3_3_analog_err "BATT_11_event_neg_3_3_analog_error";
BA_ "GenSigStartValue" SG_ 2499763044 BATT_11_event_inlet_clnt_thrm_op 2;
BA_ "SystemSignalLongSymbol" SG_ 2499763044 BATT_11_event_inlet_clnt_thrm_op "BATT_11_event_inlet_clnt_thrm_open";
BA_ "GenSigStartValue" SG_ 2499763044 BATT_11_event_hall_eff_lo_rang_e 2;
BA_ "SystemSignalLongSymbol" SG_ 2499763044 BATT_11_event_hall_eff_lo_rang_e "BATT_11_event_hall_eff_lo_rang_err";
BA_ "GenSigStartValue" SG_ 2499763044 BATT_11_event_outlt_clnt_thrm_sh 2;
BA_ "SystemSignalLongSymbol" SG_ 2499763044 BATT_11_event_outlt_clnt_thrm_sh "BATT_11_event_outlt_clnt_thrm_short";
BA_ "GenSigStartValue" SG_ 2499763044 BATT_11_event_inlet_clnt_thrm_sh 2;
BA_ "SystemSignalLongSymbol" SG_ 2499763044 BATT_11_event_inlet_clnt_thrm_sh "BATT_11_event_inlet_clnt_thrm_short";
BA_ "GenSigStartValue" SG_ 2499763044 BATT_11_event_3_3v_error 2;
BA_ "GenSigStartValue" SG_ 2499763044 BATT_12_HVILvoltageError 2;
BA_ "GenSigStartValue" SG_ 2499763044 BATT_12_HVILcurrentReturnError 2;
BA_ "GenSigStartValue" SG_ 2499763044 BATT_12_PosDcContWeldedSec 2;
BA_ "GenSigStartValue" SG_ 2499763044 BATT_12_PosDcContStuckOpenSec 2;
BA_ "GenSigStartValue" SG_ 2499763044 BATT_12_NegDcContWeldedSec 2;
BA_ "GenSigStartValue" SG_ 2499763044 BATT_12_NegDcContStuckOpenSec 2;
BA_ "GenSigStartValue" SG_ 2499763044 BATT_12_IsolationIntFault 2;
BA_ "GenSigStartValue" SG_ 2499763044 BATT_12_IsolationExtFault 2;
BA_ "GenSigStartValue" SG_ 2499763044 BATT_12_event_12v_filter_error 2;
BA_ "GenSigStartValue" SG_ 2499763044 BATT_12_event_hall_eff_hi_rang_e 2;
BA_ "SystemSignalLongSymbol" SG_ 2499763044 BATT_12_event_hall_eff_hi_rang_e "BATT_12_event_hall_eff_hi_rang_err";
BA_ "GenSigStartValue" SG_ 2499763044 BATT_12_event_brick_volt_sns_ope 2;
BA_ "SystemSignalLongSymbol" SG_ 2499763044 BATT_12_event_brick_volt_sns_ope "BATT_12_event_brick_volt_sns_open";
BA_ "GenSigStartValue" SG_ 2499763044 BATT_12_event_5v_error 2;
BA_ "GenSigStartValue" SG_ 2499763044 BATT_12_event_3_3_hot_error 2;
BA_ "GenSigStartValue" SG_ 2499763044 BATT_12_event_12v_input_error 2;
BA_ "GenSigStartValue" SG_ 2499763044 BATT_12_event_1_25v_error 2;
BA_ "GenSigStartValue" SG_ 2499763044 BATT_12_event_shunt_MIA 2;
BA_ "GenSigStartValue" SG_ 2499763044 BATT_12_event_SBC_int_reg_error 2;
BA_ "GenSigStartValue" SG_ 2499763044 BATT_12_event_pos_3_3v_analog_er 2;
BA_ "SystemSignalLongSymbol" SG_ 2499763044 BATT_12_event_pos_3_3v_analog_er "BATT_12_event_pos_3_3v_analog_error";
BA_ "GenSigStartValue" SG_ 2499763044 BATT_12_event_outlt_clnt_thrm_op 2;
BA_ "SystemSignalLongSymbol" SG_ 2499763044 BATT_12_event_outlt_clnt_thrm_op "BATT_12_event_outlt_clnt_thrm_open";
BA_ "GenSigStartValue" SG_ 2499763044 BATT_12_event_neg_3_3_analog_err 2;
BA_ "SystemSignalLongSymbol" SG_ 2499763044 BATT_12_event_neg_3_3_analog_err "BATT_12_event_neg_3_3_analog_error";
BA_ "GenSigStartValue" SG_ 2499763044 BATT_12_event_inlet_clnt_thrm_op 2;
BA_ "SystemSignalLongSymbol" SG_ 2499763044 BATT_12_event_inlet_clnt_thrm_op "BATT_12_event_inlet_clnt_thrm_open";
BA_ "GenSigStartValue" SG_ 2499763044 BATT_12_event_hall_eff_lo_rang_e 2;
BA_ "SystemSignalLongSymbol" SG_ 2499763044 BATT_12_event_hall_eff_lo_rang_e "BATT_12_event_hall_eff_lo_rang_err";
BA_ "GenSigStartValue" SG_ 2499763044 BATT_12_event_outlt_clnt_thrm_sh 2;
BA_ "SystemSignalLongSymbol" SG_ 2499763044 BATT_12_event_outlt_clnt_thrm_sh "BATT_12_event_outlt_clnt_thrm_short";
BA_ "GenSigStartValue" SG_ 2499763044 BATT_12_event_inlet_clnt_thrm_sh 2;
BA_ "SystemSignalLongSymbol" SG_ 2499763044 BATT_12_event_inlet_clnt_thrm_sh "BATT_12_event_inlet_clnt_thrm_short";
BA_ "GenSigStartValue" SG_ 2499763044 BATT_12_event_3_3v_error 2;
BA_ "GenSigStartValue" SG_ 2499763044 BATT_13_HVILvoltageError 2;
BA_ "GenSigStartValue" SG_ 2499763044 BATT_13_HVILcurrentReturnError 2;
BA_ "GenSigStartValue" SG_ 2499763044 BATT_13_PosDcContWeldedSec 2;
BA_ "GenSigStartValue" SG_ 2499763044 BATT_13_PosDcContStuckOpenSec 2;
BA_ "GenSigStartValue" SG_ 2499763044 BATT_13_NegDcContWeldedSec 2;
BA_ "GenSigStartValue" SG_ 2499763044 BATT_13_NegDcContStuckOpenSec 2;
BA_ "GenSigStartValue" SG_ 2499763044 BATT_13_IsolationIntFault 2;
BA_ "GenSigStartValue" SG_ 2499763044 BATT_13_IsolationExtFault 2;
BA_ "GenSigStartValue" SG_ 2499763044 BATT_13_event_12v_filter_error 2;
BA_ "GenSigStartValue" SG_ 2499763044 BATT_13_event_hall_eff_hi_rang_e 2;
BA_ "SystemSignalLongSymbol" SG_ 2499763044 BATT_13_event_hall_eff_hi_rang_e "BATT_13_event_hall_eff_hi_rang_err";
BA_ "GenSigStartValue" SG_ 2499763044 BATT_13_event_brick_volt_sns_ope 2;
BA_ "SystemSignalLongSymbol" SG_ 2499763044 BATT_13_event_brick_volt_sns_ope "BATT_13_event_brick_volt_sns_open";
BA_ "GenSigStartValue" SG_ 2499763044 BATT_13_event_5v_error 2;
BA_ "GenSigStartValue" SG_ 2499763044 BATT_13_event_3_3_hot_error 2;
BA_ "GenSigStartValue" SG_ 2499763044 BATT_13_event_12v_input_error 2;
BA_ "GenSigStartValue" SG_ 2499763044 BATT_13_event_1_25v_error 2;
BA_ "GenSigStartValue" SG_ 2499763044 BATT_13_event_shunt_MIA 2;
BA_ "GenSigStartValue" SG_ 2499763044 BATT_13_event_SBC_int_reg_error 2;
BA_ "GenSigStartValue" SG_ 2499763044 BATT_13_event_pos_3_3v_analog_er 2;
BA_ "SystemSignalLongSymbol" SG_ 2499763044 BATT_13_event_pos_3_3v_analog_er "BATT_13_event_pos_3_3v_analog_error";
BA_ "GenSigStartValue" SG_ 2499763044 BATT_13_event_outlt_clnt_thrm_op 2;
BA_ "SystemSignalLongSymbol" SG_ 2499763044 BATT_13_event_outlt_clnt_thrm_op "BATT_13_event_outlt_clnt_thrm_open";
BA_ "GenSigStartValue" SG_ 2499763044 BATT_13_event_neg_3_3_analog_err 2;
BA_ "SystemSignalLongSymbol" SG_ 2499763044 BATT_13_event_neg_3_3_analog_err "BATT_13_event_neg_3_3_analog_error";
BA_ "GenSigStartValue" SG_ 2499763044 BATT_13_event_inlet_clnt_thrm_op 2;
BA_ "SystemSignalLongSymbol" SG_ 2499763044 BATT_13_event_inlet_clnt_thrm_op "BATT_13_event_inlet_clnt_thrm_open";
BA_ "GenSigStartValue" SG_ 2499763044 BATT_13_event_hall_eff_lo_rang_e 2;
BA_ "SystemSignalLongSymbol" SG_ 2499763044 BATT_13_event_hall_eff_lo_rang_e "BATT_13_event_hall_eff_lo_rang_err";
BA_ "GenSigStartValue" SG_ 2499763044 BATT_13_event_outlt_clnt_thrm_sh 2;
BA_ "SystemSignalLongSymbol" SG_ 2499763044 BATT_13_event_outlt_clnt_thrm_sh "BATT_13_event_outlt_clnt_thrm_short";
BA_ "GenSigStartValue" SG_ 2499763044 BATT_13_event_inlet_clnt_thrm_sh 2;
BA_ "SystemSignalLongSymbol" SG_ 2499763044 BATT_13_event_inlet_clnt_thrm_sh "BATT_13_event_inlet_clnt_thrm_short";
BA_ "GenSigStartValue" SG_ 2499763044 BATT_13_event_3_3v_error 2;
BA_ "GenSigStartValue" SG_ 2499763044 BATT_14_HVILvoltageError 2;
BA_ "GenSigStartValue" SG_ 2499763044 BATT_14_HVILcurrentReturnError 2;
BA_ "GenSigStartValue" SG_ 2499763044 BATT_14_PosDcContWeldedSec 2;
BA_ "GenSigStartValue" SG_ 2499763044 BATT_14_PosDcContStuckOpenSec 2;
BA_ "GenSigStartValue" SG_ 2499763044 BATT_14_NegDcContWeldedSec 2;
BA_ "GenSigStartValue" SG_ 2499763044 BATT_14_NegDcContStuckOpenSec 2;
BA_ "GenSigStartValue" SG_ 2499763044 BATT_14_IsolationIntFault 2;
BA_ "GenSigStartValue" SG_ 2499763044 BATT_14_IsolationExtFault 2;
BA_ "GenSigStartValue" SG_ 2499763044 BATT_14_event_12v_filter_error 2;
BA_ "GenSigStartValue" SG_ 2499763044 BATT_14_event_hall_eff_hi_rang_e 2;
BA_ "SystemSignalLongSymbol" SG_ 2499763044 BATT_14_event_hall_eff_hi_rang_e "BATT_14_event_hall_eff_hi_rang_err";
BA_ "GenSigStartValue" SG_ 2499763044 BATT_14_event_brick_volt_sns_ope 2;
BA_ "SystemSignalLongSymbol" SG_ 2499763044 BATT_14_event_brick_volt_sns_ope "BATT_14_event_brick_volt_sns_open";
BA_ "GenSigStartValue" SG_ 2499763044 BATT_14_event_5v_error 2;
BA_ "GenSigStartValue" SG_ 2499763044 BATT_14_event_3_3_hot_error 2;
BA_ "GenSigStartValue" SG_ 2499763044 BATT_14_event_12v_input_error 2;
BA_ "GenSigStartValue" SG_ 2499763044 BATT_14_event_1_25v_error 2;
BA_ "GenSigStartValue" SG_ 2499763044 BATT_14_event_shunt_MIA 2;
BA_ "GenSigStartValue" SG_ 2499763044 BATT_14_event_SBC_int_reg_error 2;
BA_ "GenSigStartValue" SG_ 2499763044 BATT_14_event_pos_3_3v_analog_er 2;
BA_ "SystemSignalLongSymbol" SG_ 2499763044 BATT_14_event_pos_3_3v_analog_er "BATT_14_event_pos_3_3v_analog_error";
BA_ "GenSigStartValue" SG_ 2499763044 BATT_14_event_outlt_clnt_thrm_op 2;
BA_ "SystemSignalLongSymbol" SG_ 2499763044 BATT_14_event_outlt_clnt_thrm_op "BATT_14_event_outlt_clnt_thrm_open";
BA_ "GenSigStartValue" SG_ 2499763044 BATT_14_event_neg_3_3_analog_err 2;
BA_ "SystemSignalLongSymbol" SG_ 2499763044 BATT_14_event_neg_3_3_analog_err "BATT_14_event_neg_3_3_analog_error";
BA_ "GenSigStartValue" SG_ 2499763044 BATT_14_event_inlet_clnt_thrm_op 2;
BA_ "SystemSignalLongSymbol" SG_ 2499763044 BATT_14_event_inlet_clnt_thrm_op "BATT_14_event_inlet_clnt_thrm_open";
BA_ "GenSigStartValue" SG_ 2499763044 BATT_14_event_hall_eff_lo_rang_e 2;
BA_ "SystemSignalLongSymbol" SG_ 2499763044 BATT_14_event_hall_eff_lo_rang_e "BATT_14_event_hall_eff_lo_rang_err";
BA_ "GenSigStartValue" SG_ 2499763044 BATT_14_event_outlt_clnt_thrm_sh 2;
BA_ "SystemSignalLongSymbol" SG_ 2499763044 BATT_14_event_outlt_clnt_thrm_sh "BATT_14_event_outlt_clnt_thrm_short";
BA_ "GenSigStartValue" SG_ 2499763044 BATT_14_event_inlet_clnt_thrm_sh 2;
BA_ "SystemSignalLongSymbol" SG_ 2499763044 BATT_14_event_inlet_clnt_thrm_sh "BATT_14_event_inlet_clnt_thrm_short";
BA_ "GenSigStartValue" SG_ 2499763044 BATT_14_event_3_3v_error 2;
BA_ "GenSigStartValue" SG_ 2499763044 BATT_15_HVILvoltageError 2;
BA_ "GenSigStartValue" SG_ 2499763044 BATT_15_HVILcurrentReturnError 2;
BA_ "GenSigStartValue" SG_ 2499763044 BATT_15_PosDcContWeldedSec 2;
BA_ "GenSigStartValue" SG_ 2499763044 BATT_15_PosDcContStuckOpenSec 2;
BA_ "GenSigStartValue" SG_ 2499763044 BATT_15_NegDcContWeldedSec 2;
BA_ "GenSigStartValue" SG_ 2499763044 BATT_15_NegDcContStuckOpenSec 2;
BA_ "GenSigStartValue" SG_ 2499763044 BATT_15_IsolationIntFault 2;
BA_ "GenSigStartValue" SG_ 2499763044 BATT_15_IsolationExtFault 2;
BA_ "GenSigStartValue" SG_ 2499763044 BATT_15_event_12v_filter_error 2;
BA_ "GenSigStartValue" SG_ 2499763044 BATT_15_event_hall_eff_hi_rang_e 2;
BA_ "SystemSignalLongSymbol" SG_ 2499763044 BATT_15_event_hall_eff_hi_rang_e "BATT_15_event_hall_eff_hi_rang_err";
BA_ "GenSigStartValue" SG_ 2499763044 BATT_15_event_brick_volt_sns_ope 2;
BA_ "SystemSignalLongSymbol" SG_ 2499763044 BATT_15_event_brick_volt_sns_ope "BATT_15_event_brick_volt_sns_open";
BA_ "GenSigStartValue" SG_ 2499763044 BATT_15_event_5v_error 2;
BA_ "GenSigStartValue" SG_ 2499763044 BATT_15_event_3_3_hot_error 2;
BA_ "GenSigStartValue" SG_ 2499763044 BATT_15_event_12v_input_error 2;
BA_ "GenSigStartValue" SG_ 2499763044 BATT_15_event_1_25v_error 2;
BA_ "GenSigStartValue" SG_ 2499763044 BATT_15_event_shunt_MIA 2;
BA_ "GenSigStartValue" SG_ 2499763044 BATT_15_event_SBC_int_reg_error 2;
BA_ "GenSigStartValue" SG_ 2499763044 BATT_15_event_pos_3_3v_analog_er 2;
BA_ "SystemSignalLongSymbol" SG_ 2499763044 BATT_15_event_pos_3_3v_analog_er "BATT_15_event_pos_3_3v_analog_error";
BA_ "GenSigStartValue" SG_ 2499763044 BATT_15_event_outlt_clnt_thrm_op 2;
BA_ "SystemSignalLongSymbol" SG_ 2499763044 BATT_15_event_outlt_clnt_thrm_op "BATT_15_event_outlt_clnt_thrm_open";
BA_ "GenSigStartValue" SG_ 2499763044 BATT_15_event_neg_3_3_analog_err 2;
BA_ "SystemSignalLongSymbol" SG_ 2499763044 BATT_15_event_neg_3_3_analog_err "BATT_15_event_neg_3_3_analog_error";
BA_ "GenSigStartValue" SG_ 2499763044 BATT_15_event_inlet_clnt_thrm_op 2;
BA_ "SystemSignalLongSymbol" SG_ 2499763044 BATT_15_event_inlet_clnt_thrm_op "BATT_15_event_inlet_clnt_thrm_open";
BA_ "GenSigStartValue" SG_ 2499763044 BATT_15_event_hall_eff_lo_rang_e 2;
BA_ "SystemSignalLongSymbol" SG_ 2499763044 BATT_15_event_hall_eff_lo_rang_e "BATT_15_event_hall_eff_lo_rang_err";
BA_ "GenSigStartValue" SG_ 2499763044 BATT_15_event_outlt_clnt_thrm_sh 2;
BA_ "SystemSignalLongSymbol" SG_ 2499763044 BATT_15_event_outlt_clnt_thrm_sh "BATT_15_event_outlt_clnt_thrm_short";
BA_ "GenSigStartValue" SG_ 2499763044 BATT_15_event_inlet_clnt_thrm_sh 2;
BA_ "SystemSignalLongSymbol" SG_ 2499763044 BATT_15_event_inlet_clnt_thrm_sh "BATT_15_event_inlet_clnt_thrm_short";
BA_ "GenSigStartValue" SG_ 2499763044 BATT_15_event_3_3v_error 2;
VAL_ 2499759204 BATT_SystemState_1 14 "Unknown" 13 "Disconnect" 12 "Charge" 11 "Drive" 10 "ExternalIsoTestCharge" 9 "ExternalIsoTestDrive" 8 "ConnectChargeStagger" 7 "ConnectChargeBusJoin" 6 "ConnectChargePrechg" 5 "ConnectDriveStagger" 4 "ConnectDriveBusJoin" 3 "ConnectDrivePrechg" 2 "StandbyReady" 1 "StandbyNotReady" 0 "Cooldown" ;
VAL_ 2499759460 BATT_SystemState_2 14 "Unknown" 13 "Disconnect" 12 "Charge" 11 "Drive" 10 "ExternalIsoTestCharge" 9 "ExternalIsoTestDrive" 8 "ConnectChargeStagger" 7 "ConnectChargeBusJoin" 6 "ConnectChargePrechg" 5 "ConnectDriveStagger" 4 "ConnectDriveBusJoin" 3 "ConnectDrivePrechg" 2 "StandbyReady" 1 "StandbyNotReady" 0 "Cooldown" ;
VAL_ 2499763300 BATT_01_ModuleThermFaultSevere 3 "Error" 2 "SNA" 1 "Active" 0 "Inactive" ;
VAL_ 2499763300 BATT_02_ModuleThermFaultSevere 3 "Error" 2 "SNA" 1 "Active" 0 "Inactive" ;
VAL_ 2499763300 BATT_03_ModuleThermFaultSevere 3 "Error" 2 "SNA" 1 "Active" 0 "Inactive" ;
VAL_ 2499763300 BATT_04_ModuleThermFaultSevere 3 "Error" 2 "SNA" 1 "Active" 0 "Inactive" ;
VAL_ 2499763300 BATT_05_ModuleThermFaultSevere 3 "Error" 2 "SNA" 1 "Active" 0 "Inactive" ;
VAL_ 2499763300 BATT_06_ModuleThermFaultSevere 3 "Error" 2 "SNA" 1 "Active" 0 "Inactive" ;
VAL_ 2499763300 BATT_07_ModuleThermFaultSevere 3 "Error" 2 "SNA" 1 "Active" 0 "Inactive" ;
VAL_ 2499763300 BATT_08_ModuleThermFaultSevere 3 "Error" 2 "SNA" 1 "Active" 0 "Inactive" ;
VAL_ 2499763300 BATT_09_ModuleThermFaultSevere 3 "Error" 2 "SNA" 1 "Active" 0 "Inactive" ;
VAL_ 2499763300 BATT_10_ModuleThermFaultSevere 3 "Error" 2 "SNA" 1 "Active" 0 "Inactive" ;
VAL_ 2499763300 BATT_11_ModuleThermFaultSevere 3 "Error" 2 "SNA" 1 "Active" 0 "Inactive" ;
VAL_ 2499763300 BATT_12_ModuleThermFaultSevere 3 "Error" 2 "SNA" 1 "Active" 0 "Inactive" ;
VAL_ 2499763300 BATT_13_ModuleThermFaultSevere 3 "Error" 2 "SNA" 1 "Active" 0 "Inactive" ;
VAL_ 2499763300 BATT_14_ModuleThermFaultSevere 3 "Error" 2 "SNA" 1 "Active" 0 "Inactive" ;
VAL_ 2499763300 BATT_15_ModuleThermFaultSevere 3 "Error" 2 "SNA" 1 "Active" 0 "Inactive" ;
VAL_ 2499763044 BATT_01_HVILvoltageError 3 "Error" 2 "SNA" 1 "Active" 0 "Inactive" ;
VAL_ 2499763044 BATT_01_HVILcurrentReturnError 3 "Error" 2 "SNA" 1 "Active" 0 "Inactive" ;
VAL_ 2499763044 BATT_01_PosDcContWeldedSec 3 "Error" 2 "SNA" 1 "Active" 0 "Inactive" ;
VAL_ 2499763044 BATT_01_PosDcContStuckOpenSec 3 "Error" 2 "SNA" 1 "Active" 0 "Inactive" ;
VAL_ 2499763044 BATT_01_NegDcContWeldedSec 3 "Error" 2 "SNA" 1 "Active" 0 "Inactive" ;
VAL_ 2499763044 BATT_01_NegDcContStuckOpenSec 3 "Error" 2 "SNA" 1 "Active" 0 "Inactive" ;
VAL_ 2499763044 BATT_01_IsolationIntFault 3 "Error" 2 "SNA" 1 "Active" 0 "Inactive" ;
VAL_ 2499763044 BATT_01_IsolationExtFault 3 "Error" 2 "SNA" 1 "Active" 0 "Inactive" ;
VAL_ 2499763044 BATT_01_event_12v_filter_error 3 "Error" 2 "SNA" 1 "Active" 0 "Inactive" ;
VAL_ 2499763044 BATT_01_event_hall_eff_hi_rang_e 3 "Error" 2 "SNA" 1 "Active" 0 "Inactive" ;
VAL_ 2499763044 BATT_01_event_brick_volt_sns_ope 3 "Error" 2 "SNA" 1 "Active" 0 "Inactive" ;
VAL_ 2499763044 BATT_01_event_5v_error 3 "Error" 2 "SNA" 1 "Active" 0 "Inactive" ;
VAL_ 2499763044 BATT_01_event_3_3_hot_error 3 "Error" 2 "SNA" 1 "Active" 0 "Inactive" ;
VAL_ 2499763044 BATT_01_event_12v_input_error 3 "Error" 2 "SNA" 1 "Active" 0 "Inactive" ;
VAL_ 2499763044 BATT_01_event_1_25v_error 3 "Error" 2 "SNA" 1 "Active" 0 "Inactive" ;
VAL_ 2499763044 BATT_01_event_shunt_MIA 3 "Error" 2 "SNA" 1 "Active" 0 "Inactive" ;
VAL_ 2499763044 BATT_01_event_SBC_int_reg_error 3 "Error" 2 "SNA" 1 "Active" 0 "Inactive" ;
VAL_ 2499763044 BATT_01_event_pos_3_3v_analog_er 3 "Error" 2 "SNA" 1 "Active" 0 "Inactive" ;
VAL_ 2499763044 BATT_01_event_outlt_clnt_thrm_op 3 "Error" 2 "SNA" 1 "Active" 0 "Inactive" ;
VAL_ 2499763044 BATT_01_event_neg_3_3_analog_err 3 "Error" 2 "SNA" 1 "Active" 0 "Inactive" ;
VAL_ 2499763044 BATT_01_event_inlet_clnt_thrm_op 3 "Error" 2 "SNA" 1 "Active" 0 "Inactive" ;
VAL_ 2499763044 BATT_01_event_hall_eff_lo_rang_e 3 "Error" 2 "SNA" 1 "Active" 0 "Inactive" ;
VAL_ 2499763044 BATT_01_event_outlt_clnt_thrm_sh 3 "Error" 2 "SNA" 1 "Active" 0 "Inactive" ;
VAL_ 2499763044 BATT_01_event_inlet_clnt_thrm_sh 3 "Error" 2 "SNA" 1 "Active" 0 "Inactive" ;
VAL_ 2499763044 BATT_01_event_3_3v_error 3 "Error" 2 "SNA" 1 "Active" 0 "Inactive" ;
VAL_ 2499763044 BATT_02_HVILvoltageError 3 "Error" 2 "SNA" 1 "Active" 0 "Inactive" ;
VAL_ 2499763044 BATT_02_HVILcurrentReturnError 3 "Error" 2 "SNA" 1 "Active" 0 "Inactive" ;
VAL_ 2499763044 BATT_02_PosDcContWeldedSec 3 "Error" 2 "SNA" 1 "Active" 0 "Inactive" ;
VAL_ 2499763044 BATT_02_PosDcContStuckOpenSec 3 "Error" 2 "SNA" 1 "Active" 0 "Inactive" ;
VAL_ 2499763044 BATT_02_NegDcContWeldedSec 3 "Error" 2 "SNA" 1 "Active" 0 "Inactive" ;
VAL_ 2499763044 BATT_02_NegDcContStuckOpenSec 3 "Error" 2 "SNA" 1 "Active" 0 "Inactive" ;
VAL_ 2499763044 BATT_02_IsolationIntFault 3 "Error" 2 "SNA" 1 "Active" 0 "Inactive" ;
VAL_ 2499763044 BATT_02_IsolationExtFault 3 "Error" 2 "SNA" 1 "Active" 0 "Inactive" ;
VAL_ 2499763044 BATT_02_event_12v_filter_error 3 "Error" 2 "SNA" 1 "Active" 0 "Inactive" ;
VAL_ 2499763044 BATT_02_event_hall_eff_hi_rang_e 3 "Error" 2 "SNA" 1 "Active" 0 "Inactive" ;
VAL_ 2499763044 BATT_02_event_brick_volt_sns_ope 3 "Error" 2 "SNA" 1 "Active" 0 "Inactive" ;
VAL_ 2499763044 BATT_02_event_5v_error 3 "Error" 2 "SNA" 1 "Active" 0 "Inactive" ;
VAL_ 2499763044 BATT_02_event_3_3_hot_error 3 "Error" 2 "SNA" 1 "Active" 0 "Inactive" ;
VAL_ 2499763044 BATT_02_event_12v_input_error 3 "Error" 2 "SNA" 1 "Active" 0 "Inactive" ;
VAL_ 2499763044 BATT_02_event_1_25v_error 3 "Error" 2 "SNA" 1 "Active" 0 "Inactive" ;
VAL_ 2499763044 BATT_02_event_shunt_MIA 3 "Error" 2 "SNA" 1 "Active" 0 "Inactive" ;
VAL_ 2499763044 BATT_02_event_SBC_int_reg_error 3 "Error" 2 "SNA" 1 "Active" 0 "Inactive" ;
VAL_ 2499763044 BATT_02_event_pos_3_3v_analog_er 3 "Error" 2 "SNA" 1 "Active" 0 "Inactive" ;
VAL_ 2499763044 BATT_02_event_outlt_clnt_thrm_op 3 "Error" 2 "SNA" 1 "Active" 0 "Inactive" ;
VAL_ 2499763044 BATT_02_event_neg_3_3_analog_err 3 "Error" 2 "SNA" 1 "Active" 0 "Inactive" ;
VAL_ 2499763044 BATT_02_event_inlet_clnt_thrm_op 3 "Error" 2 "SNA" 1 "Active" 0 "Inactive" ;
VAL_ 2499763044 BATT_02_event_hall_eff_lo_rang_e 3 "Error" 2 "SNA" 1 "Active" 0 "Inactive" ;
VAL_ 2499763044 BATT_02_event_outlt_clnt_thrm_sh 3 "Error" 2 "SNA" 1 "Active" 0 "Inactive" ;
VAL_ 2499763044 BATT_02_event_inlet_clnt_thrm_sh 3 "Error" 2 "SNA" 1 "Active" 0 "Inactive" ;
VAL_ 2499763044 BATT_02_event_3_3v_error 3 "Error" 2 "SNA" 1 "Active" 0 "Inactive" ;
VAL_ 2499763044 BATT_03_HVILvoltageError 3 "Error" 2 "SNA" 1 "Active" 0 "Inactive" ;
VAL_ 2499763044 BATT_03_HVILcurrentReturnError 3 "Error" 2 "SNA" 1 "Active" 0 "Inactive" ;
VAL_ 2499763044 BATT_03_PosDcContWeldedSec 3 "Error" 2 "SNA" 1 "Active" 0 "Inactive" ;
VAL_ 2499763044 BATT_03_PosDcContStuckOpenSec 3 "Error" 2 "SNA" 1 "Active" 0 "Inactive" ;
VAL_ 2499763044 BATT_03_NegDcContWeldedSec 3 "Error" 2 "SNA" 1 "Active" 0 "Inactive" ;
VAL_ 2499763044 BATT_03_NegDcContStuckOpenSec 3 "Error" 2 "SNA" 1 "Active" 0 "Inactive" ;
VAL_ 2499763044 BATT_03_IsolationIntFault 3 "Error" 2 "SNA" 1 "Active" 0 "Inactive" ;
VAL_ 2499763044 BATT_03_IsolationExtFault 3 "Error" 2 "SNA" 1 "Active" 0 "Inactive" ;
VAL_ 2499763044 BATT_03_event_12v_filter_error 3 "Error" 2 "SNA" 1 "Active" 0 "Inactive" ;
VAL_ 2499763044 BATT_03_event_hall_eff_hi_rang_e 3 "Error" 2 "SNA" 1 "Active" 0 "Inactive" ;
VAL_ 2499763044 BATT_03_event_brick_volt_sns_ope 3 "Error" 2 "SNA" 1 "Active" 0 "Inactive" ;
VAL_ 2499763044 BATT_03_event_5v_error 3 "Error" 2 "SNA" 1 "Active" 0 "Inactive" ;
VAL_ 2499763044 BATT_03_event_3_3_hot_error 3 "Error" 2 "SNA" 1 "Active" 0 "Inactive" ;
VAL_ 2499763044 BATT_03_event_12v_input_error 3 "Error" 2 "SNA" 1 "Active" 0 "Inactive" ;
VAL_ 2499763044 BATT_03_event_1_25v_error 3 "Error" 2 "SNA" 1 "Active" 0 "Inactive" ;
VAL_ 2499763044 BATT_03_event_shunt_MIA 3 "Error" 2 "SNA" 1 "Active" 0 "Inactive" ;
VAL_ 2499763044 BATT_03_event_SBC_int_reg_error 3 "Error" 2 "SNA" 1 "Active" 0 "Inactive" ;
VAL_ 2499763044 BATT_03_event_pos_3_3v_analog_er 3 "Error" 2 "SNA" 1 "Active" 0 "Inactive" ;
VAL_ 2499763044 BATT_03_event_outlt_clnt_thrm_op 3 "Error" 2 "SNA" 1 "Active" 0 "Inactive" ;
VAL_ 2499763044 BATT_03_event_neg_3_3_analog_err 3 "Error" 2 "SNA" 1 "Active" 0 "Inactive" ;
VAL_ 2499763044 BATT_03_event_inlet_clnt_thrm_op 3 "Error" 2 "SNA" 1 "Active" 0 "Inactive" ;
VAL_ 2499763044 BATT_03_event_hall_eff_lo_rang_e 3 "Error" 2 "SNA" 1 "Active" 0 "Inactive" ;
VAL_ 2499763044 BATT_03_event_outlt_clnt_thrm_sh 3 "Error" 2 "SNA" 1 "Active" 0 "Inactive" ;
VAL_ 2499763044 BATT_03_event_inlet_clnt_thrm_sh 3 "Error" 2 "SNA" 1 "Active" 0 "Inactive" ;
VAL_ 2499763044 BATT_03_event_3_3v_error 3 "Error" 2 "SNA" 1 "Active" 0 "Inactive" ;
VAL_ 2499763044 BATT_04_HVILvoltageError 3 "Error" 2 "SNA" 1 "Active" 0 "Inactive" ;
VAL_ 2499763044 BATT_04_HVILcurrentReturnError 3 "Error" 2 "SNA" 1 "Active" 0 "Inactive" ;
VAL_ 2499763044 BATT_04_PosDcContWeldedSec 3 "Error" 2 "SNA" 1 "Active" 0 "Inactive" ;
VAL_ 2499763044 BATT_04_PosDcContStuckOpenSec 3 "Error" 2 "SNA" 1 "Active" 0 "Inactive" ;
VAL_ 2499763044 BATT_04_NegDcContWeldedSec 3 "Error" 2 "SNA" 1 "Active" 0 "Inactive" ;
VAL_ 2499763044 BATT_04_NegDcContStuckOpenSec 3 "Error" 2 "SNA" 1 "Active" 0 "Inactive" ;
VAL_ 2499763044 BATT_04_IsolationIntFault 3 "Error" 2 "SNA" 1 "Active" 0 "Inactive" ;
VAL_ 2499763044 BATT_04_IsolationExtFault 3 "Error" 2 "SNA" 1 "Active" 0 "Inactive" ;
VAL_ 2499763044 BATT_04_event_12v_filter_error 3 "Error" 2 "SNA" 1 "Active" 0 "Inactive" ;
VAL_ 2499763044 BATT_04_event_hall_eff_hi_rang_e 3 "Error" 2 "SNA" 1 "Active" 0 "Inactive" ;
VAL_ 2499763044 BATT_04_event_brick_volt_sns_ope 3 "Error" 2 "SNA" 1 "Active" 0 "Inactive" ;
VAL_ 2499763044 BATT_04_event_5v_error 3 "Error" 2 "SNA" 1 "Active" 0 "Inactive" ;
VAL_ 2499763044 BATT_04_event_3_3_hot_error 3 "Error" 2 "SNA" 1 "Active" 0 "Inactive" ;
VAL_ 2499763044 BATT_04_event_12v_input_error 3 "Error" 2 "SNA" 1 "Active" 0 "Inactive" ;
VAL_ 2499763044 BATT_04_event_1_25v_error 3 "Error" 2 "SNA" 1 "Active" 0 "Inactive" ;
VAL_ 2499763044 BATT_04_event_shunt_MIA 3 "Error" 2 "SNA" 1 "Active" 0 "Inactive" ;
VAL_ 2499763044 BATT_04_event_SBC_int_reg_error 3 "Error" 2 "SNA" 1 "Active" 0 "Inactive" ;
VAL_ 2499763044 BATT_04_event_pos_3_3v_analog_er 3 "Error" 2 "SNA" 1 "Active" 0 "Inactive" ;
VAL_ 2499763044 BATT_04_event_outlt_clnt_thrm_op 3 "Error" 2 "SNA" 1 "Active" 0 "Inactive" ;
VAL_ 2499763044 BATT_04_event_neg_3_3_analog_err 3 "Error" 2 "SNA" 1 "Active" 0 "Inactive" ;
VAL_ 2499763044 BATT_04_event_inlet_clnt_thrm_op 3 "Error" 2 "SNA" 1 "Active" 0 "Inactive" ;
VAL_ 2499763044 BATT_04_event_hall_eff_lo_rang_e 3 "Error" 2 "SNA" 1 "Active" 0 "Inactive" ;
VAL_ 2499763044 BATT_04_event_outlt_clnt_thrm_sh 3 "Error" 2 "SNA" 1 "Active" 0 "Inactive" ;
VAL_ 2499763044 BATT_04_event_inlet_clnt_thrm_sh 3 "Error" 2 "SNA" 1 "Active" 0 "Inactive" ;
VAL_ 2499763044 BATT_04_event_3_3v_error 3 "Error" 2 "SNA" 1 "Active" 0 "Inactive" ;
VAL_ 2499763044 BATT_05_HVILvoltageError 3 "Error" 2 "SNA" 1 "Active" 0 "Inactive" ;
VAL_ 2499763044 BATT_05_HVILcurrentReturnError 3 "Error" 2 "SNA" 1 "Active" 0 "Inactive" ;
VAL_ 2499763044 BATT_05_PosDcContWeldedSec 3 "Error" 2 "SNA" 1 "Active" 0 "Inactive" ;
VAL_ 2499763044 BATT_05_PosDcContStuckOpenSec 3 "Error" 2 "SNA" 1 "Active" 0 "Inactive" ;
VAL_ 2499763044 BATT_05_NegDcContWeldedSec 3 "Error" 2 "SNA" 1 "Active" 0 "Inactive" ;
VAL_ 2499763044 BATT_05_NegDcContStuckOpenSec 3 "Error" 2 "SNA" 1 "Active" 0 "Inactive" ;
VAL_ 2499763044 BATT_05_IsolationIntFault 3 "Error" 2 "SNA" 1 "Active" 0 "Inactive" ;
VAL_ 2499763044 BATT_05_IsolationExtFault 3 "Error" 2 "SNA" 1 "Active" 0 "Inactive" ;
VAL_ 2499763044 BATT_05_event_12v_filter_error 3 "Error" 2 "SNA" 1 "Active" 0 "Inactive" ;
VAL_ 2499763044 BATT_05_event_hall_eff_hi_rang_e 3 "Error" 2 "SNA" 1 "Active" 0 "Inactive" ;
VAL_ 2499763044 BATT_05_event_brick_volt_sns_ope 3 "Error" 2 "SNA" 1 "Active" 0 "Inactive" ;
VAL_ 2499763044 BATT_05_event_5v_error 3 "Error" 2 "SNA" 1 "Active" 0 "Inactive" ;
VAL_ 2499763044 BATT_05_event_3_3_hot_error 3 "Error" 2 "SNA" 1 "Active" 0 "Inactive" ;
VAL_ 2499763044 BATT_05_event_12v_input_error 3 "Error" 2 "SNA" 1 "Active" 0 "Inactive" ;
VAL_ 2499763044 BATT_05_event_1_25v_error 3 "Error" 2 "SNA" 1 "Active" 0 "Inactive" ;
VAL_ 2499763044 BATT_05_event_shunt_MIA 3 "Error" 2 "SNA" 1 "Active" 0 "Inactive" ;
VAL_ 2499763044 BATT_05_event_SBC_int_reg_error 3 "Error" 2 "SNA" 1 "Active" 0 "Inactive" ;
VAL_ 2499763044 BATT_05_event_pos_3_3v_analog_er 3 "Error" 2 "SNA" 1 "Active" 0 "Inactive" ;
VAL_ 2499763044 BATT_05_event_outlt_clnt_thrm_op 3 "Error" 2 "SNA" 1 "Active" 0 "Inactive" ;
VAL_ 2499763044 BATT_05_event_neg_3_3_analog_err 3 "Error" 2 "SNA" 1 "Active" 0 "Inactive" ;
VAL_ 2499763044 BATT_05_event_inlet_clnt_thrm_op 3 "Error" 2 "SNA" 1 "Active" 0 "Inactive" ;
VAL_ 2499763044 BATT_05_event_hall_eff_lo_rang_e 3 "Error" 2 "SNA" 1 "Active" 0 "Inactive" ;
VAL_ 2499763044 BATT_05_event_outlt_clnt_thrm_sh 3 "Error" 2 "SNA" 1 "Active" 0 "Inactive" ;
VAL_ 2499763044 BATT_05_event_inlet_clnt_thrm_sh 3 "Error" 2 "SNA" 1 "Active" 0 "Inactive" ;
VAL_ 2499763044 BATT_05_event_3_3v_error 3 "Error" 2 "SNA" 1 "Active" 0 "Inactive" ;
VAL_ 2499763044 BATT_06_HVILvoltageError 3 "Error" 2 "SNA" 1 "Active" 0 "Inactive" ;
VAL_ 2499763044 BATT_06_HVILcurrentReturnError 3 "Error" 2 "SNA" 1 "Active" 0 "Inactive" ;
VAL_ 2499763044 BATT_06_PosDcContWeldedSec 3 "Error" 2 "SNA" 1 "Active" 0 "Inactive" ;
VAL_ 2499763044 BATT_06_PosDcContStuckOpenSec 3 "Error" 2 "SNA" 1 "Active" 0 "Inactive" ;
VAL_ 2499763044 BATT_06_NegDcContWeldedSec 3 "Error" 2 "SNA" 1 "Active" 0 "Inactive" ;
VAL_ 2499763044 BATT_06_NegDcContStuckOpenSec 3 "Error" 2 "SNA" 1 "Active" 0 "Inactive" ;
VAL_ 2499763044 BATT_06_IsolationIntFault 3 "Error" 2 "SNA" 1 "Active" 0 "Inactive" ;
VAL_ 2499763044 BATT_06_IsolationExtFault 3 "Error" 2 "SNA" 1 "Active" 0 "Inactive" ;
VAL_ 2499763044 BATT_06_event_12v_filter_error 3 "Error" 2 "SNA" 1 "Active" 0 "Inactive" ;
VAL_ 2499763044 BATT_06_event_hall_eff_hi_rang_e 3 "Error" 2 "SNA" 1 "Active" 0 "Inactive" ;
VAL_ 2499763044 BATT_06_event_brick_volt_sns_ope 3 "Error" 2 "SNA" 1 "Active" 0 "Inactive" ;
VAL_ 2499763044 BATT_06_event_5v_error 3 "Error" 2 "SNA" 1 "Active" 0 "Inactive" ;
VAL_ 2499763044 BATT_06_event_3_3_hot_error 3 "Error" 2 "SNA" 1 "Active" 0 "Inactive" ;
VAL_ 2499763044 BATT_06_event_12v_input_error 3 "Error" 2 "SNA" 1 "Active" 0 "Inactive" ;
VAL_ 2499763044 BATT_06_event_1_25v_error 3 "Error" 2 "SNA" 1 "Active" 0 "Inactive" ;
VAL_ 2499763044 BATT_06_event_shunt_MIA 3 "Error" 2 "SNA" 1 "Active" 0 "Inactive" ;
VAL_ 2499763044 BATT_06_event_SBC_int_reg_error 3 "Error" 2 "SNA" 1 "Active" 0 "Inactive" ;
VAL_ 2499763044 BATT_06_event_pos_3_3v_analog_er 3 "Error" 2 "SNA" 1 "Active" 0 "Inactive" ;
VAL_ 2499763044 BATT_06_event_outlt_clnt_thrm_op 3 "Error" 2 "SNA" 1 "Active" 0 "Inactive" ;
VAL_ 2499763044 BATT_06_event_neg_3_3_analog_err 3 "Error" 2 "SNA" 1 "Active" 0 "Inactive" ;
VAL_ 2499763044 BATT_06_event_inlet_clnt_thrm_op 3 "Error" 2 "SNA" 1 "Active" 0 "Inactive" ;
VAL_ 2499763044 BATT_06_event_hall_eff_lo_rang_e 3 "Error" 2 "SNA" 1 "Active" 0 "Inactive" ;
VAL_ 2499763044 BATT_06_event_outlt_clnt_thrm_sh 3 "Error" 2 "SNA" 1 "Active" 0 "Inactive" ;
VAL_ 2499763044 BATT_06_event_inlet_clnt_thrm_sh 3 "Error" 2 "SNA" 1 "Active" 0 "Inactive" ;
VAL_ 2499763044 BATT_06_event_3_3v_error 3 "Error" 2 "SNA" 1 "Active" 0 "Inactive" ;
VAL_ 2499763044 BATT_07_HVILvoltageError 3 "Error" 2 "SNA" 1 "Active" 0 "Inactive" ;
VAL_ 2499763044 BATT_07_HVILcurrentReturnError 3 "Error" 2 "SNA" 1 "Active" 0 "Inactive" ;
VAL_ 2499763044 BATT_07_PosDcContWeldedSec 3 "Error" 2 "SNA" 1 "Active" 0 "Inactive" ;
VAL_ 2499763044 BATT_07_PosDcContStuckOpenSec 3 "Error" 2 "SNA" 1 "Active" 0 "Inactive" ;
VAL_ 2499763044 BATT_07_NegDcContWeldedSec 3 "Error" 2 "SNA" 1 "Active" 0 "Inactive" ;
VAL_ 2499763044 BATT_07_NegDcContStuckOpenSec 3 "Error" 2 "SNA" 1 "Active" 0 "Inactive" ;
VAL_ 2499763044 BATT_07_IsolationIntFault 3 "Error" 2 "SNA" 1 "Active" 0 "Inactive" ;
VAL_ 2499763044 BATT_07_IsolationExtFault 3 "Error" 2 "SNA" 1 "Active" 0 "Inactive" ;
VAL_ 2499763044 BATT_07_event_12v_filter_error 3 "Error" 2 "SNA" 1 "Active" 0 "Inactive" ;
VAL_ 2499763044 BATT_07_event_hall_eff_hi_rang_e 3 "Error" 2 "SNA" 1 "Active" 0 "Inactive" ;
VAL_ 2499763044 BATT_07_event_brick_volt_sns_ope 3 "Error" 2 "SNA" 1 "Active" 0 "Inactive" ;
VAL_ 2499763044 BATT_07_event_5v_error 3 "Error" 2 "SNA" 1 "Active" 0 "Inactive" ;
VAL_ 2499763044 BATT_07_event_3_3_hot_error 3 "Error" 2 "SNA" 1 "Active" 0 "Inactive" ;
VAL_ 2499763044 BATT_07_event_12v_input_error 3 "Error" 2 "SNA" 1 "Active" 0 "Inactive" ;
VAL_ 2499763044 BATT_07_event_1_25v_error 3 "Error" 2 "SNA" 1 "Active" 0 "Inactive" ;
VAL_ 2499763044 BATT_07_event_shunt_MIA 3 "Error" 2 "SNA" 1 "Active" 0 "Inactive" ;
VAL_ 2499763044 BATT_07_event_SBC_int_reg_error 3 "Error" 2 "SNA" 1 "Active" 0 "Inactive" ;
VAL_ 2499763044 BATT_07_event_pos_3_3v_analog_er 3 "Error" 2 "SNA" 1 "Active" 0 "Inactive" ;
VAL_ 2499763044 BATT_07_event_outlt_clnt_thrm_op 3 "Error" 2 "SNA" 1 "Active" 0 "Inactive" ;
VAL_ 2499763044 BATT_07_event_neg_3_3_analog_err 3 "Error" 2 "SNA" 1 "Active" 0 "Inactive" ;
VAL_ 2499763044 BATT_07_event_inlet_clnt_thrm_op 3 "Error" 2 "SNA" 1 "Active" 0 "Inactive" ;
VAL_ 2499763044 BATT_07_event_hall_eff_lo_rang_e 3 "Error" 2 "SNA" 1 "Active" 0 "Inactive" ;
VAL_ 2499763044 BATT_07_event_outlt_clnt_thrm_sh 3 "Error" 2 "SNA" 1 "Active" 0 "Inactive" ;
VAL_ 2499763044 BATT_07_event_inlet_clnt_thrm_sh 3 "Error" 2 "SNA" 1 "Active" 0 "Inactive" ;
VAL_ 2499763044 BATT_07_event_3_3v_error 3 "Error" 2 "SNA" 1 "Active" 0 "Inactive" ;
VAL_ 2499763044 BATT_08_HVILvoltageError 3 "Error" 2 "SNA" 1 "Active" 0 "Inactive" ;
VAL_ 2499763044 BATT_08_HVILcurrentReturnError 3 "Error" 2 "SNA" 1 "Active" 0 "Inactive" ;
VAL_ 2499763044 BATT_08_PosDcContWeldedSec 3 "Error" 2 "SNA" 1 "Active" 0 "Inactive" ;
VAL_ 2499763044 BATT_08_PosDcContStuckOpenSec 3 "Error" 2 "SNA" 1 "Active" 0 "Inactive" ;
VAL_ 2499763044 BATT_08_NegDcContWeldedSec 3 "Error" 2 "SNA" 1 "Active" 0 "Inactive" ;
VAL_ 2499763044 BATT_08_NegDcContStuckOpenSec 3 "Error" 2 "SNA" 1 "Active" 0 "Inactive" ;
VAL_ 2499763044 BATT_08_IsolationIntFault 3 "Error" 2 "SNA" 1 "Active" 0 "Inactive" ;
VAL_ 2499763044 BATT_08_IsolationExtFault 3 "Error" 2 "SNA" 1 "Active" 0 "Inactive" ;
VAL_ 2499763044 BATT_08_event_12v_filter_error 3 "Error" 2 "SNA" 1 "Active" 0 "Inactive" ;
VAL_ 2499763044 BATT_08_event_hall_eff_hi_rang_e 3 "Error" 2 "SNA" 1 "Active" 0 "Inactive" ;
VAL_ 2499763044 BATT_08_event_brick_volt_sns_ope 3 "Error" 2 "SNA" 1 "Active" 0 "Inactive" ;
VAL_ 2499763044 BATT_08_event_5v_error 3 "Error" 2 "SNA" 1 "Active" 0 "Inactive" ;
VAL_ 2499763044 BATT_08_event_3_3_hot_error 3 "Error" 2 "SNA" 1 "Active" 0 "Inactive" ;
VAL_ 2499763044 BATT_08_event_12v_input_error 3 "Error" 2 "SNA" 1 "Active" 0 "Inactive" ;
VAL_ 2499763044 BATT_08_event_1_25v_error 3 "Error" 2 "SNA" 1 "Active" 0 "Inactive" ;
VAL_ 2499763044 BATT_08_event_shunt_MIA 3 "Error" 2 "SNA" 1 "Active" 0 "Inactive" ;
VAL_ 2499763044 BATT_08_event_SBC_int_reg_error 3 "Error" 2 "SNA" 1 "Active" 0 "Inactive" ;
VAL_ 2499763044 BATT_08_event_pos_3_3v_analog_er 3 "Error" 2 "SNA" 1 "Active" 0 "Inactive" ;
VAL_ 2499763044 BATT_08_event_outlt_clnt_thrm_op 3 "Error" 2 "SNA" 1 "Active" 0 "Inactive" ;
VAL_ 2499763044 BATT_08_event_neg_3_3_analog_err 3 "Error" 2 "SNA" 1 "Active" 0 "Inactive" ;
VAL_ 2499763044 BATT_08_event_inlet_clnt_thrm_op 3 "Error" 2 "SNA" 1 "Active" 0 "Inactive" ;
VAL_ 2499763044 BATT_08_event_hall_eff_lo_rang_e 3 "Error" 2 "SNA" 1 "Active" 0 "Inactive" ;
VAL_ 2499763044 BATT_08_event_outlt_clnt_thrm_sh 3 "Error" 2 "SNA" 1 "Active" 0 "Inactive" ;
VAL_ 2499763044 BATT_08_event_inlet_clnt_thrm_sh 3 "Error" 2 "SNA" 1 "Active" 0 "Inactive" ;
VAL_ 2499763044 BATT_08_event_3_3v_error 3 "Error" 2 "SNA" 1 "Active" 0 "Inactive" ;
VAL_ 2499763044 BATT_09_HVILvoltageError 3 "Error" 2 "SNA" 1 "Active" 0 "Inactive" ;
VAL_ 2499763044 BATT_09_HVILcurrentReturnError 3 "Error" 2 "SNA" 1 "Active" 0 "Inactive" ;
VAL_ 2499763044 BATT_09_PosDcContWeldedSec 3 "Error" 2 "SNA" 1 "Active" 0 "Inactive" ;
VAL_ 2499763044 BATT_09_NegDcContWeldedSec 3 "Error" 2 "SNA" 1 "Active" 0 "Inactive" ;
VAL_ 2499763044 BATT_09_NegDcContStuckOpenSec 3 "Error" 2 "SNA" 1 "Active" 0 "Inactive" ;
VAL_ 2499763044 BATT_09_PosDcContStuckOpenSec 3 "Error" 2 "SNA" 1 "Active" 0 "Inactive" ;
VAL_ 2499763044 BATT_09_IsolationIntFault 3 "Error" 2 "SNA" 1 "Active" 0 "Inactive" ;
VAL_ 2499763044 BATT_09_IsolationExtFault 3 "Error" 2 "SNA" 1 "Active" 0 "Inactive" ;
VAL_ 2499763044 BATT_09_event_12v_filter_error 3 "Error" 2 "SNA" 1 "Active" 0 "Inactive" ;
VAL_ 2499763044 BATT_09_event_hall_eff_hi_rang_e 3 "Error" 2 "SNA" 1 "Active" 0 "Inactive" ;
VAL_ 2499763044 BATT_09_event_brick_volt_sns_ope 3 "Error" 2 "SNA" 1 "Active" 0 "Inactive" ;
VAL_ 2499763044 BATT_09_event_5v_error 3 "Error" 2 "SNA" 1 "Active" 0 "Inactive" ;
VAL_ 2499763044 BATT_09_event_3_3_hot_error 3 "Error" 2 "SNA" 1 "Active" 0 "Inactive" ;
VAL_ 2499763044 BATT_09_event_12v_input_error 3 "Error" 2 "SNA" 1 "Active" 0 "Inactive" ;
VAL_ 2499763044 BATT_09_event_1_25v_error 3 "Error" 2 "SNA" 1 "Active" 0 "Inactive" ;
VAL_ 2499763044 BATT_09_event_shunt_MIA 3 "Error" 2 "SNA" 1 "Active" 0 "Inactive" ;
VAL_ 2499763044 BATT_09_event_SBC_int_reg_error 3 "Error" 2 "SNA" 1 "Active" 0 "Inactive" ;
VAL_ 2499763044 BATT_09_event_pos_3_3v_analog_er 3 "Error" 2 "SNA" 1 "Active" 0 "Inactive" ;
VAL_ 2499763044 BATT_09_event_outlt_clnt_thrm_op 3 "Error" 2 "SNA" 1 "Active" 0 "Inactive" ;
VAL_ 2499763044 BATT_09_event_neg_3_3_analog_err 3 "Error" 2 "SNA" 1 "Active" 0 "Inactive" ;
VAL_ 2499763044 BATT_09_event_inlet_clnt_thrm_op 3 "Error" 2 "SNA" 1 "Active" 0 "Inactive" ;
VAL_ 2499763044 BATT_09_event_hall_eff_lo_rang_e 3 "Error" 2 "SNA" 1 "Active" 0 "Inactive" ;
VAL_ 2499763044 BATT_09_event_outlt_clnt_thrm_sh 3 "Error" 2 "SNA" 1 "Active" 0 "Inactive" ;
VAL_ 2499763044 BATT_09_event_inlet_clnt_thrm_sh 3 "Error" 2 "SNA" 1 "Active" 0 "Inactive" ;
VAL_ 2499763044 BATT_09_event_3_3v_error 3 "Error" 2 "SNA" 1 "Active" 0 "Inactive" ;
VAL_ 2499763044 BATT_10_HVILvoltageError 3 "Error" 2 "SNA" 1 "Active" 0 "Inactive" ;
VAL_ 2499763044 BATT_10_HVILcurrentReturnError 3 "Error" 2 "SNA" 1 "Active" 0 "Inactive" ;
VAL_ 2499763044 BATT_10_PosDcContWeldedSec 3 "Error" 2 "SNA" 1 "Active" 0 "Inactive" ;
VAL_ 2499763044 BATT_10_PosDcContStuckOpenSec 3 "Error" 2 "SNA" 1 "Active" 0 "Inactive" ;
VAL_ 2499763044 BATT_10_NegDcContWeldedSec 3 "Error" 2 "SNA" 1 "Active" 0 "Inactive" ;
VAL_ 2499763044 BATT_10_NegDcContStuckOpenSec 3 "Error" 2 "SNA" 1 "Active" 0 "Inactive" ;
VAL_ 2499763044 BATT_10_IsolationIntFault 3 "Error" 2 "SNA" 1 "Active" 0 "Inactive" ;
VAL_ 2499763044 BATT_10_IsolationExtFault 3 "Error" 2 "SNA" 1 "Active" 0 "Inactive" ;
VAL_ 2499763044 BATT_10_event_12v_filter_error 3 "Error" 2 "SNA" 1 "Active" 0 "Inactive" ;
VAL_ 2499763044 BATT_10_event_hall_eff_hi_rang_e 3 "Error" 2 "SNA" 1 "Active" 0 "Inactive" ;
VAL_ 2499763044 BATT_10_event_brick_volt_sns_ope 3 "Error" 2 "SNA" 1 "Active" 0 "Inactive" ;
VAL_ 2499763044 BATT_10_event_5v_error 3 "Error" 2 "SNA" 1 "Active" 0 "Inactive" ;
VAL_ 2499763044 BATT_10_event_3_3_hot_error 3 "Error" 2 "SNA" 1 "Active" 0 "Inactive" ;
VAL_ 2499763044 BATT_10_event_12v_input_error 3 "Error" 2 "SNA" 1 "Active" 0 "Inactive" ;
VAL_ 2499763044 BATT_10_event_1_25v_error 3 "Error" 2 "SNA" 1 "Active" 0 "Inactive" ;
VAL_ 2499763044 BATT_10_event_shunt_MIA 3 "Error" 2 "SNA" 1 "Active" 0 "Inactive" ;
VAL_ 2499763044 BATT_10_event_SBC_int_reg_error 3 "Error" 2 "SNA" 1 "Active" 0 "Inactive" ;
VAL_ 2499763044 BATT_10_event_pos_3_3v_analog_er 3 "Error" 2 "SNA" 1 "Active" 0 "Inactive" ;
VAL_ 2499763044 BATT_10_event_outlt_clnt_thrm_op 3 "Error" 2 "SNA" 1 "Active" 0 "Inactive" ;
VAL_ 2499763044 BATT_10_event_neg_3_3_analog_err 3 "Error" 2 "SNA" 1 "Active" 0 "Inactive" ;
VAL_ 2499763044 BATT_10_event_inlet_clnt_thrm_op 3 "Error" 2 "SNA" 1 "Active" 0 "Inactive" ;
VAL_ 2499763044 BATT_10_event_hall_eff_lo_rang_e 3 "Error" 2 "SNA" 1 "Active" 0 "Inactive" ;
VAL_ 2499763044 BATT_10_event_outlt_clnt_thrm_sh 3 "Error" 2 "SNA" 1 "Active" 0 "Inactive" ;
VAL_ 2499763044 BATT_10_event_inlet_clnt_thrm_sh 3 "Error" 2 "SNA" 1 "Active" 0 "Inactive" ;
VAL_ 2499763044 BATT_10_event_3_3v_error 3 "Error" 2 "SNA" 1 "Active" 0 "Inactive" ;
VAL_ 2499763044 BATT_11_HVILvoltageError 3 "Error" 2 "SNA" 1 "Active" 0 "Inactive" ;
VAL_ 2499763044 BATT_11_HVILcurrentReturnError 3 "Error" 2 "SNA" 1 "Active" 0 "Inactive" ;
VAL_ 2499763044 BATT_11_PosDcContWeldedSec 3 "Error" 2 "SNA" 1 "Active" 0 "Inactive" ;
VAL_ 2499763044 BATT_11_PosDcContStuckOpenSec 3 "Error" 2 "SNA" 1 "Active" 0 "Inactive" ;
VAL_ 2499763044 BATT_11_NegDcContWeldedSec 3 "Error" 2 "SNA" 1 "Active" 0 "Inactive" ;
VAL_ 2499763044 BATT_11_NegDcContStuckOpenSec 3 "Error" 2 "SNA" 1 "Active" 0 "Inactive" ;
VAL_ 2499763044 BATT_11_IsolationIntFault 3 "Error" 2 "SNA" 1 "Active" 0 "Inactive" ;
VAL_ 2499763044 BATT_11_IsolationExtFault 3 "Error" 2 "SNA" 1 "Active" 0 "Inactive" ;
VAL_ 2499763044 BATT_11_event_12v_filter_error 3 "Error" 2 "SNA" 1 "Active" 0 "Inactive" ;
VAL_ 2499763044 BATT_11_event_hall_eff_hi_rang_e 3 "Error" 2 "SNA" 1 "Active" 0 "Inactive" ;
VAL_ 2499763044 BATT_11_event_brick_volt_sns_ope 3 "Error" 2 "SNA" 1 "Active" 0 "Inactive" ;
VAL_ 2499763044 BATT_11_event_5v_error 3 "Error" 2 "SNA" 1 "Active" 0 "Inactive" ;
VAL_ 2499763044 BATT_11_event_3_3_hot_error 3 "Error" 2 "SNA" 1 "Active" 0 "Inactive" ;
VAL_ 2499763044 BATT_11_event_12v_input_error 3 "Error" 2 "SNA" 1 "Active" 0 "Inactive" ;
VAL_ 2499763044 BATT_11_event_1_25v_error 3 "Error" 2 "SNA" 1 "Active" 0 "Inactive" ;
VAL_ 2499763044 BATT_11_event_shunt_MIA 3 "Error" 2 "SNA" 1 "Active" 0 "Inactive" ;
VAL_ 2499763044 BATT_11_event_SBC_int_reg_error 3 "Error" 2 "SNA" 1 "Active" 0 "Inactive" ;
VAL_ 2499763044 BATT_11_event_pos_3_3v_analog_er 3 "Error" 2 "SNA" 1 "Active" 0 "Inactive" ;
VAL_ 2499763044 BATT_11_event_outlt_clnt_thrm_op 3 "Error" 2 "SNA" 1 "Active" 0 "Inactive" ;
VAL_ 2499763044 BATT_11_event_neg_3_3_analog_err 3 "Error" 2 "SNA" 1 "Active" 0 "Inactive" ;
VAL_ 2499763044 BATT_11_event_inlet_clnt_thrm_op 3 "Error" 2 "SNA" 1 "Active" 0 "Inactive" ;
VAL_ 2499763044 BATT_11_event_hall_eff_lo_rang_e 3 "Error" 2 "SNA" 1 "Active" 0 "Inactive" ;
VAL_ 2499763044 BATT_11_event_outlt_clnt_thrm_sh 3 "Error" 2 "SNA" 1 "Active" 0 "Inactive" ;
VAL_ 2499763044 BATT_11_event_inlet_clnt_thrm_sh 3 "Error" 2 "SNA" 1 "Active" 0 "Inactive" ;
VAL_ 2499763044 BATT_11_event_3_3v_error 3 "Error" 2 "SNA" 1 "Active" 0 "Inactive" ;
VAL_ 2499763044 BATT_12_HVILvoltageError 3 "Error" 2 "SNA" 1 "Active" 0 "Inactive" ;
VAL_ 2499763044 BATT_12_HVILcurrentReturnError 3 "Error" 2 "SNA" 1 "Active" 0 "Inactive" ;
VAL_ 2499763044 BATT_12_PosDcContWeldedSec 3 "Error" 2 "SNA" 1 "Active" 0 "Inactive" ;
VAL_ 2499763044 BATT_12_PosDcContStuckOpenSec 3 "Error" 2 "SNA" 1 "Active" 0 "Inactive" ;
VAL_ 2499763044 BATT_12_NegDcContWeldedSec 3 "Error" 2 "SNA" 1 "Active" 0 "Inactive" ;
VAL_ 2499763044 BATT_12_NegDcContStuckOpenSec 3 "Error" 2 "SNA" 1 "Active" 0 "Inactive" ;
VAL_ 2499763044 BATT_12_IsolationIntFault 3 "Error" 2 "SNA" 1 "Active" 0 "Inactive" ;
VAL_ 2499763044 BATT_12_IsolationExtFault 3 "Error" 2 "SNA" 1 "Active" 0 "Inactive" ;
VAL_ 2499763044 BATT_12_event_12v_filter_error 3 "Error" 2 "SNA" 1 "Active" 0 "Inactive" ;
VAL_ 2499763044 BATT_12_event_hall_eff_hi_rang_e 3 "Error" 2 "SNA" 1 "Active" 0 "Inactive" ;
VAL_ 2499763044 BATT_12_event_brick_volt_sns_ope 3 "Error" 2 "SNA" 1 "Active" 0 "Inactive" ;
VAL_ 2499763044 BATT_12_event_5v_error 3 "Error" 2 "SNA" 1 "Active" 0 "Inactive" ;
VAL_ 2499763044 BATT_12_event_3_3_hot_error 3 "Error" 2 "SNA" 1 "Active" 0 "Inactive" ;
VAL_ 2499763044 BATT_12_event_12v_input_error 3 "Error" 2 "SNA" 1 "Active" 0 "Inactive" ;
VAL_ 2499763044 BATT_12_event_1_25v_error 3 "Error" 2 "SNA" 1 "Active" 0 "Inactive" ;
VAL_ 2499763044 BATT_12_event_shunt_MIA 3 "Error" 2 "SNA" 1 "Active" 0 "Inactive" ;
VAL_ 2499763044 BATT_12_event_SBC_int_reg_error 3 "Error" 2 "SNA" 1 "Active" 0 "Inactive" ;
VAL_ 2499763044 BATT_12_event_pos_3_3v_analog_er 3 "Error" 2 "SNA" 1 "Active" 0 "Inactive" ;
VAL_ 2499763044 BATT_12_event_outlt_clnt_thrm_op 3 "Error" 2 "SNA" 1 "Active" 0 "Inactive" ;
VAL_ 2499763044 BATT_12_event_neg_3_3_analog_err 3 "Error" 2 "SNA" 1 "Active" 0 "Inactive" ;
VAL_ 2499763044 BATT_12_event_inlet_clnt_thrm_op 3 "Error" 2 "SNA" 1 "Active" 0 "Inactive" ;
VAL_ 2499763044 BATT_12_event_hall_eff_lo_rang_e 3 "Error" 2 "SNA" 1 "Active" 0 "Inactive" ;
VAL_ 2499763044 BATT_12_event_outlt_clnt_thrm_sh 3 "Error" 2 "SNA" 1 "Active" 0 "Inactive" ;
VAL_ 2499763044 BATT_12_event_inlet_clnt_thrm_sh 3 "Error" 2 "SNA" 1 "Active" 0 "Inactive" ;
VAL_ 2499763044 BATT_12_event_3_3v_error 3 "Error" 2 "SNA" 1 "Active" 0 "Inactive" ;
VAL_ 2499763044 BATT_13_HVILvoltageError 3 "Error" 2 "SNA" 1 "Active" 0 "Inactive" ;
VAL_ 2499763044 BATT_13_HVILcurrentReturnError 3 "Error" 2 "SNA" 1 "Active" 0 "Inactive" ;
VAL_ 2499763044 BATT_13_PosDcContWeldedSec 3 "Error" 2 "SNA" 1 "Active" 0 "Inactive" ;
VAL_ 2499763044 BATT_13_PosDcContStuckOpenSec 3 "Error" 2 "SNA" 1 "Active" 0 "Inactive" ;
VAL_ 2499763044 BATT_13_NegDcContWeldedSec 3 "Error" 2 "SNA" 1 "Active" 0 "Inactive" ;
VAL_ 2499763044 BATT_13_NegDcContStuckOpenSec 3 "Error" 2 "SNA" 1 "Active" 0 "Inactive" ;
VAL_ 2499763044 BATT_13_IsolationIntFault 3 "Error" 2 "SNA" 1 "Active" 0 "Inactive" ;
VAL_ 2499763044 BATT_13_IsolationExtFault 3 "Error" 2 "SNA" 1 "Active" 0 "Inactive" ;
VAL_ 2499763044 BATT_13_event_12v_filter_error 3 "Error" 2 "SNA" 1 "Active" 0 "Inactive" ;
VAL_ 2499763044 BATT_13_event_hall_eff_hi_rang_e 3 "Error" 2 "SNA" 1 "Active" 0 "Inactive" ;
VAL_ 2499763044 BATT_13_event_brick_volt_sns_ope 3 "Error" 2 "SNA" 1 "Active" 0 "Inactive" ;
VAL_ 2499763044 BATT_13_event_5v_error 3 "Error" 2 "SNA" 1 "Active" 0 "Inactive" ;
VAL_ 2499763044 BATT_13_event_3_3_hot_error 3 "Error" 2 "SNA" 1 "Active" 0 "Inactive" ;
VAL_ 2499763044 BATT_13_event_12v_input_error 3 "Error" 2 "SNA" 1 "Active" 0 "Inactive" ;
VAL_ 2499763044 BATT_13_event_1_25v_error 3 "Error" 2 "SNA" 1 "Active" 0 "Inactive" ;
VAL_ 2499763044 BATT_13_event_shunt_MIA 3 "Error" 2 "SNA" 1 "Active" 0 "Inactive" ;
VAL_ 2499763044 BATT_13_event_SBC_int_reg_error 3 "Error" 2 "SNA" 1 "Active" 0 "Inactive" ;
VAL_ 2499763044 BATT_13_event_pos_3_3v_analog_er 3 "Error" 2 "SNA" 1 "Active" 0 "Inactive" ;
VAL_ 2499763044 BATT_13_event_outlt_clnt_thrm_op 3 "Error" 2 "SNA" 1 "Active" 0 "Inactive" ;
VAL_ 2499763044 BATT_13_event_neg_3_3_analog_err 3 "Error" 2 "SNA" 1 "Active" 0 "Inactive" ;
VAL_ 2499763044 BATT_13_event_inlet_clnt_thrm_op 3 "Error" 2 "SNA" 1 "Active" 0 "Inactive" ;
VAL_ 2499763044 BATT_13_event_hall_eff_lo_rang_e 3 "Error" 2 "SNA" 1 "Active" 0 "Inactive" ;
VAL_ 2499763044 BATT_13_event_outlt_clnt_thrm_sh 3 "Error" 2 "SNA" 1 "Active" 0 "Inactive" ;
VAL_ 2499763044 BATT_13_event_inlet_clnt_thrm_sh 3 "Error" 2 "SNA" 1 "Active" 0 "Inactive" ;
VAL_ 2499763044 BATT_13_event_3_3v_error 3 "Error" 2 "SNA" 1 "Active" 0 "Inactive" ;
VAL_ 2499763044 BATT_14_HVILvoltageError 3 "Error" 2 "SNA" 1 "Active" 0 "Inactive" ;
VAL_ 2499763044 BATT_14_HVILcurrentReturnError 3 "Error" 2 "SNA" 1 "Active" 0 "Inactive" ;
VAL_ 2499763044 BATT_14_PosDcContWeldedSec 3 "Error" 2 "SNA" 1 "Active" 0 "Inactive" ;
VAL_ 2499763044 BATT_14_PosDcContStuckOpenSec 3 "Error" 2 "SNA" 1 "Active" 0 "Inactive" ;
VAL_ 2499763044 BATT_14_NegDcContWeldedSec 3 "Error" 2 "SNA" 1 "Active" 0 "Inactive" ;
VAL_ 2499763044 BATT_14_NegDcContStuckOpenSec 3 "Error" 2 "SNA" 1 "Active" 0 "Inactive" ;
VAL_ 2499763044 BATT_14_IsolationIntFault 3 "Error" 2 "SNA" 1 "Active" 0 "Inactive" ;
VAL_ 2499763044 BATT_14_IsolationExtFault 3 "Error" 2 "SNA" 1 "Active" 0 "Inactive" ;
VAL_ 2499763044 BATT_14_event_12v_filter_error 3 "Error" 2 "SNA" 1 "Active" 0 "Inactive" ;
VAL_ 2499763044 BATT_14_event_hall_eff_hi_rang_e 3 "Error" 2 "SNA" 1 "Active" 0 "Inactive" ;
VAL_ 2499763044 BATT_14_event_brick_volt_sns_ope 3 "Error" 2 "SNA" 1 "Active" 0 "Inactive" ;
VAL_ 2499763044 BATT_14_event_5v_error 3 "Error" 2 "SNA" 1 "Active" 0 "Inactive" ;
VAL_ 2499763044 BATT_14_event_3_3_hot_error 3 "Error" 2 "SNA" 1 "Active" 0 "Inactive" ;
VAL_ 2499763044 BATT_14_event_12v_input_error 3 "Error" 2 "SNA" 1 "Active" 0 "Inactive" ;
VAL_ 2499763044 BATT_14_event_1_25v_error 3 "Error" 2 "SNA" 1 "Active" 0 "Inactive" ;
VAL_ 2499763044 BATT_14_event_shunt_MIA 3 "Error" 2 "SNA" 1 "Active" 0 "Inactive" ;
VAL_ 2499763044 BATT_14_event_SBC_int_reg_error 3 "Error" 2 "SNA" 1 "Active" 0 "Inactive" ;
VAL_ 2499763044 BATT_14_event_pos_3_3v_analog_er 3 "Error" 2 "SNA" 1 "Active" 0 "Inactive" ;
VAL_ 2499763044 BATT_14_event_outlt_clnt_thrm_op 3 "Error" 2 "SNA" 1 "Active" 0 "Inactive" ;
VAL_ 2499763044 BATT_14_event_neg_3_3_analog_err 3 "Error" 2 "SNA" 1 "Active" 0 "Inactive" ;
VAL_ 2499763044 BATT_14_event_inlet_clnt_thrm_op 3 "Error" 2 "SNA" 1 "Active" 0 "Inactive" ;
VAL_ 2499763044 BATT_14_event_hall_eff_lo_rang_e 3 "Error" 2 "SNA" 1 "Active" 0 "Inactive" ;
VAL_ 2499763044 BATT_14_event_outlt_clnt_thrm_sh 3 "Error" 2 "SNA" 1 "Active" 0 "Inactive" ;
VAL_ 2499763044 BATT_14_event_inlet_clnt_thrm_sh 3 "Error" 2 "SNA" 1 "Active" 0 "Inactive" ;
VAL_ 2499763044 BATT_14_event_3_3v_error 3 "Error" 2 "SNA" 1 "Active" 0 "Inactive" ;
VAL_ 2499763044 BATT_15_HVILvoltageError 3 "Error" 2 "SNA" 1 "Active" 0 "Inactive" ;
VAL_ 2499763044 BATT_15_HVILcurrentReturnError 3 "Error" 2 "SNA" 1 "Active" 0 "Inactive" ;
VAL_ 2499763044 BATT_15_PosDcContWeldedSec 3 "Error" 2 "SNA" 1 "Active" 0 "Inactive" ;
VAL_ 2499763044 BATT_15_PosDcContStuckOpenSec 3 "Error" 2 "SNA" 1 "Active" 0 "Inactive" ;
VAL_ 2499763044 BATT_15_NegDcContWeldedSec 3 "Error" 2 "SNA" 1 "Active" 0 "Inactive" ;
VAL_ 2499763044 BATT_15_NegDcContStuckOpenSec 3 "Error" 2 "SNA" 1 "Active" 0 "Inactive" ;
VAL_ 2499763044 BATT_15_IsolationIntFault 3 "Error" 2 "SNA" 1 "Active" 0 "Inactive" ;
VAL_ 2499763044 BATT_15_IsolationExtFault 3 "Error" 2 "SNA" 1 "Active" 0 "Inactive" ;
VAL_ 2499763044 BATT_15_event_12v_filter_error 3 "Error" 2 "SNA" 1 "Active" 0 "Inactive" ;
VAL_ 2499763044 BATT_15_event_hall_eff_hi_rang_e 3 "Error" 2 "SNA" 1 "Active" 0 "Inactive" ;
VAL_ 2499763044 BATT_15_event_brick_volt_sns_ope 3 "Error" 2 "SNA" 1 "Active" 0 "Inactive" ;
VAL_ 2499763044 BATT_15_event_5v_error 3 "Error" 2 "SNA" 1 "Active" 0 "Inactive" ;
VAL_ 2499763044 BATT_15_event_3_3_hot_error 3 "Error" 2 "SNA" 1 "Active" 0 "Inactive" ;
VAL_ 2499763044 BATT_15_event_12v_input_error 3 "Error" 2 "SNA" 1 "Active" 0 "Inactive" ;
VAL_ 2499763044 BATT_15_event_1_25v_error 3 "Error" 2 "SNA" 1 "Active" 0 "Inactive" ;
VAL_ 2499763044 BATT_15_event_shunt_MIA 3 "Error" 2 "SNA" 1 "Active" 0 "Inactive" ;
VAL_ 2499763044 BATT_15_event_SBC_int_reg_error 3 "Error" 2 "SNA" 1 "Active" 0 "Inactive" ;
VAL_ 2499763044 BATT_15_event_pos_3_3v_analog_er 3 "Error" 2 "SNA" 1 "Active" 0 "Inactive" ;
VAL_ 2499763044 BATT_15_event_outlt_clnt_thrm_op 3 "Error" 2 "SNA" 1 "Active" 0 "Inactive" ;
VAL_ 2499763044 BATT_15_event_neg_3_3_analog_err 3 "Error" 2 "SNA" 1 "Active" 0 "Inactive" ;
VAL_ 2499763044 BATT_15_event_inlet_clnt_thrm_op 3 "Error" 2 "SNA" 1 "Active" 0 "Inactive" ;
VAL_ 2499763044 BATT_15_event_hall_eff_lo_rang_e 3 "Error" 2 "SNA" 1 "Active" 0 "Inactive" ;
VAL_ 2499763044 BATT_15_event_outlt_clnt_thrm_sh 3 "Error" 2 "SNA" 1 "Active" 0 "Inactive" ;
VAL_ 2499763044 BATT_15_event_inlet_clnt_thrm_sh 3 "Error" 2 "SNA" 1 "Active" 0 "Inactive" ;
VAL_ 2499763044 BATT_15_event_3_3v_error 3 "Error" 2 "SNA" 1 "Active" 0 "Inactive" ;
